VERSION ""

NS_ :

BS_:

BU_: CLOCK HUD H_U DATC CCP KMA_TMU CUBIS TMU IPM RSE_R RRC CGW RSE_L AMP EDT SWRC IBOX CLU FHCU ASD MON AVM KBD

BO_ 3221225472 VECTOR__INDEPENDENT_SIG_MSG: 0 Vector__XXX
 SG_ C_WHEEL_FL : 0|12@0+ (1,0) [0|0] "" Vector__XXX
 SG_ C_WHEEL_FR : 0|12@0+ (1,0) [0|0] "" Vector__XXX
 SG_ C_WHEEL_RL : 0|12@0+ (1,0) [0|0] "" Vector__XXX
 SG_ C_WHEEL_RR : 0|12@0+ (1,0) [0|0] "" Vector__XXX

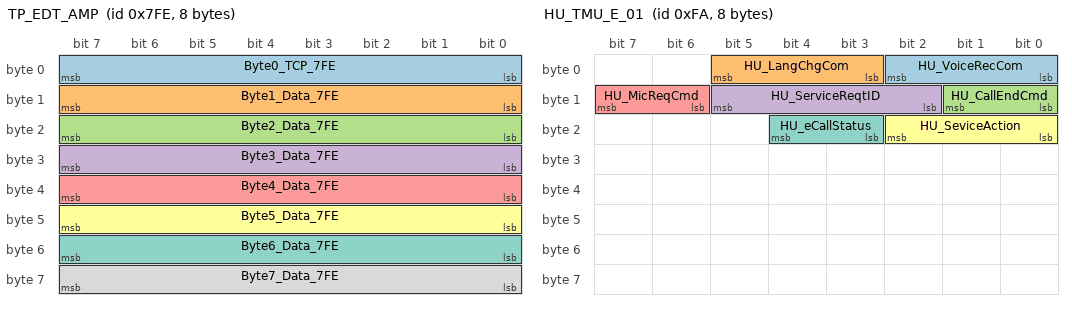
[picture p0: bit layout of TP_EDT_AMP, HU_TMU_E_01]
BO_ 2046 TP_EDT_AMP: 8 EDT
 SG_ Byte0_TCP_7FE : 7|8@0+ (1,0) [0|0] ""  AMP
 SG_ Byte1_Data_7FE : 15|8@0+ (1,0) [0|0] ""  AMP
 SG_ Byte2_Data_7FE : 23|8@0+ (1,0) [0|0] ""  AMP
 SG_ Byte3_Data_7FE : 31|8@0+ (1,0) [0|0] ""  AMP
 SG_ Byte4_Data_7FE : 39|8@0+ (1,0) [0|0] ""  AMP
 SG_ Byte5_Data_7FE : 47|8@0+ (1,0) [0|0] ""  AMP
 SG_ Byte6_Data_7FE : 55|8@0+ (1,0) [0|0] ""  AMP
 SG_ Byte7_Data_7FE : 63|8@0+ (1,0) [0|0] ""  AMP

BO_ 251 HU_TMU_E_02: 8 H_U
 SG_ HU_GPS_Year : 7|8@0+ (1,0) [0|0] ""  CUBIS,TMU
 SG_ HU_GPS_Month : 15|8@0+ (1,0) [0|0] ""  CUBIS,TMU
 SG_ HU_GPS_Day : 23|8@0+ (1,0) [0|0] ""  CUBIS,TMU
 SG_ HU_GPS_Hour : 31|8@0+ (1,0) [0|0] ""  CUBIS,TMU
 SG_ HU_GPS_Minute : 39|8@0+ (1,0) [0|0] ""  CUBIS,TMU
 SG_ HU_GPS_Second : 47|8@0+ (1,0) [0|0] ""  CUBIS,TMU

BO_ 250 HU_TMU_E_01: 8 H_U
 SG_ HU_VoiceRecCom : 2|3@0+ (1,0) [0|0] ""  TMU
 SG_ HU_LangChgCom : 5|3@0+ (1,0) [0|0] ""  TMU
 SG_ HU_CallEndCmd : 9|2@0+ (1,0) [0|0] ""  TMU
 SG_ HU_ServiceReqtID : 13|4@0+ (1,0) [0|0] ""  TMU
 SG_ HU_MicReqCmd : 15|2@0+ (1,0) [0|0] ""  TMU
 SG_ HU_SeviceAction : 18|3@0+ (1,0) [0|0] ""  TMU
 SG_ HU_eCallStatus : 20|2@0+ (1,0) [0|0] ""  TMU

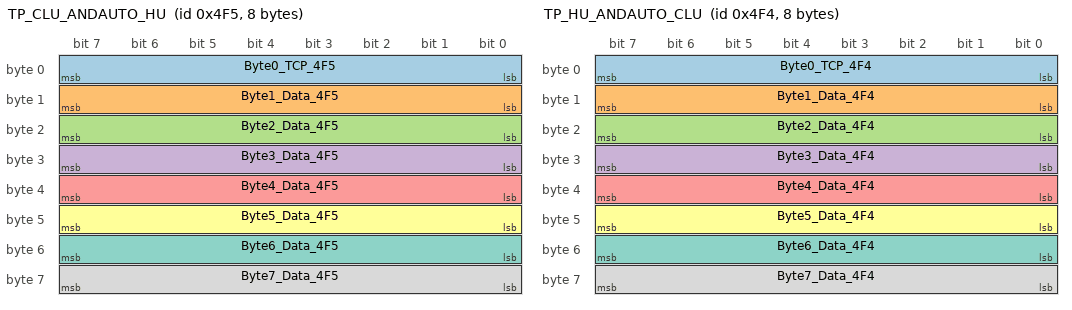
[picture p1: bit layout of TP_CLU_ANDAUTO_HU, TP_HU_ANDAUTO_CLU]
BO_ 1269 TP_CLU_ANDAUTO_HU: 8 CLU
 SG_ Byte0_TCP_4F5 : 7|8@0+ (1,0) [0|0] ""  H_U
 SG_ Byte1_Data_4F5 : 15|8@0+ (1,0) [0|0] ""  H_U
 SG_ Byte2_Data_4F5 : 23|8@0+ (1,0) [0|0] ""  H_U
 SG_ Byte3_Data_4F5 : 31|8@0+ (1,0) [0|0] ""  H_U
 SG_ Byte4_Data_4F5 : 39|8@0+ (1,0) [0|0] ""  H_U
 SG_ Byte5_Data_4F5 : 47|8@0+ (1,0) [0|0] ""  H_U
 SG_ Byte6_Data_4F5 : 55|8@0+ (1,0) [0|0] ""  H_U
 SG_ Byte7_Data_4F5 : 63|8@0+ (1,0) [0|0] ""  H_U

BO_ 1268 TP_HU_ANDAUTO_CLU: 8 H_U
 SG_ Byte0_TCP_4F4 : 7|8@0+ (1,0) [0|0] ""  CLU
 SG_ Byte1_Data_4F4 : 15|8@0+ (1,0) [0|0] ""  CLU
 SG_ Byte2_Data_4F4 : 23|8@0+ (1,0) [0|0] ""  CLU
 SG_ Byte3_Data_4F4 : 31|8@0+ (1,0) [0|0] ""  CLU
 SG_ Byte4_Data_4F4 : 39|8@0+ (1,0) [0|0] ""  CLU
 SG_ Byte5_Data_4F4 : 47|8@0+ (1,0) [0|0] ""  CLU
 SG_ Byte6_Data_4F4 : 55|8@0+ (1,0) [0|0] ""  CLU
 SG_ Byte7_Data_4F4 : 63|8@0+ (1,0) [0|0] ""  CLU

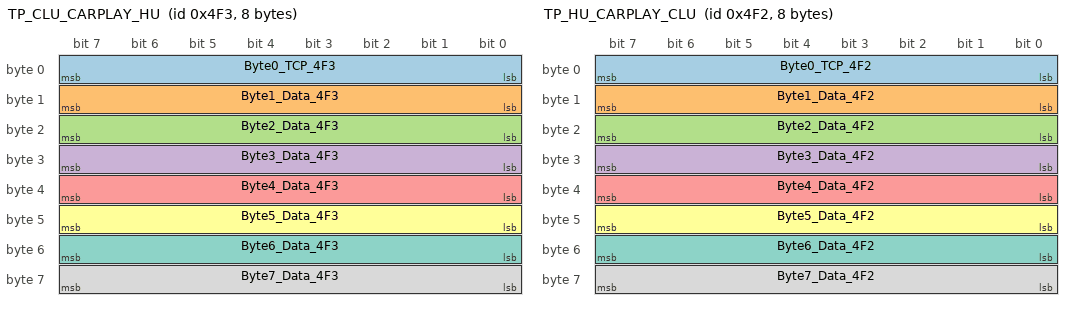
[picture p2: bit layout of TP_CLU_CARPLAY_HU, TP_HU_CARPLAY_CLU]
BO_ 1267 TP_CLU_CARPLAY_HU: 8 CLU
 SG_ Byte0_TCP_4F3 : 7|8@0+ (1,0) [0|0] ""  H_U
 SG_ Byte1_Data_4F3 : 15|8@0+ (1,0) [0|0] ""  H_U
 SG_ Byte2_Data_4F3 : 23|8@0+ (1,0) [0|0] ""  H_U
 SG_ Byte3_Data_4F3 : 31|8@0+ (1,0) [0|0] ""  H_U
 SG_ Byte4_Data_4F3 : 39|8@0+ (1,0) [0|0] ""  H_U
 SG_ Byte5_Data_4F3 : 47|8@0+ (1,0) [0|0] ""  H_U
 SG_ Byte6_Data_4F3 : 55|8@0+ (1,0) [0|0] ""  H_U
 SG_ Byte7_Data_4F3 : 63|8@0+ (1,0) [0|0] ""  H_U

BO_ 1266 TP_HU_CARPLAY_CLU: 8 H_U
 SG_ Byte0_TCP_4F2 : 7|8@0+ (1,0) [0|0] ""  CLU
 SG_ Byte1_Data_4F2 : 15|8@0+ (1,0) [0|0] ""  CLU
 SG_ Byte2_Data_4F2 : 23|8@0+ (1,0) [0|0] ""  CLU
 SG_ Byte3_Data_4F2 : 31|8@0+ (1,0) [0|0] ""  CLU
 SG_ Byte4_Data_4F2 : 39|8@0+ (1,0) [0|0] ""  CLU
 SG_ Byte5_Data_4F2 : 47|8@0+ (1,0) [0|0] ""  CLU
 SG_ Byte6_Data_4F2 : 55|8@0+ (1,0) [0|0] ""  CLU
 SG_ Byte7_Data_4F2 : 63|8@0+ (1,0) [0|0] ""  CLU

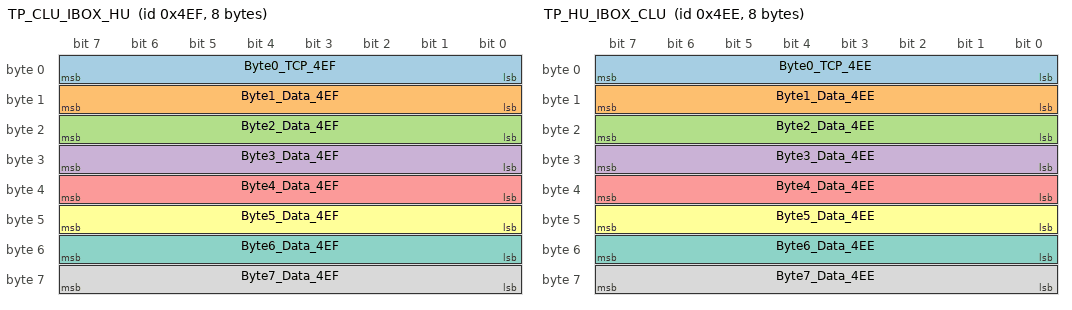
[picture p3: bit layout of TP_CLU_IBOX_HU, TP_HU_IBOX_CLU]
BO_ 1263 TP_CLU_IBOX_HU: 8 CLU
 SG_ Byte0_TCP_4EF : 7|8@0+ (1,0) [0|0] ""  H_U
 SG_ Byte1_Data_4EF : 15|8@0+ (1,0) [0|0] ""  H_U
 SG_ Byte2_Data_4EF : 23|8@0+ (1,0) [0|0] ""  H_U
 SG_ Byte3_Data_4EF : 31|8@0+ (1,0) [0|0] ""  H_U
 SG_ Byte4_Data_4EF : 39|8@0+ (1,0) [0|0] ""  H_U
 SG_ Byte5_Data_4EF : 47|8@0+ (1,0) [0|0] ""  H_U
 SG_ Byte6_Data_4EF : 55|8@0+ (1,0) [0|0] ""  H_U
 SG_ Byte7_Data_4EF : 63|8@0+ (1,0) [0|0] ""  H_U

BO_ 1262 TP_HU_IBOX_CLU: 8 H_U
 SG_ Byte0_TCP_4EE : 7|8@0+ (1,0) [0|0] ""  CLU
 SG_ Byte1_Data_4EE : 15|8@0+ (1,0) [0|0] ""  CLU
 SG_ Byte2_Data_4EE : 23|8@0+ (1,0) [0|0] ""  CLU
 SG_ Byte3_Data_4EE : 31|8@0+ (1,0) [0|0] ""  CLU
 SG_ Byte4_Data_4EE : 39|8@0+ (1,0) [0|0] ""  CLU
 SG_ Byte5_Data_4EE : 47|8@0+ (1,0) [0|0] ""  CLU
 SG_ Byte6_Data_4EE : 55|8@0+ (1,0) [0|0] ""  CLU
 SG_ Byte7_Data_4EE : 63|8@0+ (1,0) [0|0] ""  CLU

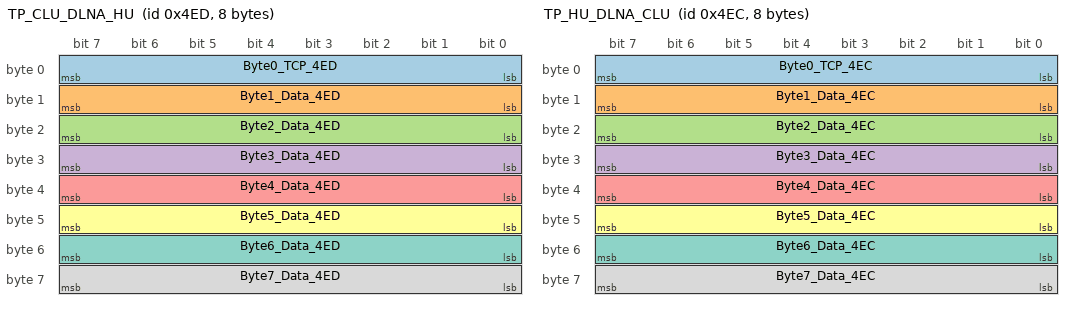
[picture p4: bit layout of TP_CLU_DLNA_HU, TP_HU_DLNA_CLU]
BO_ 1261 TP_CLU_DLNA_HU: 8 CLU
 SG_ Byte0_TCP_4ED : 7|8@0+ (1,0) [0|0] ""  H_U
 SG_ Byte1_Data_4ED : 15|8@0+ (1,0) [0|0] ""  H_U
 SG_ Byte2_Data_4ED : 23|8@0+ (1,0) [0|0] ""  H_U
 SG_ Byte3_Data_4ED : 31|8@0+ (1,0) [0|0] ""  H_U
 SG_ Byte4_Data_4ED : 39|8@0+ (1,0) [0|0] ""  H_U
 SG_ Byte5_Data_4ED : 47|8@0+ (1,0) [0|0] ""  H_U
 SG_ Byte6_Data_4ED : 55|8@0+ (1,0) [0|0] ""  H_U
 SG_ Byte7_Data_4ED : 63|8@0+ (1,0) [0|0] ""  H_U

BO_ 1260 TP_HU_DLNA_CLU: 8 H_U
 SG_ Byte0_TCP_4EC : 7|8@0+ (1,0) [0|0] ""  CLU
 SG_ Byte1_Data_4EC : 15|8@0+ (1,0) [0|0] ""  CLU
 SG_ Byte2_Data_4EC : 23|8@0+ (1,0) [0|0] ""  CLU
 SG_ Byte3_Data_4EC : 31|8@0+ (1,0) [0|0] ""  CLU
 SG_ Byte4_Data_4EC : 39|8@0+ (1,0) [0|0] ""  CLU
 SG_ Byte5_Data_4EC : 47|8@0+ (1,0) [0|0] ""  CLU
 SG_ Byte6_Data_4EC : 55|8@0+ (1,0) [0|0] ""  CLU
 SG_ Byte7_Data_4EC : 63|8@0+ (1,0) [0|0] ""  CLU

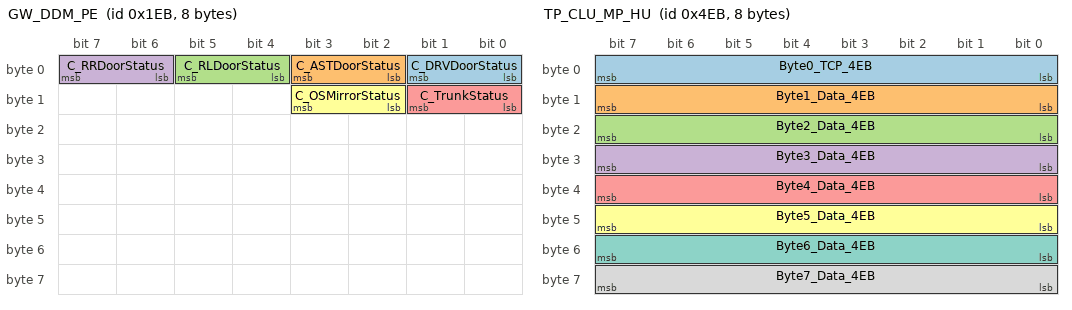
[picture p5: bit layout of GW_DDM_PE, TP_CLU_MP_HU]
BO_ 491 GW_DDM_PE: 8 CLU
 SG_ C_DRVDoorStatus : 1|2@0+ (1,0) [0|0] ""  AMP,ASD,AVM,CCP,CGW,CLOCK,CUBIS,DATC,EDT,FHCU,HUD,H_U,IBOX,IPM,KBD,KMA_TMU,MON,RRC,RSE_L,RSE_R,SWRC,TMU
 SG_ C_ASTDoorStatus : 3|2@0+ (1,0) [0|0] ""  AMP,ASD,AVM,CCP,CGW,CLOCK,CUBIS,DATC,EDT,FHCU,HUD,H_U,IBOX,IPM,KBD,KMA_TMU,MON,RRC,RSE_L,RSE_R,SWRC,TMU
 SG_ C_RLDoorStatus : 5|2@0+ (1,0) [0|0] ""  AMP,ASD,AVM,CCP,CGW,CLOCK,CUBIS,DATC,EDT,FHCU,HUD,H_U,IBOX,IPM,KBD,KMA_TMU,MON,RRC,RSE_L,RSE_R,SWRC,TMU
 SG_ C_RRDoorStatus : 7|2@0+ (1,0) [0|0] ""  AMP,ASD,AVM,CCP,CGW,CLOCK,CUBIS,DATC,EDT,FHCU,HUD,H_U,IBOX,IPM,KBD,KMA_TMU,MON,RRC,RSE_L,RSE_R,SWRC,TMU
 SG_ C_TrunkStatus : 9|2@0+ (1,0) [0|0] ""  AMP,ASD,AVM,CCP,CGW,CLOCK,CUBIS,DATC,EDT,FHCU,HUD,H_U,IBOX,IPM,KBD,KMA_TMU,MON,RRC,RSE_L,RSE_R,SWRC,TMU
 SG_ C_OSMirrorStatus : 11|2@0+ (1,0) [0|0] ""  AMP,ASD,AVM,CCP,CGW,CLOCK,CUBIS,DATC,EDT,FHCU,HUD,H_U,IBOX,IPM,KBD,KMA_TMU,MON,RRC,RSE_L,RSE_R,SWRC,TMU

BO_ 1259 TP_CLU_MP_HU: 8 CLU
 SG_ Byte0_TCP_4EB : 7|8@0+ (1,0) [0|0] ""  H_U
 SG_ Byte1_Data_4EB : 15|8@0+ (1,0) [0|0] ""  H_U
 SG_ Byte2_Data_4EB : 23|8@0+ (1,0) [0|0] ""  H_U
 SG_ Byte3_Data_4EB : 31|8@0+ (1,0) [0|0] ""  H_U
 SG_ Byte4_Data_4EB : 39|8@0+ (1,0) [0|0] ""  H_U
 SG_ Byte5_Data_4EB : 47|8@0+ (1,0) [0|0] ""  H_U
 SG_ Byte6_Data_4EB : 55|8@0+ (1,0) [0|0] ""  H_U
 SG_ Byte7_Data_4EB : 63|8@0+ (1,0) [0|0] ""  H_U

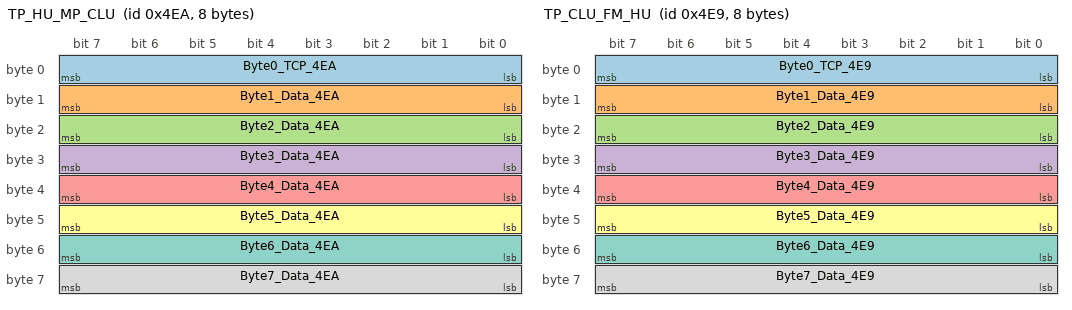
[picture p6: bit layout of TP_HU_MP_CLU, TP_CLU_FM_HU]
BO_ 1258 TP_HU_MP_CLU: 8 H_U
 SG_ Byte0_TCP_4EA : 7|8@0+ (1,0) [0|0] ""  CLU
 SG_ Byte1_Data_4EA : 15|8@0+ (1,0) [0|0] ""  CLU
 SG_ Byte2_Data_4EA : 23|8@0+ (1,0) [0|0] ""  CLU
 SG_ Byte3_Data_4EA : 31|8@0+ (1,0) [0|0] ""  CLU
 SG_ Byte4_Data_4EA : 39|8@0+ (1,0) [0|0] ""  CLU
 SG_ Byte5_Data_4EA : 47|8@0+ (1,0) [0|0] ""  CLU
 SG_ Byte6_Data_4EA : 55|8@0+ (1,0) [0|0] ""  CLU
 SG_ Byte7_Data_4EA : 63|8@0+ (1,0) [0|0] ""  CLU

BO_ 1257 TP_CLU_FM_HU: 8 CLU
 SG_ Byte0_TCP_4E9 : 7|8@0+ (1,0) [0|0] ""  H_U
 SG_ Byte1_Data_4E9 : 15|8@0+ (1,0) [0|0] ""  H_U
 SG_ Byte2_Data_4E9 : 23|8@0+ (1,0) [0|0] ""  H_U
 SG_ Byte3_Data_4E9 : 31|8@0+ (1,0) [0|0] ""  H_U
 SG_ Byte4_Data_4E9 : 39|8@0+ (1,0) [0|0] ""  H_U
 SG_ Byte5_Data_4E9 : 47|8@0+ (1,0) [0|0] ""  H_U
 SG_ Byte6_Data_4E9 : 55|8@0+ (1,0) [0|0] ""  H_U
 SG_ Byte7_Data_4E9 : 63|8@0+ (1,0) [0|0] ""  H_U

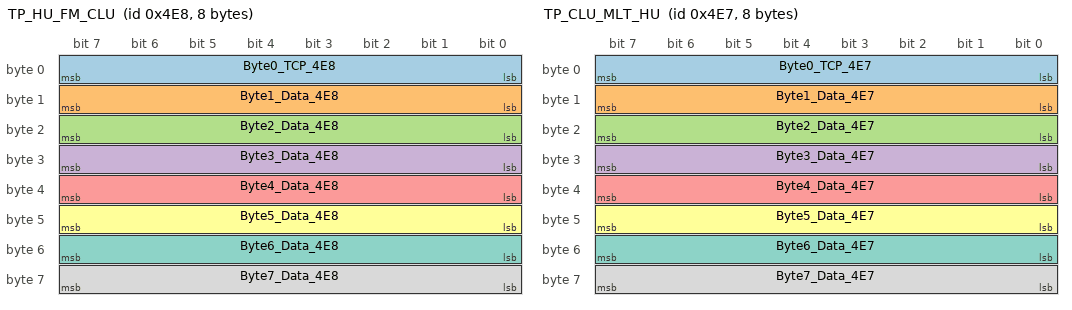
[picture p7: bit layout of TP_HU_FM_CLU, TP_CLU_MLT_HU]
BO_ 1256 TP_HU_FM_CLU: 8 H_U
 SG_ Byte0_TCP_4E8 : 7|8@0+ (1,0) [0|0] ""  CLU
 SG_ Byte1_Data_4E8 : 15|8@0+ (1,0) [0|0] ""  CLU
 SG_ Byte2_Data_4E8 : 23|8@0+ (1,0) [0|0] ""  CLU
 SG_ Byte3_Data_4E8 : 31|8@0+ (1,0) [0|0] ""  CLU
 SG_ Byte4_Data_4E8 : 39|8@0+ (1,0) [0|0] ""  CLU
 SG_ Byte5_Data_4E8 : 47|8@0+ (1,0) [0|0] ""  CLU
 SG_ Byte6_Data_4E8 : 55|8@0+ (1,0) [0|0] ""  CLU
 SG_ Byte7_Data_4E8 : 63|8@0+ (1,0) [0|0] ""  CLU

BO_ 1255 TP_CLU_MLT_HU: 8 CLU
 SG_ Byte0_TCP_4E7 : 7|8@0+ (1,0) [0|0] ""  H_U
 SG_ Byte1_Data_4E7 : 15|8@0+ (1,0) [0|0] ""  H_U
 SG_ Byte2_Data_4E7 : 23|8@0+ (1,0) [0|0] ""  H_U
 SG_ Byte3_Data_4E7 : 31|8@0+ (1,0) [0|0] ""  H_U
 SG_ Byte4_Data_4E7 : 39|8@0+ (1,0) [0|0] ""  H_U
 SG_ Byte5_Data_4E7 : 47|8@0+ (1,0) [0|0] ""  H_U
 SG_ Byte6_Data_4E7 : 55|8@0+ (1,0) [0|0] ""  H_U
 SG_ Byte7_Data_4E7 : 63|8@0+ (1,0) [0|0] ""  H_U

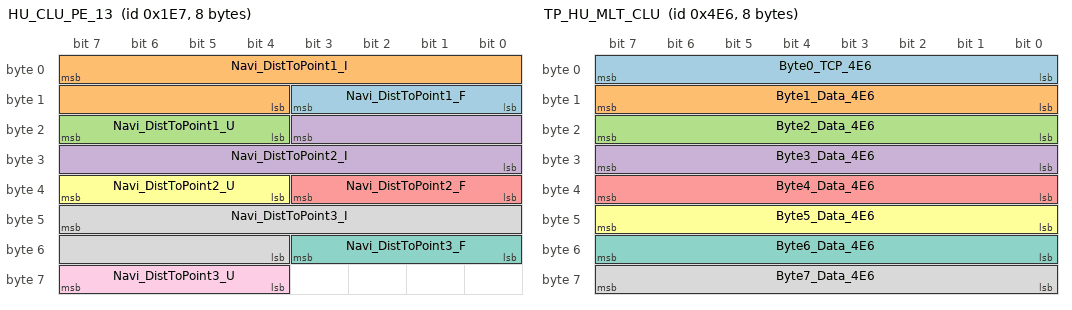
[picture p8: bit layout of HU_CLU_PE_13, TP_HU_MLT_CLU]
BO_ 487 HU_CLU_PE_13: 8 H_U
 SG_ Navi_DistToPoint1_F : 11|4@0+ (1,0) [0|0] ""  CLU,HUD
 SG_ Navi_DistToPoint1_I : 7|12@0+ (1,0) [0|0] ""  CLU,HUD
 SG_ Navi_DistToPoint1_U : 23|4@0+ (1,0) [0|0] ""  CLU,HUD
 SG_ Navi_DistToPoint2_I : 19|12@0+ (1,0) [0|0] ""  CLU,HUD
 SG_ Navi_DistToPoint2_F : 35|4@0+ (1,0) [0|0] ""  CLU,HUD
 SG_ Navi_DistToPoint2_U : 39|4@0+ (1,0) [0|0] ""  CLU,HUD
 SG_ Navi_DistToPoint3_F : 51|4@0+ (1,0) [0|0] ""  CLU,HUD
 SG_ Navi_DistToPoint3_I : 47|12@0+ (1,0) [0|0] ""  CLU,HUD
 SG_ Navi_DistToPoint3_U : 63|4@0+ (1,0) [0|0] ""  CLU,HUD

BO_ 1254 TP_HU_MLT_CLU: 8 H_U
 SG_ Byte0_TCP_4E6 : 7|8@0+ (1,0) [0|0] ""  CLU
 SG_ Byte1_Data_4E6 : 15|8@0+ (1,0) [0|0] ""  CLU
 SG_ Byte2_Data_4E6 : 23|8@0+ (1,0) [0|0] ""  CLU
 SG_ Byte3_Data_4E6 : 31|8@0+ (1,0) [0|0] ""  CLU
 SG_ Byte4_Data_4E6 : 39|8@0+ (1,0) [0|0] ""  CLU
 SG_ Byte5_Data_4E6 : 47|8@0+ (1,0) [0|0] ""  CLU
 SG_ Byte6_Data_4E6 : 55|8@0+ (1,0) [0|0] ""  CLU
 SG_ Byte7_Data_4E6 : 63|8@0+ (1,0) [0|0] ""  CLU

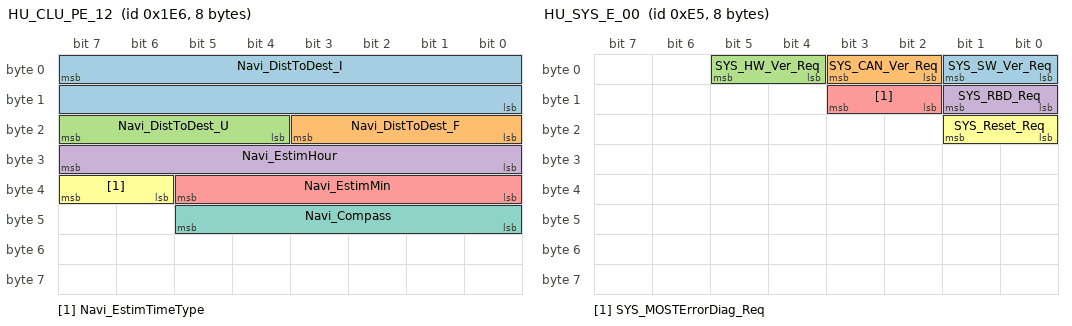
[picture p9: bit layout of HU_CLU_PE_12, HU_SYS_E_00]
BO_ 486 HU_CLU_PE_12: 8 H_U
 SG_ Navi_DistToDest_I : 7|16@0+ (1,0) [0|0] ""  CLU,HUD
 SG_ Navi_DistToDest_F : 19|4@0+ (1,0) [0|0] ""  CLU,HUD
 SG_ Navi_DistToDest_U : 23|4@0+ (1,0) [0|0] ""  CLU,HUD
 SG_ Navi_EstimHour : 31|8@0+ (1,0) [0|254] "hh"  CLU,HUD
 SG_ Navi_EstimMin : 37|6@0+ (1,0) [0|59] "mm"  CLU,HUD
 SG_ Navi_EstimTimeType : 39|2@0+ (1,0) [0|0] ""  CLU,HUD
 SG_ Navi_Compass : 45|6@0+ (7.5,-7.5) [0|352.5] "Degree"  CLU,HUD

BO_ 229 HU_SYS_E_00: 8 H_U
 SG_ SYS_SW_Ver_Req : 1|2@0+ (1,0) [0|0] ""  AMP,CCP,CGW,CLOCK,CLU,HUD,IBOX,RRC,RSE_L
 SG_ SYS_CAN_Ver_Req : 3|2@0+ (1,0) [0|0] ""  AMP,CCP,CGW,CLOCK,CLU,HUD,IBOX,RRC,RSE_L
 SG_ SYS_HW_Ver_Req : 5|2@0+ (1,0) [0|0] ""  AMP,CCP,CGW,CLOCK,CLU,IBOX,RRC
 SG_ SYS_RBD_Req : 9|2@0+ (1,0) [0|0] ""  AMP,IBOX
 SG_ SYS_MOSTErrorDiag_Req : 11|2@0+ (1,0) [0|0] ""  AMP,IBOX
 SG_ SYS_Reset_Req : 17|2@0+ (1,0) [0|0] ""  AMP,IBOX

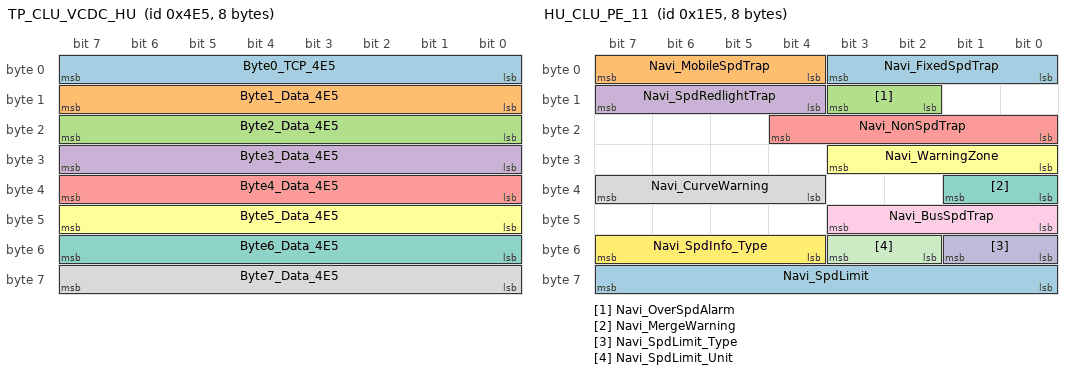
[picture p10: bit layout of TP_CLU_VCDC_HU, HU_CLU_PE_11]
BO_ 1253 TP_CLU_VCDC_HU: 8 CLU
 SG_ Byte0_TCP_4E5 : 7|8@0+ (1,0) [0|0] ""  H_U
 SG_ Byte1_Data_4E5 : 15|8@0+ (1,0) [0|0] ""  H_U
 SG_ Byte2_Data_4E5 : 23|8@0+ (1,0) [0|0] ""  H_U
 SG_ Byte3_Data_4E5 : 31|8@0+ (1,0) [0|0] ""  H_U
 SG_ Byte4_Data_4E5 : 39|8@0+ (1,0) [0|0] ""  H_U
 SG_ Byte5_Data_4E5 : 47|8@0+ (1,0) [0|0] ""  H_U
 SG_ Byte6_Data_4E5 : 55|8@0+ (1,0) [0|0] ""  H_U
 SG_ Byte7_Data_4E5 : 63|8@0+ (1,0) [0|0] ""  H_U

BO_ 485 HU_CLU_PE_11: 8 H_U
 SG_ Navi_FixedSpdTrap : 3|4@0+ (10,0) [10|110] "Km/h"  CLU,HUD
 SG_ Navi_MobileSpdTrap : 7|4@0+ (10,0) [10|110] "Km/h"  CLU,HUD
 SG_ Navi_OverSpdAlarm : 11|2@0+ (1,0) [0|0] ""  CGW,CLU,HUD
 SG_ Navi_SpdRedlightTrap : 15|4@0+ (10,0) [10|110] "Km/h"  CLU,HUD
 SG_ Navi_NonSpdTrap : 20|5@0+ (1,0) [0|0] ""  CLU,HUD
 SG_ Navi_WarningZone : 27|4@0+ (1,0) [0|0] ""  CLU,HUD
 SG_ Navi_MergeWarning : 33|2@0+ (1,0) [0|0] ""  CLU,HUD
 SG_ Navi_CurveWarning : 39|4@0+ (1,0) [0|0] ""  CLU,HUD
 SG_ Navi_BusSpdTrap : 43|4@0+ (10,0) [10|110] "Km/h"  CLU,HUD
 SG_ Navi_SpdLimit_Type : 49|2@0+ (1,0) [0|0] ""  CLU,HUD
 SG_ Navi_SpdLimit_Unit : 51|2@0+ (1,0) [0|0] ""  CLU,HUD
 SG_ Navi_SpdInfo_Type : 55|4@0+ (1,0) [0|0] ""  CLU,HUD
 SG_ Navi_SpdLimit : 63|8@0+ (1,0) [1|254] ""  CLU,HUD

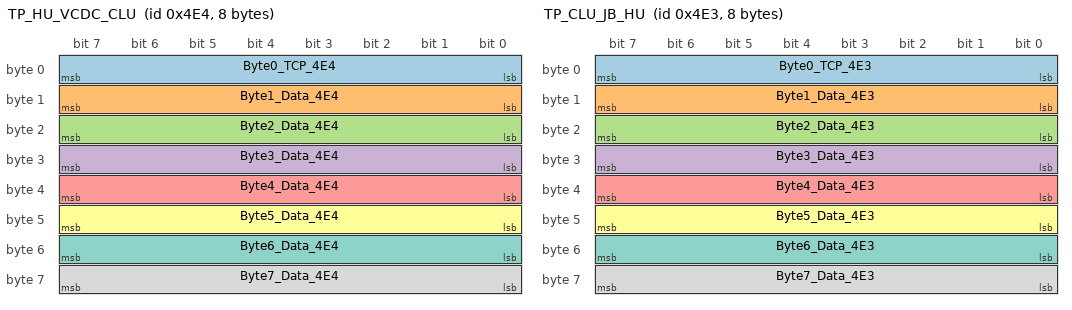
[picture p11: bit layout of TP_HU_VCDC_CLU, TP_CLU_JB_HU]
BO_ 1252 TP_HU_VCDC_CLU: 8 H_U
 SG_ Byte0_TCP_4E4 : 7|8@0+ (1,0) [0|0] ""  CLU
 SG_ Byte1_Data_4E4 : 15|8@0+ (1,0) [0|0] ""  CLU
 SG_ Byte2_Data_4E4 : 23|8@0+ (1,0) [0|0] ""  CLU
 SG_ Byte3_Data_4E4 : 31|8@0+ (1,0) [0|0] ""  CLU
 SG_ Byte4_Data_4E4 : 39|8@0+ (1,0) [0|0] ""  CLU
 SG_ Byte5_Data_4E4 : 47|8@0+ (1,0) [0|0] ""  CLU
 SG_ Byte6_Data_4E4 : 55|8@0+ (1,0) [0|0] ""  CLU
 SG_ Byte7_Data_4E4 : 63|8@0+ (1,0) [0|0] ""  CLU

BO_ 1251 TP_CLU_JB_HU: 8 CLU
 SG_ Byte0_TCP_4E3 : 7|8@0+ (1,0) [0|0] ""  H_U
 SG_ Byte1_Data_4E3 : 15|8@0+ (1,0) [0|0] ""  H_U
 SG_ Byte2_Data_4E3 : 23|8@0+ (1,0) [0|0] ""  H_U
 SG_ Byte3_Data_4E3 : 31|8@0+ (1,0) [0|0] ""  H_U
 SG_ Byte4_Data_4E3 : 39|8@0+ (1,0) [0|0] ""  H_U
 SG_ Byte5_Data_4E3 : 47|8@0+ (1,0) [0|0] ""  H_U
 SG_ Byte6_Data_4E3 : 55|8@0+ (1,0) [0|0] ""  H_U
 SG_ Byte7_Data_4E3 : 63|8@0+ (1,0) [0|0] ""  H_U

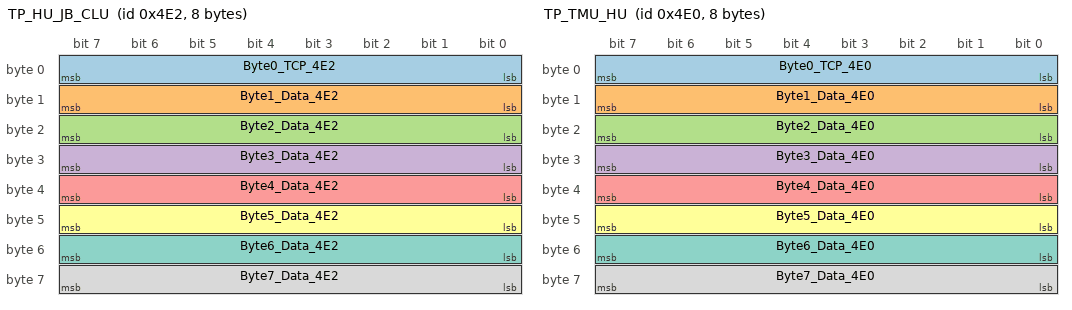
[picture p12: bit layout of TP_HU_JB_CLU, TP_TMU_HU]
BO_ 1250 TP_HU_JB_CLU: 8 H_U
 SG_ Byte0_TCP_4E2 : 7|8@0+ (1,0) [0|0] ""  CLU
 SG_ Byte1_Data_4E2 : 15|8@0+ (1,0) [0|0] ""  CLU
 SG_ Byte2_Data_4E2 : 23|8@0+ (1,0) [0|0] ""  CLU
 SG_ Byte3_Data_4E2 : 31|8@0+ (1,0) [0|0] ""  CLU
 SG_ Byte4_Data_4E2 : 39|8@0+ (1,0) [0|0] ""  CLU
 SG_ Byte5_Data_4E2 : 47|8@0+ (1,0) [0|0] ""  CLU
 SG_ Byte6_Data_4E2 : 55|8@0+ (1,0) [0|0] ""  CLU
 SG_ Byte7_Data_4E2 : 63|8@0+ (1,0) [0|0] ""  CLU

BO_ 1248 TP_TMU_HU: 8 TMU
 SG_ Byte0_TCP_4E0 : 7|8@0+ (1,0) [0|0] ""  H_U
 SG_ Byte1_Data_4E0 : 15|8@0+ (1,0) [0|0] ""  H_U
 SG_ Byte2_Data_4E0 : 23|8@0+ (1,0) [0|0] ""  H_U
 SG_ Byte3_Data_4E0 : 31|8@0+ (1,0) [0|0] ""  H_U
 SG_ Byte4_Data_4E0 : 39|8@0+ (1,0) [0|0] ""  H_U
 SG_ Byte5_Data_4E0 : 47|8@0+ (1,0) [0|0] ""  H_U
 SG_ Byte6_Data_4E0 : 55|8@0+ (1,0) [0|0] ""  H_U
 SG_ Byte7_Data_4E0 : 63|8@0+ (1,0) [0|0] ""  H_U

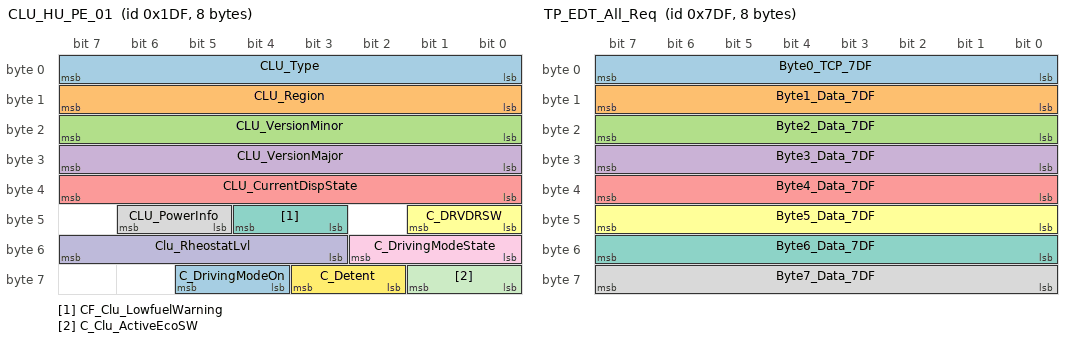
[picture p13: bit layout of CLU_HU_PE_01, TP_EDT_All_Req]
BO_ 479 CLU_HU_PE_01: 8 CLU
 SG_ CLU_Type : 7|8@0+ (1,0) [0|0] ""  H_U
 SG_ CLU_Region : 15|8@0+ (1,0) [0|0] ""  H_U
 SG_ CLU_VersionMinor : 23|8@0+ (1,0) [0|0] ""  H_U
 SG_ CLU_VersionMajor : 31|8@0+ (1,0) [0|0] ""  H_U
 SG_ CLU_CurrentDispState : 39|8@0+ (1,0) [0|0] ""  H_U
 SG_ C_DRVDRSW : 41|2@0+ (1,0) [0|0] ""  H_U
 SG_ CF_Clu_LowfuelWarning : 44|2@0+ (1,0) [0|0] ""  H_U
 SG_ CLU_PowerInfo : 46|2@0+ (1,0) [0|0] ""  H_U
 SG_ C_DrivingModeState : 50|3@0+ (1,0) [0|0] ""  H_U
 SG_ Clu_RheostatLvl : 55|5@0+ (1,0) [0|0] ""  H_U,MON,SWRC
 SG_ C_Clu_ActiveEcoSW : 57|2@0+ (1,0) [0|0] ""  H_U
 SG_ C_Detent : 59|2@0+ (1,0) [0|0] ""  CCP,CLOCK,H_U,KBD,MON,RRC,RSE_L,RSE_R
 SG_ C_DrivingModeOn : 61|2@0+ (1,0) [0|0] ""  H_U

BO_ 2015 TP_EDT_All_Req: 8 EDT
 SG_ Byte0_TCP_7DF : 7|8@0+ (1,0) [0|0] ""  AMP,ASD,AVM,CCP,CGW,CLOCK,CLU,CUBIS,DATC,FHCU,HUD,H_U,IBOX,IPM,KBD,KMA_TMU,MON,RRC,RSE_L,RSE_R,TMU
 SG_ Byte1_Data_7DF : 15|8@0+ (1,0) [0|0] ""  AMP,ASD,AVM,CCP,CGW,CLOCK,CLU,CUBIS,DATC,FHCU,HUD,H_U,IBOX,IPM,KBD,KMA_TMU,MON,RRC,RSE_L,RSE_R,TMU
 SG_ Byte2_Data_7DF : 23|8@0+ (1,0) [0|0] ""  AMP,ASD,AVM,CCP,CGW,CLOCK,CLU,CUBIS,DATC,FHCU,HUD,H_U,IBOX,IPM,KBD,KMA_TMU,MON,RRC,RSE_L,RSE_R,TMU
 SG_ Byte3_Data_7DF : 31|8@0+ (1,0) [0|0] ""  AMP,ASD,AVM,CCP,CGW,CLOCK,CLU,CUBIS,DATC,FHCU,HUD,H_U,IBOX,IPM,KBD,KMA_TMU,MON,RRC,RSE_L,RSE_R,TMU
 SG_ Byte4_Data_7DF : 39|8@0+ (1,0) [0|0] ""  AMP,ASD,AVM,CCP,CGW,CLOCK,CLU,CUBIS,DATC,FHCU,HUD,H_U,IBOX,IPM,KBD,KMA_TMU,MON,RRC,RSE_L,RSE_R,TMU
 SG_ Byte5_Data_7DF : 47|8@0+ (1,0) [0|0] ""  AMP,ASD,AVM,CCP,CGW,CLOCK,CLU,CUBIS,DATC,FHCU,HUD,H_U,IBOX,IPM,KBD,KMA_TMU,MON,RRC,RSE_L,RSE_R,TMU
 SG_ Byte6_Data_7DF : 55|8@0+ (1,0) [0|0] ""  AMP,ASD,AVM,CCP,CGW,CLOCK,CLU,CUBIS,DATC,FHCU,HUD,H_U,IBOX,IPM,KBD,KMA_TMU,MON,RRC,RSE_L,RSE_R,TMU
 SG_ Byte7_Data_7DF : 63|8@0+ (1,0) [0|0] ""  AMP,ASD,AVM,CCP,CGW,CLOCK,CLU,CUBIS,DATC,FHCU,HUD,H_U,IBOX,IPM,KBD,KMA_TMU,MON,RRC,RSE_L,RSE_R,TMU

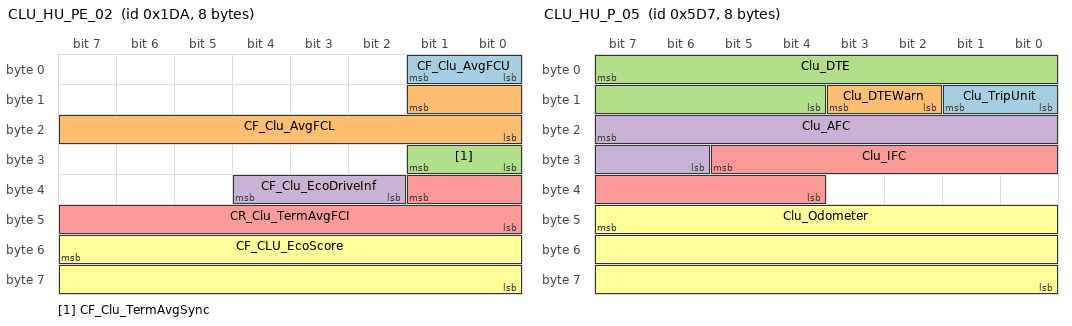
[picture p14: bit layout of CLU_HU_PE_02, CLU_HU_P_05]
BO_ 474 CLU_HU_PE_02: 8 CLU
 SG_ CF_Clu_AvgFCU : 1|2@0+ (1,0) [0|0] ""  H_U
 SG_ CF_Clu_AvgFCL : 9|10@0+ (1,0) [0|0] ""  H_U
 SG_ CF_Clu_TermAvgSync : 25|2@0+ (1,0) [0|0] ""  H_U
 SG_ CF_Clu_EcoDriveInf : 36|3@0+ (1,0) [0|0] ""  H_U
 SG_ CR_Clu_TermAvgFCI : 33|10@0+ (1,0) [0|0] ""  H_U
 SG_ CF_CLU_EcoScore : 55|16@0+ (1,0) [0|0] ""  H_U

BO_ 1495 CLU_HU_P_05: 8 CLU
 SG_ Clu_TripUnit : 9|2@0+ (1,0) [0|0] ""  H_U,IBOX
 SG_ Clu_DTEWarn : 11|2@0+ (1,0) [0|0] ""  H_U,IBOX
 SG_ Clu_DTE : 7|12@0+ (1,0) [0|1500] "km"  H_U,IBOX
 SG_ Clu_AFC : 23|10@0+ (0.1,0) [0|99.9] ""  H_U,IBOX
 SG_ Clu_IFC : 29|10@0+ (0.1,0) [0|99.9] ""  H_U,IBOX
 SG_ Clu_Odometer : 47|24@0+ (1,0) [0|999999] ""  H_U,IBOX

BO_ 1494 CLU_HU_P_01: 8 CLU
 SG_ CF_TripUnit : 13|2@0+ (1,0) [0|0] ""  H_U
 SG_ CF_DTE : 7|10@0+ (1,0) [0|0] ""  H_U

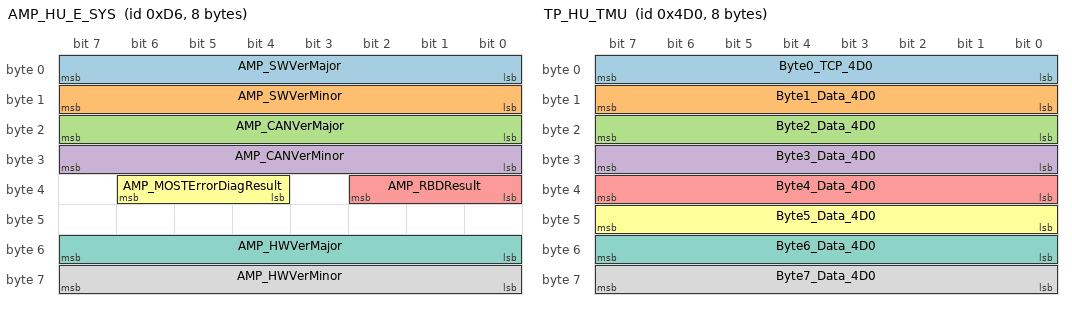
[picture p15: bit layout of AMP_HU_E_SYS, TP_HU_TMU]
BO_ 214 AMP_HU_E_SYS: 8 AMP
 SG_ AMP_SWVerMajor : 7|8@0+ (1,0) [0|254] ""  H_U,IBOX
 SG_ AMP_SWVerMinor : 15|8@0+ (1,0) [0|254] ""  H_U,IBOX
 SG_ AMP_CANVerMajor : 23|8@0+ (1,0) [0|254] ""  H_U,IBOX
 SG_ AMP_CANVerMinor : 31|8@0+ (1,0) [0|254] ""  H_U,IBOX
 SG_ AMP_RBDResult : 34|3@0+ (1,0) [0|0] ""  H_U
 SG_ AMP_MOSTErrorDiagResult : 38|3@0+ (1,0) [0|0] ""  H_U
 SG_ AMP_HWVerMajor : 55|8@0+ (1,0) [0|254] ""  H_U,IBOX
 SG_ AMP_HWVerMinor : 63|8@0+ (1,0) [0|254] ""  H_U,IBOX

BO_ 1492 CLU_HU_P_04: 8 CLU
 SG_ MM_CR_Fatc_AcnComCst_W : 7|10@0+ (10,0) [0|8000] "W"  H_U
 SG_ MM_CR_Ldc_PwrMon_W : 12|8@0+ (10,0) [0|2550] "W"  H_U
 SG_ MM_CR_Fatc_PTCPwrCon_W : 17|10@0+ (10,0) [0|10000] "W"  H_U
 SG_ MM_CR_BmsChgExp_T_Fast : 39|16@0+ (1,0) [0|0] "minute"  H_U
 SG_ MM_CR_BmsChgExp_T_Slow : 55|16@0+ (1,0) [0|0] "minute"  H_U

BO_ 1491 CLU_HU_P_03: 8 CLU
 SG_ MM_CF_Vcu_EvMod : 3|4@0+ (1,0) [0|0] ""  H_U
 SG_ MM_CF_Vcu_GarSelDisp : 7|4@0+ (999,0) [0|0] ""  H_U
 SG_ MM_CF_Vcu_ThiBatTir : 8|1@0+ (1,0) [0|0] ""  H_U
 SG_ CR_Mcu_MotEstTqPc : 23|10@0+ (0.2,-100) [-100|99.8] "%"  H_U
 SG_ CR_Mcu_MotActRotSpd_rpm : 39|16@0+ (1,-32768) [-32768|32767] "rpm"  H_U

BO_ 1490 CLU_HU_P_02: 8 CLU
 SG_ MM_CR_Vcu_EcoSco : 3|4@0+ (1,0) [0|0] ""  H_U
 SG_ MM_CF_Vcu_PgmRun5 : 5|2@0+ (1,0) [0|0] ""  H_U
 SG_ MM_CR_Clu_Odometer_kph : 15|24@0+ (0.1,0) [0|0] "km"  H_U

BO_ 1489 DATC_P_B_01: 8 CLU
 SG_ C_InhibitR_DATC : 51|1@0+ (1,0) [0|0] "" Vector__XXX
 SG_ C_InhibitP_DATC : 50|1@0+ (1,0) [0|0] "" Vector__XXX
 SG_ C_InhibitN_DATC : 49|1@0+ (1,0) [0|0] "" Vector__XXX
 SG_ C_InhibitD_DATC : 48|1@0+ (1,0) [0|0] "" Vector__XXX

BO_ 465 CLU_HU_PE_03: 8 CLU
 SG_ CF_Clu_EVDTEDisp : 0|9@0+ (1,0) [0|0] ""  H_U,IBOX
 SG_ CF_Clu_GasDTEDisp : 17|10@0+ (1,0) [0|0] ""  H_U,IBOX
 SG_ MM_CR_Clu_TotalDTEDisp : 34|11@0+ (1,0) [0|0] ""  H_U,IBOX
 SG_ CF_Clu_TripUnit : 49|2@0+ (1,0) [0|0] ""  H_U,IBOX

BO_ 1232 TP_HU_TMU: 8 H_U
 SG_ Byte0_TCP_4D0 : 7|8@0+ (1,0) [0|0] ""  TMU
 SG_ Byte1_Data_4D0 : 15|8@0+ (1,0) [0|0] ""  TMU
 SG_ Byte2_Data_4D0 : 23|8@0+ (1,0) [0|0] ""  TMU
 SG_ Byte3_Data_4D0 : 31|8@0+ (1,0) [0|0] ""  TMU
 SG_ Byte4_Data_4D0 : 39|8@0+ (1,0) [0|0] ""  TMU
 SG_ Byte5_Data_4D0 : 47|8@0+ (1,0) [0|0] ""  TMU
 SG_ Byte6_Data_4D0 : 55|8@0+ (1,0) [0|0] ""  TMU
 SG_ Byte7_Data_4D0 : 63|8@0+ (1,0) [0|0] ""  TMU

BO_ 1488 CLU_HU_P_00: 8 CLU
 SG_ MM_CR_Mcu_VehSpd_Kph : 7|8@0+ (1,0) [0|0] ""  H_U
 SG_ MM_CR_Mcu_VehSpdDec_Kph : 15|8@0+ (1,0) [0|0] ""  H_U
 SG_ MM_CR_Bms_Soc_Pc : 23|8@0+ (1,0) [0|0] ""  H_U
 SG_ MM_CR_Vcu_TqMotClu_Pc : 31|8@0+ (1,-127) [0|0] ""  H_U
 SG_ MM_CR_Bms_DrvEnaDist : 39|8@0+ (1,0) [0|0] ""  H_U
 SG_ MM_CR_Clu_Soc_Seg : 44|5@0+ (1,0) [0|0] ""  H_U,IBOX

BO_ 208 CLU_HU_E_SYS: 8 CLU
 SG_ CLU_SWVerMajor : 7|8@0+ (1,0) [0|254] ""  H_U
 SG_ CLU_SWVerMinor : 15|8@0+ (1,0) [0|254] ""  H_U
 SG_ CLU_CANVerMajor : 23|8@0+ (1,0) [0|254] ""  H_U
 SG_ CLU_CANVerMinor : 31|8@0+ (1,0) [0|254] ""  H_U
 SG_ CLU_HWVerMajor : 55|8@0+ (1,0) [0|254] ""  H_U
 SG_ CLU_HWVerMinor : 63|8@0+ (1,0) [0|254] ""  H_U

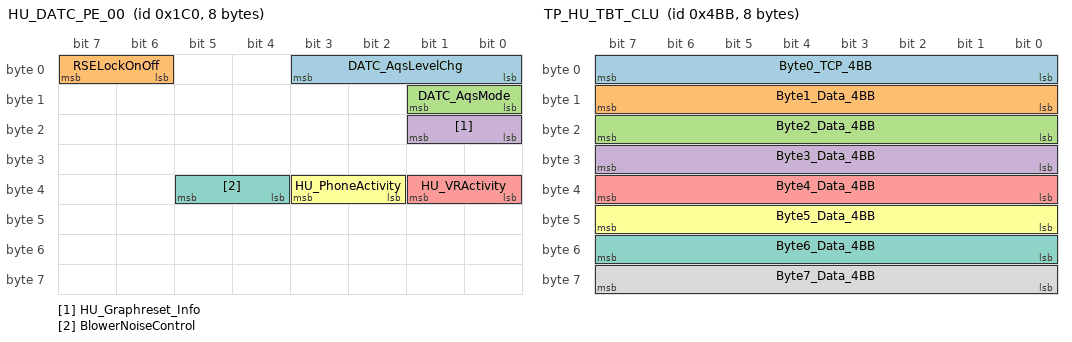
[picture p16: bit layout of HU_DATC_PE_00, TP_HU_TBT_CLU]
BO_ 448 HU_DATC_PE_00: 8 H_U
 SG_ DATC_AqsLevelChg : 3|4@0+ (1,0) [0|0] ""  CGW,CLU,DATC,IPM
 SG_ RSELockOnOff : 7|2@0+ (1,0) [0|0] ""  CGW,DATC,IPM,RRC
 SG_ DATC_AqsMode : 9|2@0+ (1,0) [0|0] ""  CGW,CLU,DATC,IPM
 SG_ HU_Graphreset_Info : 17|2@0+ (1,0) [0|0] ""  CGW,CLU,DATC,IPM
 SG_ HU_VRActivity : 33|2@0+ (1,0) [0|0] ""  CGW,CLU,DATC,IPM
 SG_ HU_PhoneActivity : 35|2@0+ (1,0) [0|0] ""  CGW,CLU,DATC,IPM
 SG_ BlowerNoiseControl : 37|2@0+ (1,0) [0|0] ""  CGW,CLU,DATC,IPM

BO_ 1211 TP_HU_TBT_CLU: 8 H_U
 SG_ Byte0_TCP_4BB : 7|8@0+ (1,0) [0|0] ""  CLU
 SG_ Byte1_Data_4BB : 15|8@0+ (1,0) [0|0] ""  CLU
 SG_ Byte2_Data_4BB : 23|8@0+ (1,0) [0|0] ""  CLU
 SG_ Byte3_Data_4BB : 31|8@0+ (1,0) [0|0] ""  CLU
 SG_ Byte4_Data_4BB : 39|8@0+ (1,0) [0|0] ""  CLU
 SG_ Byte5_Data_4BB : 47|8@0+ (1,0) [0|0] ""  CLU
 SG_ Byte6_Data_4BB : 55|8@0+ (1,0) [0|0] ""  CLU
 SG_ Byte7_Data_4BB : 63|8@0+ (1,0) [0|0] ""  CLU

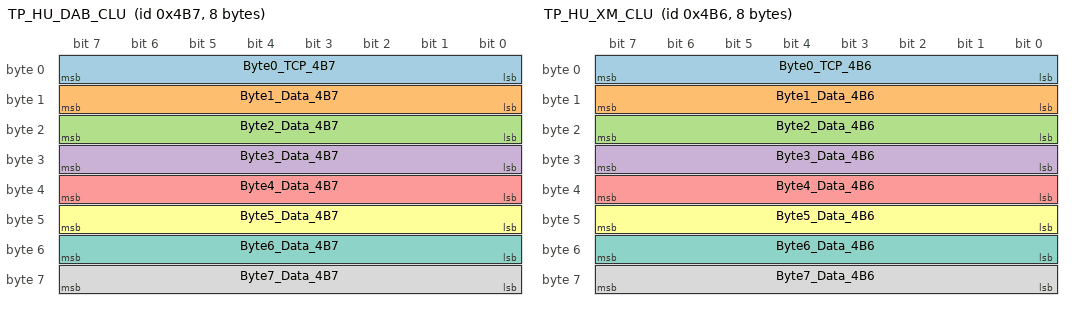
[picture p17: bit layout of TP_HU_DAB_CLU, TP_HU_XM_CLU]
BO_ 1207 TP_HU_DAB_CLU: 8 H_U
 SG_ Byte0_TCP_4B7 : 7|8@0+ (1,0) [0|0] ""  CLU
 SG_ Byte1_Data_4B7 : 15|8@0+ (1,0) [0|0] ""  CLU
 SG_ Byte2_Data_4B7 : 23|8@0+ (1,0) [0|0] ""  CLU
 SG_ Byte3_Data_4B7 : 31|8@0+ (1,0) [0|0] ""  CLU
 SG_ Byte4_Data_4B7 : 39|8@0+ (1,0) [0|0] ""  CLU
 SG_ Byte5_Data_4B7 : 47|8@0+ (1,0) [0|0] ""  CLU
 SG_ Byte6_Data_4B7 : 55|8@0+ (1,0) [0|0] ""  CLU
 SG_ Byte7_Data_4B7 : 63|8@0+ (1,0) [0|0] ""  CLU

BO_ 1206 TP_HU_XM_CLU: 8 H_U
 SG_ Byte0_TCP_4B6 : 7|8@0+ (1,0) [0|0] ""  CLU
 SG_ Byte1_Data_4B6 : 15|8@0+ (1,0) [0|0] ""  CLU
 SG_ Byte2_Data_4B6 : 23|8@0+ (1,0) [0|0] ""  CLU
 SG_ Byte3_Data_4B6 : 31|8@0+ (1,0) [0|0] ""  CLU
 SG_ Byte4_Data_4B6 : 39|8@0+ (1,0) [0|0] ""  CLU
 SG_ Byte5_Data_4B6 : 47|8@0+ (1,0) [0|0] ""  CLU
 SG_ Byte6_Data_4B6 : 55|8@0+ (1,0) [0|0] ""  CLU
 SG_ Byte7_Data_4B6 : 63|8@0+ (1,0) [0|0] ""  CLU

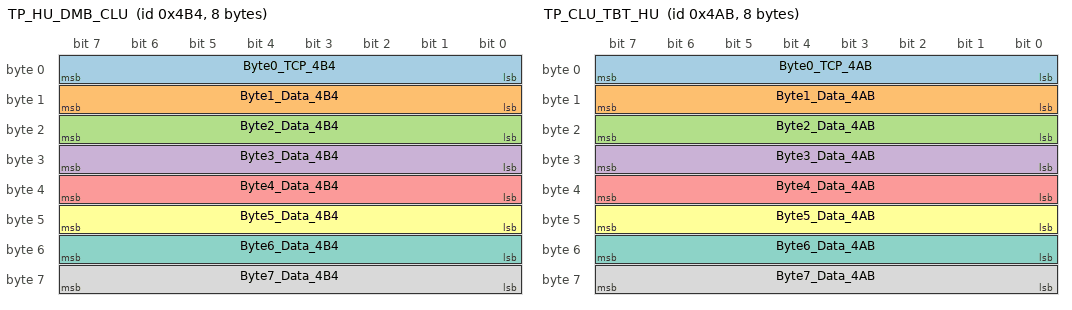
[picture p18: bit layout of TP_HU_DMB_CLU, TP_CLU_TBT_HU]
BO_ 1204 TP_HU_DMB_CLU: 8 H_U
 SG_ Byte0_TCP_4B4 : 7|8@0+ (1,0) [0|0] ""  CLU
 SG_ Byte1_Data_4B4 : 15|8@0+ (1,0) [0|0] ""  CLU
 SG_ Byte2_Data_4B4 : 23|8@0+ (1,0) [0|0] ""  CLU
 SG_ Byte3_Data_4B4 : 31|8@0+ (1,0) [0|0] ""  CLU
 SG_ Byte4_Data_4B4 : 39|8@0+ (1,0) [0|0] ""  CLU
 SG_ Byte5_Data_4B4 : 47|8@0+ (1,0) [0|0] ""  CLU
 SG_ Byte6_Data_4B4 : 55|8@0+ (1,0) [0|0] ""  CLU
 SG_ Byte7_Data_4B4 : 63|8@0+ (1,0) [0|0] ""  CLU

BO_ 432 TMU_GW_PE_01: 8 TMU
 SG_ C_DATCOnOffReq : 1|2@0+ (1,0) [0|0] ""  CGW,CLU,DATC,H_U,IPM
 SG_ C_DATCTempUnit : 3|2@0+ (1,0) [0|0] ""  CGW,CLU,DATC,H_U,IPM
 SG_ C_DATCTempSet : 15|8@0+ (1,0) [0|0] ""  CGW,CLU,DATC,H_U,IPM
 SG_ TMU_IVRActivity : 33|2@0+ (1,0) [0|0] ""  CGW,CLU,DATC,H_U,IPM
 SG_ TMU_PhoneActivity : 35|2@0+ (1,0) [0|0] ""  CGW,CLU,DATC,H_U,IPM

BO_ 1195 TP_CLU_TBT_HU: 8 CLU
 SG_ Byte0_TCP_4AB : 7|8@0+ (1,0) [0|0] ""  H_U
 SG_ Byte1_Data_4AB : 15|8@0+ (1,0) [0|0] ""  H_U
 SG_ Byte2_Data_4AB : 23|8@0+ (1,0) [0|0] ""  H_U
 SG_ Byte3_Data_4AB : 31|8@0+ (1,0) [0|0] ""  H_U
 SG_ Byte4_Data_4AB : 39|8@0+ (1,0) [0|0] ""  H_U
 SG_ Byte5_Data_4AB : 47|8@0+ (1,0) [0|0] ""  H_U
 SG_ Byte6_Data_4AB : 55|8@0+ (1,0) [0|0] ""  H_U
 SG_ Byte7_Data_4AB : 63|8@0+ (1,0) [0|0] ""  H_U

BO_ 1191 TP_CLU_DAB_HU: 8 CLU
 SG_ Byte0_TCP_4A7 : 7|8@0+ (1,0) [0|0] ""  H_U
 SG_ Byte1_Data_4A7 : 15|8@0+ (1,0) [0|0] ""  H_U
 SG_ Byte2_Data_4A7 : 23|8@0+ (1,0) [0|0] ""  H_U
 SG_ Byte3_Data_4A7 : 31|8@0+ (1,0) [0|0] ""  H_U
 SG_ Byte4_Data_4A7 : 39|8@0+ (1,0) [0|0] ""  H_U
 SG_ Byte5_Data_4A7 : 47|8@0+ (1,0) [0|0] ""  H_U
 SG_ Byte6_Data_4A7 : 55|8@0+ (1,0) [0|0] ""  H_U
 SG_ Byte7_Data_4A7 : 63|8@0+ (1,0) [0|0] ""  H_U

BO_ 1190 TP_CLU_XM_HU: 8 CLU
 SG_ Byte0_TCP_4A6 : 7|8@0+ (1,0) [0|0] ""  H_U
 SG_ Byte1_Data_4A6 : 15|8@0+ (1,0) [0|0] ""  H_U
 SG_ Byte2_Data_4A6 : 23|8@0+ (1,0) [0|0] ""  H_U
 SG_ Byte3_Data_4A6 : 31|8@0+ (1,0) [0|0] ""  H_U
 SG_ Byte4_Data_4A6 : 39|8@0+ (1,0) [0|0] ""  H_U
 SG_ Byte5_Data_4A6 : 47|8@0+ (1,0) [0|0] ""  H_U
 SG_ Byte6_Data_4A6 : 55|8@0+ (1,0) [0|0] ""  H_U
 SG_ Byte7_Data_4A6 : 63|8@0+ (1,0) [0|0] ""  H_U

BO_ 1188 TP_CLU_DMB_HU: 8 CLU
 SG_ Byte0_TCP_4A4 : 7|8@0+ (1,0) [0|0] ""  H_U
 SG_ Byte1_Data_4A4 : 15|8@0+ (1,0) [0|0] ""  H_U
 SG_ Byte2_Data_4A4 : 23|8@0+ (1,0) [0|0] ""  H_U
 SG_ Byte3_Data_4A4 : 31|8@0+ (1,0) [0|0] ""  H_U
 SG_ Byte4_Data_4A4 : 39|8@0+ (1,0) [0|0] ""  H_U
 SG_ Byte5_Data_4A4 : 47|8@0+ (1,0) [0|0] ""  H_U
 SG_ Byte6_Data_4A4 : 55|8@0+ (1,0) [0|0] ""  H_U
 SG_ Byte7_Data_4A4 : 63|8@0+ (1,0) [0|0] ""  H_U

BO_ 1179 TP_HU_NAVI_CLU: 8 H_U
 SG_ Byte0_TCP_49B : 7|8@0+ (1,0) [0|0] ""  CLU
 SG_ Byte1_Data_49B : 15|8@0+ (1,0) [0|0] ""  CLU
 SG_ Byte2_Data_49B : 23|8@0+ (1,0) [0|0] ""  CLU
 SG_ Byte3_Data_49B : 31|8@0+ (1,0) [0|0] ""  CLU
 SG_ Byte4_Data_49B : 39|8@0+ (1,0) [0|0] ""  CLU
 SG_ Byte5_Data_49B : 47|8@0+ (1,0) [0|0] ""  CLU
 SG_ Byte6_Data_49B : 55|8@0+ (1,0) [0|0] ""  CLU
 SG_ Byte7_Data_49B : 63|8@0+ (1,0) [0|0] ""  CLU

BO_ 1178 TP_CLU_Ipod_HU: 8 CLU
 SG_ Byte0_TCP_49A : 7|8@0+ (1,0) [0|0] ""  H_U
 SG_ Byte1_Data_49A : 15|8@0+ (1,0) [0|0] ""  H_U
 SG_ Byte2_Data_49A : 23|8@0+ (1,0) [0|0] ""  H_U
 SG_ Byte3_Data_49A : 31|8@0+ (1,0) [0|0] ""  H_U
 SG_ Byte4_Data_49A : 39|8@0+ (1,0) [0|0] ""  H_U
 SG_ Byte5_Data_49A : 47|8@0+ (1,0) [0|0] ""  H_U
 SG_ Byte6_Data_49A : 55|8@0+ (1,0) [0|0] ""  H_U
 SG_ Byte7_Data_49A : 63|8@0+ (1,0) [0|0] ""  H_U

BO_ 410 HU_CLU_PE_08: 8 H_U
 SG_ VCDC_SelDiscNo : 11|4@0+ (1,0) [0|0] ""  CLU
 SG_ VCDC_TrackChapterNo : 7|10@0+ (1,0) [0|0] ""  CLU
 SG_ VCDC_PlayTime : 23|24@0+ (1,0) [0|0] ""  CLU
 SG_ MLT_PlayTime : 47|24@0+ (1,0) [0|0] ""  CLU

BO_ 1176 TP_CLU_DVD_HU: 8 CLU
 SG_ Byte0_TCP_498 : 7|8@0+ (1,0) [0|0] ""  H_U
 SG_ Byte1_Data_498 : 15|8@0+ (1,0) [0|0] ""  H_U
 SG_ Byte2_Data_498 : 23|8@0+ (1,0) [0|0] ""  H_U
 SG_ Byte3_Data_498 : 31|8@0+ (1,0) [0|0] ""  H_U
 SG_ Byte4_Data_498 : 39|8@0+ (1,0) [0|0] ""  H_U
 SG_ Byte5_Data_498 : 47|8@0+ (1,0) [0|0] ""  H_U
 SG_ Byte6_Data_498 : 55|8@0+ (1,0) [0|0] ""  H_U
 SG_ Byte7_Data_498 : 63|8@0+ (1,0) [0|0] ""  H_U

BO_ 1175 TP_CLU_USB_HU: 8 CLU
 SG_ Byte0_TCP_497 : 7|8@0+ (1,0) [0|0] ""  H_U
 SG_ Byte1_Data_497 : 15|8@0+ (1,0) [0|0] ""  H_U
 SG_ Byte2_Data_497 : 23|8@0+ (1,0) [0|0] ""  H_U
 SG_ Byte3_Data_497 : 31|8@0+ (1,0) [0|0] ""  H_U
 SG_ Byte4_Data_497 : 39|8@0+ (1,0) [0|0] ""  H_U
 SG_ Byte5_Data_497 : 47|8@0+ (1,0) [0|0] ""  H_U
 SG_ Byte6_Data_497 : 55|8@0+ (1,0) [0|0] ""  H_U
 SG_ Byte7_Data_497 : 63|8@0+ (1,0) [0|0] ""  H_U

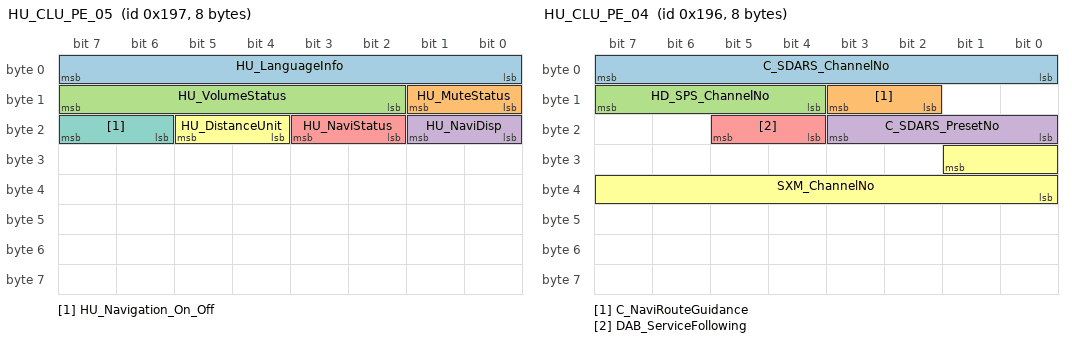
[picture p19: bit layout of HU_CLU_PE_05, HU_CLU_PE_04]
BO_ 407 HU_CLU_PE_05: 8 H_U
 SG_ HU_LanguageInfo : 7|8@0+ (1,0) [0|0] ""  CLU,HUD
 SG_ HU_MuteStatus : 9|2@0+ (1,0) [0|0] ""  CLU,HUD
 SG_ HU_VolumeStatus : 15|6@0+ (1,0) [0|0] ""  CLU,HUD
 SG_ HU_NaviDisp : 17|2@0+ (1,0) [0|0] ""  CLU,HUD
 SG_ HU_NaviStatus : 19|2@0+ (1,0) [0|0] ""  CGW,CLU,HUD,IPM
 SG_ HU_DistanceUnit : 21|2@0+ (1,0) [0|0] ""  CLU,HUD
 SG_ HU_Navigation_On_Off : 23|2@0+ (1,0) [0|0] ""  AVM,CGW,CLU,DATC,HUD,IPM

BO_ 1942 TP_AMP_HU_DiagRes: 8 AMP
 SG_ Byte0_TCP_796 : 7|8@0+ (1,0) [0|0] ""  H_U
 SG_ Byte1_Data_796 : 15|8@0+ (1,0) [0|0] ""  H_U
 SG_ Byte2_Data_796 : 23|8@0+ (1,0) [0|0] ""  H_U
 SG_ Byte3_Data_796 : 31|8@0+ (1,0) [0|0] ""  H_U
 SG_ Byte4_Data_796 : 39|8@0+ (1,0) [0|0] ""  H_U
 SG_ Byte5_Data_796 : 47|8@0+ (1,0) [0|0] ""  H_U
 SG_ Byte6_Data_796 : 55|8@0+ (1,0) [0|0] ""  H_U
 SG_ Byte7_Data_796 : 63|8@0+ (1,0) [0|0] ""  H_U

BO_ 406 HU_CLU_PE_04: 8 H_U
 SG_ C_SDARS_ChannelNo : 7|8@0+ (1,0) [0|0] ""  CLU
 SG_ C_NaviRouteGuidance : 11|2@0+ (1,0) [0|0] ""  CLU
 SG_ HD_SPS_ChannelNo : 15|4@0+ (1,0) [0|0] ""  CLU
 SG_ C_SDARS_PresetNo : 19|4@0+ (1,0) [0|0] ""  CLU
 SG_ DAB_ServiceFollowing : 21|2@0+ (1,0) [0|0] ""  CLU
 SG_ SXM_ChannelNo : 25|10@0+ (1,0) [0|999] ""  AMP,CLU,HUD

BO_ 1941 TP_HU_AMP_DiagReq: 8 H_U
 SG_ Byte0_TCP_795 : 7|8@0+ (1,0) [0|0] ""  AMP
 SG_ Byte1_Data_795 : 15|8@0+ (1,0) [0|0] ""  AMP
 SG_ Byte2_Data_795 : 23|8@0+ (1,0) [0|0] ""  AMP
 SG_ Byte3_Data_795 : 31|8@0+ (1,0) [0|0] ""  AMP
 SG_ Byte4_Data_795 : 39|8@0+ (1,0) [0|0] ""  AMP
 SG_ Byte5_Data_795 : 47|8@0+ (1,0) [0|0] ""  AMP
 SG_ Byte6_Data_795 : 55|8@0+ (1,0) [0|0] ""  AMP
 SG_ Byte7_Data_795 : 63|8@0+ (1,0) [0|0] ""  AMP

BO_ 1173 TP_CLU_CD_HU: 8 CLU
 SG_ Byte0_TCP_495 : 7|8@0+ (1,0) [0|0] ""  H_U
 SG_ Byte1_Data_495 : 15|8@0+ (1,0) [0|0] ""  H_U
 SG_ Byte2_Data_495 : 23|8@0+ (1,0) [0|0] ""  H_U
 SG_ Byte3_Data_495 : 31|8@0+ (1,0) [0|0] ""  H_U
 SG_ Byte4_Data_495 : 39|8@0+ (1,0) [0|0] ""  H_U
 SG_ Byte5_Data_495 : 47|8@0+ (1,0) [0|0] ""  H_U
 SG_ Byte6_Data_495 : 55|8@0+ (1,0) [0|0] ""  H_U
 SG_ Byte7_Data_495 : 63|8@0+ (1,0) [0|0] ""  H_U

BO_ 405 HU_CLU_PE_03: 8 H_U
 SG_ HU_IntegPresetNum : 7|8@0+ (1,0) [0|0] ""  AMP,CLU,HUD
 SG_ Radio_Area : 10|8@0+ (1,0) [0|0] ""  CLU
 SG_ DMB_PresetNo : 29|5@0+ (1,0) [0|0] ""  CLU
 SG_ RADIO_PresetNo : 18|5@0+ (1,0) [0|0] ""  CLU
 SG_ HU_Opstate_DIS2 : 38|7@0+ (1,0) [0|0] ""  AMP,CLU,HUD

BO_ 1168 TP_HU_USB_CLU: 8 H_U
 SG_ Byte0_TCP_490 : 7|8@0+ (1,0) [0|0] ""  CLU
 SG_ Byte1_Data_490 : 15|8@0+ (1,0) [0|0] ""  CLU
 SG_ Byte2_Data_490 : 23|8@0+ (1,0) [0|0] ""  CLU
 SG_ Byte3_Data_490 : 31|8@0+ (1,0) [0|0] ""  CLU
 SG_ Byte4_Data_490 : 39|8@0+ (1,0) [0|0] ""  CLU
 SG_ Byte5_Data_490 : 47|8@0+ (1,0) [0|0] ""  CLU
 SG_ Byte6_Data_490 : 55|8@0+ (1,0) [0|0] ""  CLU
 SG_ Byte7_Data_490 : 63|8@0+ (1,0) [0|0] ""  CLU

BO_ 1936 TP_HU_All_Req: 8 H_U
 SG_ Byte0_TCP_790 : 7|8@0+ (1,0) [0|0] ""  AMP,ASD,AVM,CCP,CGW,CLOCK,CLU,CUBIS,DATC,EDT,FHCU,HUD,IBOX,IPM,KBD,KMA_TMU,MON,RRC,RSE_L,RSE_R,SWRC,TMU
 SG_ Byte1_Data_790 : 15|8@0+ (1,0) [0|0] ""  AMP,ASD,AVM,CCP,CGW,CLOCK,CLU,CUBIS,DATC,EDT,FHCU,HUD,IBOX,IPM,KBD,KMA_TMU,MON,RRC,RSE_L,RSE_R,SWRC,TMU
 SG_ Byte2_Data_790 : 23|8@0+ (1,0) [0|0] ""  AMP,ASD,AVM,CCP,CGW,CLOCK,CLU,CUBIS,DATC,EDT,FHCU,HUD,IBOX,IPM,KBD,KMA_TMU,MON,RRC,RSE_L,RSE_R,SWRC,TMU
 SG_ Byte3_Data_790 : 31|8@0+ (1,0) [0|0] ""  AMP,ASD,AVM,CCP,CGW,CLOCK,CLU,CUBIS,DATC,EDT,FHCU,HUD,IBOX,IPM,KBD,KMA_TMU,MON,RRC,RSE_L,RSE_R,SWRC,TMU
 SG_ Byte4_Data_790 : 39|8@0+ (1,0) [0|0] ""  AMP,ASD,AVM,CCP,CGW,CLOCK,CLU,CUBIS,DATC,EDT,FHCU,HUD,IBOX,IPM,KBD,KMA_TMU,MON,RRC,RSE_L,RSE_R,SWRC,TMU
 SG_ Byte5_Data_790 : 47|8@0+ (1,0) [0|0] ""  AMP,ASD,AVM,CCP,CGW,CLOCK,CLU,CUBIS,DATC,EDT,FHCU,HUD,IBOX,IPM,KBD,KMA_TMU,MON,RRC,RSE_L,RSE_R,SWRC,TMU
 SG_ Byte6_Data_790 : 55|8@0+ (1,0) [0|0] ""  AMP,ASD,AVM,CCP,CGW,CLOCK,CLU,CUBIS,DATC,EDT,FHCU,HUD,IBOX,IPM,KBD,KMA_TMU,MON,RRC,RSE_L,RSE_R,SWRC,TMU
 SG_ Byte7_Data_790 : 63|8@0+ (1,0) [0|0] ""  AMP,ASD,AVM,CCP,CGW,CLOCK,CLU,CUBIS,DATC,EDT,FHCU,HUD,IBOX,IPM,KBD,KMA_TMU,MON,RRC,RSE_L,RSE_R,SWRC,TMU

BO_ 1167 TP_HU_Ipod_CLU: 8 H_U
 SG_ Byte0_TCP_48F : 7|8@0+ (1,0) [0|0] ""  CLU
 SG_ Byte1_Data_48F : 15|8@0+ (1,0) [0|0] ""  CLU
 SG_ Byte2_Data_48F : 23|8@0+ (1,0) [0|0] ""  CLU
 SG_ Byte3_Data_48F : 31|8@0+ (1,0) [0|0] ""  CLU
 SG_ Byte4_Data_48F : 39|8@0+ (1,0) [0|0] ""  CLU
 SG_ Byte5_Data_48F : 47|8@0+ (1,0) [0|0] ""  CLU
 SG_ Byte6_Data_48F : 55|8@0+ (1,0) [0|0] ""  CLU
 SG_ Byte7_Data_48F : 63|8@0+ (1,0) [0|0] ""  CLU

BO_ 1166 TP_HU_DVD_CLU: 8 H_U
 SG_ Byte0_TCP_48E : 7|8@0+ (1,0) [0|0] ""  CLU
 SG_ Byte1_Data_48E : 15|8@0+ (1,0) [0|0] ""  CLU
 SG_ Byte2_Data_48E : 23|8@0+ (1,0) [0|0] ""  CLU
 SG_ Byte3_Data_48E : 31|8@0+ (1,0) [0|0] ""  CLU
 SG_ Byte4_Data_48E : 39|8@0+ (1,0) [0|0] ""  CLU
 SG_ Byte5_Data_48E : 47|8@0+ (1,0) [0|0] ""  CLU
 SG_ Byte6_Data_48E : 55|8@0+ (1,0) [0|0] ""  CLU
 SG_ Byte7_Data_48E : 63|8@0+ (1,0) [0|0] ""  CLU

BO_ 1165 TP_HU_CD_CLU: 8 H_U
 SG_ Byte0_TCP_48D : 7|8@0+ (1,0) [0|0] ""  CLU
 SG_ Byte1_Data_48D : 15|8@0+ (1,0) [0|0] ""  CLU
 SG_ Byte2_Data_48D : 23|8@0+ (1,0) [0|0] ""  CLU
 SG_ Byte3_Data_48D : 31|8@0+ (1,0) [0|0] ""  CLU
 SG_ Byte4_Data_48D : 39|8@0+ (1,0) [0|0] ""  CLU
 SG_ Byte5_Data_48D : 47|8@0+ (1,0) [0|0] ""  CLU
 SG_ Byte6_Data_48D : 55|8@0+ (1,0) [0|0] ""  CLU
 SG_ Byte7_Data_48D : 63|8@0+ (1,0) [0|0] ""  CLU

BO_ 1164 TP_CLU_NAVI_HU: 8 CLU
 SG_ Byte0_TCP_48C : 7|8@0+ (1,0) [0|0] ""  H_U
 SG_ Byte1_Data_48C : 15|8@0+ (1,0) [0|0] ""  H_U
 SG_ Byte2_Data_48C : 23|8@0+ (1,0) [0|0] ""  H_U
 SG_ Byte3_Data_48C : 31|8@0+ (1,0) [0|0] ""  H_U
 SG_ Byte4_Data_48C : 39|8@0+ (1,0) [0|0] ""  H_U
 SG_ Byte5_Data_48C : 47|8@0+ (1,0) [0|0] ""  H_U
 SG_ Byte6_Data_48C : 55|8@0+ (1,0) [0|0] ""  H_U
 SG_ Byte7_Data_48C : 63|8@0+ (1,0) [0|0] ""  H_U

CM_ BO_ 3221225472 "This is a message for not used signals, created by Vector CANdb++ DBC OLE DB Provider.";
CM_ SG_ 3221225472 C_WHEEL_FL "Wheel rpm front left";
CM_ SG_ 3221225472 C_WHEEL_FR "Wheel rpm front right";
CM_ SG_ 3221225472 C_WHEEL_RL "Wheel rpm rear left";
CM_ SG_ 3221225472 C_WHEEL_RR "Wheel rpm rear right";
CM_ BO_ 2046 "[TP] TP Message";
CM_ SG_ 2046 Byte0_TCP_7FE "TP";
CM_ SG_ 2046 Byte1_Data_7FE "TP";
CM_ SG_ 2046 Byte2_Data_7FE "TP";
CM_ SG_ 2046 Byte3_Data_7FE "TP";
CM_ SG_ 2046 Byte4_Data_7FE "TP";
CM_ SG_ 2046 Byte5_Data_7FE "TP";
CM_ SG_ 2046 Byte6_Data_7FE "TP";
CM_ SG_ 2046 Byte7_Data_7FE "TP";
CM_ BO_ 251 "[EC] On Event and On Change";
CM_ SG_ 251 HU_GPS_Year "These signal shall be sent to TMU as soon as GPS Time is available";
CM_ BO_ 250 "[EC] On Event and On Change";
CM_ SG_ 250 HU_VoiceRecCom "Voice Recognition Command";
CM_ SG_ 250 HU_LangChgCom "Language Change Command";
CM_ SG_ 250 HU_CallEndCmd "Call End Command";
CM_ SG_ 250 HU_ServiceReqtID "Service Request ID";
CM_ SG_ 250 HU_MicReqCmd "Mic Request Command";
CM_ SG_ 250 HU_SeviceAction "Service Action";
CM_ SG_ 250 HU_eCallStatus "Response of TMU_eCall signal";
CM_ BO_ 1269 "[TP] TP Message";
CM_ BO_ 1268 "[TP] TP Message";
CM_ BO_ 1267 "[TP] TP Message";
CM_ BO_ 1266 "[TP] TP Message";
CM_ BO_ 1263 "[TP] TP Message";
CM_ SG_ 1263 Byte0_TCP_4EF "Flow Control message for TP_HU_IBOX_CLU";
CM_ SG_ 1263 Byte1_Data_4EF "Flow Control message for TP_HU_IBOX_CLU";
CM_ SG_ 1263 Byte2_Data_4EF "Flow Control message for TP_HU_IBOX_CLU";
CM_ SG_ 1263 Byte3_Data_4EF "Flow Control message for TP_HU_IBOX_CLU";
CM_ SG_ 1263 Byte4_Data_4EF "Flow Control message for TP_HU_IBOX_CLU";
CM_ SG_ 1263 Byte5_Data_4EF "Flow Control message for TP_HU_IBOX_CLU";
CM_ SG_ 1263 Byte6_Data_4EF "Flow Control message for TP_HU_IBOX_CLU";
CM_ SG_ 1263 Byte7_Data_4EF "Flow Control message for TP_HU_IBOX_CLU";
CM_ BO_ 1262 "[TP] TP Message";
CM_ SG_ 1262 Byte0_TCP_4EE "Song Name, Artist, File Name, Play Time of iBox player";
CM_ SG_ 1262 Byte1_Data_4EE "Song Name, Artist, File Name, Play Time of iBox player";
CM_ SG_ 1262 Byte2_Data_4EE "Song Name, Artist, File Name, Play Time of iBox player";
CM_ SG_ 1262 Byte3_Data_4EE "Song Name, Artist, File Name, Play Time of iBox player";
CM_ SG_ 1262 Byte4_Data_4EE "Song Name, Artist, File Name, Play Time of iBox player";
CM_ SG_ 1262 Byte5_Data_4EE "Song Name, Artist, File Name, Play Time of iBox player";
CM_ SG_ 1262 Byte6_Data_4EE "Song Name, Artist, File Name, Play Time of iBox player";
CM_ SG_ 1262 Byte7_Data_4EE "Song Name, Artist, File Name, Play Time of iBox player";
CM_ BO_ 1261 "[TP] TP Message";
CM_ SG_ 1261 Byte0_TCP_4ED "Flow Control message for TP_HU_DLNA_CLU";
CM_ SG_ 1261 Byte1_Data_4ED "Flow Control message for TP_HU_DLNA_CLU";
CM_ SG_ 1261 Byte2_Data_4ED "Flow Control message for TP_HU_DLNA_CLU";
CM_ SG_ 1261 Byte3_Data_4ED "Flow Control message for TP_HU_DLNA_CLU";
CM_ SG_ 1261 Byte4_Data_4ED "Flow Control message for TP_HU_DLNA_CLU";
CM_ SG_ 1261 Byte5_Data_4ED "Flow Control message for TP_HU_DLNA_CLU";
CM_ SG_ 1261 Byte6_Data_4ED "Flow Control message for TP_HU_DLNA_CLU";
CM_ SG_ 1261 Byte7_Data_4ED "Flow Control message for TP_HU_DLNA_CLU";
CM_ BO_ 1260 "[TP] TP Message";
CM_ SG_ 1260 Byte0_TCP_4EC "Song Name, Artist, File Name, Play Time of DLNA";
CM_ SG_ 1260 Byte1_Data_4EC "Song Name, Artist, File Name, Play Time of DLNA";
CM_ SG_ 1260 Byte2_Data_4EC "Song Name, Artist, File Name, Play Time of DLNA";
CM_ SG_ 1260 Byte3_Data_4EC "Song Name, Artist, File Name, Play Time of DLNA";
CM_ SG_ 1260 Byte4_Data_4EC "Song Name, Artist, File Name, Play Time of DLNA";
CM_ SG_ 1260 Byte5_Data_4EC "Song Name, Artist, File Name, Play Time of DLNA";
CM_ SG_ 1260 Byte6_Data_4EC "Song Name, Artist, File Name, Play Time of DLNA";
CM_ SG_ 1260 Byte7_Data_4EC "Song Name, Artist, File Name, Play Time of DLNA";
CM_ BO_ 491 "[PE] Periodic and On Event";
CM_ SG_ 491 C_DRVDoorStatus "Driver Door Switch";
CM_ SG_ 491 C_ASTDoorStatus "Assist Door Switch";
CM_ SG_ 491 C_RLDoorStatus "Rear Left Door Switch";
CM_ SG_ 491 C_RRDoorStatus "Rear Right Door Switch";
CM_ SG_ 491 C_TrunkStatus "Trunk or tail gate closing status";
CM_ SG_ 491 C_OSMirrorStatus "Assist Outside Mirror fold Unfold state";
CM_ BO_ 1259 "[TP] TP Message";
CM_ SG_ 1259 Byte0_TCP_4EB "Flow Control message for TP_HU_MP_CLU";
CM_ SG_ 1259 Byte1_Data_4EB "Flow Control message for TP_HU_MP_CLU";
CM_ SG_ 1259 Byte2_Data_4EB "Flow Control message for TP_HU_MP_CLU";
CM_ SG_ 1259 Byte3_Data_4EB "Flow Control message for TP_HU_MP_CLU";
CM_ SG_ 1259 Byte4_Data_4EB "Flow Control message for TP_HU_MP_CLU";
CM_ SG_ 1259 Byte5_Data_4EB "Flow Control message for TP_HU_MP_CLU";
CM_ SG_ 1259 Byte6_Data_4EB "Flow Control message for TP_HU_MP_CLU";
CM_ SG_ 1259 Byte7_Data_4EB "Flow Control message for TP_HU_MP_CLU";
CM_ BO_ 1258 "[TP] TP Message";
CM_ SG_ 1258 Byte0_TCP_4EA "Mozen phone number";
CM_ SG_ 1258 Byte1_Data_4EA "Mozen phone number";
CM_ SG_ 1258 Byte2_Data_4EA "Mozen phone number";
CM_ SG_ 1258 Byte3_Data_4EA "Mozen phone number";
CM_ SG_ 1258 Byte4_Data_4EA "Mozen phone number";
CM_ SG_ 1258 Byte5_Data_4EA "Mozen phone number";
CM_ SG_ 1258 Byte6_Data_4EA "Mozen phone number";
CM_ SG_ 1258 Byte7_Data_4EA "Mozen phone number";
CM_ BO_ 1257 "[TP] TP Message";
CM_ SG_ 1257 Byte0_TCP_4E9 "TP from CLU to HU (FM Station Name)";
CM_ SG_ 1257 Byte1_Data_4E9 "TP from CLU to HU (FM Station Name)";
CM_ SG_ 1257 Byte2_Data_4E9 "TP from CLU to HU (FM Station Name)";
CM_ SG_ 1257 Byte3_Data_4E9 "TP from CLU to HU (FM Station Name)";
CM_ SG_ 1257 Byte4_Data_4E9 "TP from CLU to HU (FM Station Name)";
CM_ SG_ 1257 Byte5_Data_4E9 "TP from CLU to HU (FM Station Name)";
CM_ SG_ 1257 Byte6_Data_4E9 "TP from CLU to HU (FM Station Name)";
CM_ SG_ 1257 Byte7_Data_4E9 "TP from CLU to HU (FM Station Name)";
CM_ BO_ 1256 "[TP] TP Message";
CM_ SG_ 1256 Byte0_TCP_4E8 "TP from HU to CLU (FM Station Name)";
CM_ SG_ 1256 Byte1_Data_4E8 "TP from HU to CLU (FM Station Name)";
CM_ SG_ 1256 Byte2_Data_4E8 "TP from HU to CLU (FM Station Name)";
CM_ SG_ 1256 Byte3_Data_4E8 "TP from HU to CLU (FM Station Name)";
CM_ SG_ 1256 Byte4_Data_4E8 "TP from HU to CLU (FM Station Name)";
CM_ SG_ 1256 Byte5_Data_4E8 "TP from HU to CLU (FM Station Name)";
CM_ SG_ 1256 Byte6_Data_4E8 "TP from HU to CLU (FM Station Name)";
CM_ SG_ 1256 Byte7_Data_4E8 "TP from HU to CLU (FM Station Name)";
CM_ BO_ 1255 "[TP] TP Message";
CM_ SG_ 1255 Byte0_TCP_4E7 "TP from CLU to HU (More Like this)";
CM_ SG_ 1255 Byte1_Data_4E7 "TP from CLU to HU (More Like this)";
CM_ SG_ 1255 Byte2_Data_4E7 "TP from CLU to HU (More Like this)";
CM_ SG_ 1255 Byte3_Data_4E7 "TP from CLU to HU (More Like this)";
CM_ SG_ 1255 Byte4_Data_4E7 "TP from CLU to HU (More Like this)";
CM_ SG_ 1255 Byte5_Data_4E7 "TP from CLU to HU (More Like this)";
CM_ SG_ 1255 Byte6_Data_4E7 "TP from CLU to HU (More Like this)";
CM_ SG_ 1255 Byte7_Data_4E7 "TP from CLU to HU (More Like this)";
CM_ BO_ 487 "[PE] Periodic and On Event";
CM_ SG_ 487 Navi_DistToPoint1_F "Distance to next point 1 (Under zero point)";
CM_ SG_ 487 Navi_DistToPoint1_I "Distance to next point 1 (Over zero point)";
CM_ SG_ 487 Navi_DistToPoint1_U "Unit of Distance to next point 1";
CM_ SG_ 487 Navi_DistToPoint2_I "Distance to next point 1 (Over zero point)";
CM_ SG_ 487 Navi_DistToPoint2_F "Distance to next point 1 (Under zero point)";
CM_ SG_ 487 Navi_DistToPoint2_U "Unit of Distance to next point 1";
CM_ SG_ 487 Navi_DistToPoint3_F "Distance to next point 2 (Under zero point)";
CM_ SG_ 487 Navi_DistToPoint3_I "Distance to next point 2 (Over zero point)";
CM_ SG_ 487 Navi_DistToPoint3_U "Unit of Distance to next point 2";
CM_ BO_ 1254 "[TP] TP Message";
CM_ SG_ 1254 Byte0_TCP_4E6 "TP from HU to CLU (More Like this)";
CM_ SG_ 1254 Byte1_Data_4E6 "TP from HU to CLU (More Like this)";
CM_ SG_ 1254 Byte2_Data_4E6 "TP from HU to CLU (More Like this)";
CM_ SG_ 1254 Byte3_Data_4E6 "TP from HU to CLU (More Like this)";
CM_ SG_ 1254 Byte4_Data_4E6 "TP from HU to CLU (More Like this)";
CM_ SG_ 1254 Byte5_Data_4E6 "TP from HU to CLU (More Like this)";
CM_ SG_ 1254 Byte6_Data_4E6 "TP from HU to CLU (More Like this)";
CM_ SG_ 1254 Byte7_Data_4E6 "TP from HU to CLU (More Like this)";
CM_ BO_ 486 "[PE] Periodic and On Event";
CM_ SG_ 486 Navi_DistToDest_I "Distance to destination (Over zero point)";
CM_ SG_ 486 Navi_DistToDest_F "Distance to destination (Under zero point)";
CM_ SG_ 486 Navi_DistToDest_U "Unit of Distance to destination";
CM_ BO_ 229 "[EC] On Event and On Change";
CM_ SG_ 229 SYS_SW_Ver_Req "Request the S/W versions of all CAN ECUs";
CM_ SG_ 229 SYS_CAN_Ver_Req "Request the CAN DB versions of all CAN ECUs";
CM_ SG_ 229 SYS_HW_Ver_Req "Request the H/W versions of all CAN ECUs";
CM_ SG_ 229 SYS_RBD_Req "Request the Ring Break Diagnosis";
CM_ SG_ 229 SYS_MOSTErrorDiag_Req "Request the Ring Break Diagnosis";
CM_ SG_ 229 SYS_Reset_Req "Request to reset";
CM_ BO_ 1253 "[TP] TP Message";
CM_ SG_ 1253 Byte0_TCP_4E5 "TP from CLU to HU (virtual Disc)";
CM_ SG_ 1253 Byte1_Data_4E5 "TP from CLU to HU (virtual Disc)";
CM_ SG_ 1253 Byte2_Data_4E5 "TP from CLU to HU (virtual Disc)";
CM_ SG_ 1253 Byte3_Data_4E5 "TP from CLU to HU (virtual Disc)";
CM_ SG_ 1253 Byte4_Data_4E5 "TP from CLU to HU (virtual Disc)";
CM_ SG_ 1253 Byte5_Data_4E5 "TP from CLU to HU (virtual Disc)";
CM_ SG_ 1253 Byte6_Data_4E5 "TP from CLU to HU (virtual Disc)";
CM_ SG_ 1253 Byte7_Data_4E5 "TP from CLU to HU (virtual Disc)";
CM_ BO_ 485 "[PE] Periodic and On Event";
CM_ SG_ 485 Navi_FixedSpdTrap "Inform a fixed Speed-Trap & speed limitation";
CM_ SG_ 485 Navi_MobileSpdTrap "Inform a mobile Speed-Trap & speed limitation";
CM_ SG_ 485 Navi_OverSpdAlarm "Alarm of Over speed";
CM_ SG_ 485 Navi_SpdRedlightTrap "Inform a Speed & Redlight Trap and speed limitation";
CM_ SG_ 485 Navi_NonSpdTrap "Inform Non Speed-Traps";
CM_ SG_ 485 Navi_WarningZone "Inform warning zones";
CM_ SG_ 485 Navi_MergeWarning "Warn a Merge";
CM_ SG_ 485 Navi_CurveWarning "Warn a curve";
CM_ SG_ 485 Navi_BusSpdTrap "Inform a Bus Only & Speed Trap including speed limitation";
CM_ SG_ 485 Navi_SpdLimit_Type "Type of Speed Limit Warning";
CM_ SG_ 485 Navi_SpdLimit_Unit "Unit of Speed Limit Warning";
CM_ SG_ 485 Navi_SpdInfo_Type "Type of Warning related with Speed";
CM_ SG_ 485 Navi_SpdLimit "Speed of Speed Limit Warning";
CM_ BO_ 1252 "[TP] TP Message";
CM_ SG_ 1252 Byte0_TCP_4E4 "TP from HU to CLU (virtual DIsc)";
CM_ SG_ 1252 Byte1_Data_4E4 "TP from HU to CLU (virtual DIsc)";
CM_ SG_ 1252 Byte2_Data_4E4 "TP from HU to CLU (virtual DIsc)";
CM_ SG_ 1252 Byte3_Data_4E4 "TP from HU to CLU (virtual DIsc)";
CM_ SG_ 1252 Byte4_Data_4E4 "TP from HU to CLU (virtual DIsc)";
CM_ SG_ 1252 Byte5_Data_4E4 "TP from HU to CLU (virtual DIsc)";
CM_ SG_ 1252 Byte6_Data_4E4 "TP from HU to CLU (virtual DIsc)";
CM_ SG_ 1252 Byte7_Data_4E4 "TP from HU to CLU (virtual DIsc)";
CM_ BO_ 1251 "[TP] TP Message";
CM_ SG_ 1251 Byte0_TCP_4E3 "TP from CLU to HU (Juke box)";
CM_ SG_ 1251 Byte1_Data_4E3 "TP from CLU to HU (Juke box)";
CM_ SG_ 1251 Byte2_Data_4E3 "TP from CLU to HU (Juke box)";
CM_ SG_ 1251 Byte3_Data_4E3 "TP from CLU to HU (Juke box)";
CM_ SG_ 1251 Byte4_Data_4E3 "TP from CLU to HU (Juke box)";
CM_ SG_ 1251 Byte5_Data_4E3 "TP from CLU to HU (Juke box)";
CM_ SG_ 1251 Byte6_Data_4E3 "TP from CLU to HU (Juke box)";
CM_ SG_ 1251 Byte7_Data_4E3 "TP from CLU to HU (Juke box)";
CM_ BO_ 1250 "[TP] TP Message";
CM_ SG_ 1250 Byte0_TCP_4E2 "TP from HU to CLU (Juke box)";
CM_ SG_ 1250 Byte1_Data_4E2 "TP from HU to CLU (Juke box)";
CM_ SG_ 1250 Byte2_Data_4E2 "TP from HU to CLU (Juke box)";
CM_ SG_ 1250 Byte3_Data_4E2 "TP from HU to CLU (Juke box)";
CM_ SG_ 1250 Byte4_Data_4E2 "TP from HU to CLU (Juke box)";
CM_ SG_ 1250 Byte5_Data_4E2 "TP from HU to CLU (Juke box)";
CM_ SG_ 1250 Byte6_Data_4E2 "TP from HU to CLU (Juke box)";
CM_ SG_ 1250 Byte7_Data_4E2 "TP from HU to CLU (Juke box)";
CM_ BO_ 1248 "[TP] TP Message";
CM_ BO_ 479 "[PE] Periodic and On Event";
CM_ SG_ 479 C_DRVDRSW "Driver Door Switch";
CM_ SG_ 479 CF_Clu_LowfuelWarning "Low fuel warning information";
CM_ SG_ 479 CLU_PowerInfo "Cluster Power Ready information";
CM_ SG_ 479 C_DrivingModeState "Information of Driving Mode State";
CM_ SG_ 479 C_Clu_ActiveEcoSW "Indication of Active Eco Switch";
CM_ SG_ 479 C_Detent "Information in light";
CM_ SG_ 479 C_DrivingModeOn "Driving Mode display On signal";
CM_ BO_ 2015 "[TP] TP Message";
CM_ SG_ 2015 Byte0_TCP_7DF "TP";
CM_ SG_ 2015 Byte1_Data_7DF "TP";
CM_ SG_ 2015 Byte2_Data_7DF "TP";
CM_ SG_ 2015 Byte3_Data_7DF "TP";
CM_ SG_ 2015 Byte4_Data_7DF "TP";
CM_ SG_ 2015 Byte5_Data_7DF "TP";
CM_ SG_ 2015 Byte6_Data_7DF "TP";
CM_ SG_ 2015 Byte7_Data_7DF "TP";
CM_ BO_ 474 "[PE] Periodic and On Event";
CM_ SG_ 474 CF_Clu_AvgFCU "Average fuel consumption UNIT 
(Message ID 0x137 의 CF_Clu_AvgFCU신호와 같음)";
CM_ SG_ 474 CF_Clu_AvgFCL "Average fuel consumption information
(Message ID 0x137 의 CF_Clu_AvgFCl 신호와 같음)";
CM_ SG_ 474 CF_Clu_TermAvgSync "2.5 minutes Sync for AVN";
CM_ SG_ 474 CF_Clu_EcoDriveInf "Information of Economy Drive Indication
(Message ID 0x139의 CF_Clu_EcoDriveInf 신호와 같음)";
CM_ SG_ 474 CR_Clu_TermAvgFCI "2.5 minutes interval Average fuel consumption information";
CM_ SG_ 474 CF_CLU_EcoScore "누적 ECO (0 ... 9999)";
CM_ BO_ 1495 "[P] Periodic";
CM_ SG_ 1495 Clu_TripUnit "Trip Unit";
CM_ SG_ 1495 Clu_DTEWarn "DTE Warning";
CM_ SG_ 1495 Clu_DTE "DistanceToEmpty";
CM_ SG_ 1495 Clu_AFC "Average Fuel Consumption";
CM_ SG_ 1495 Clu_IFC "Instant Fuel Consumption";
CM_ SG_ 1495 Clu_Odometer "Odometer";
CM_ BO_ 1494 "[P] Periodic";
CM_ SG_ 1494 CF_TripUnit "Trip Unit";
CM_ SG_ 1494 CF_DTE "DistanceToEmpty";
CM_ BO_ 214 "[EC] On Event and On Change";
CM_ SG_ 214 AMP_SWVerMajor "SW Major Version of Amplifier";
CM_ SG_ 214 AMP_SWVerMinor "SW Major Version of Amplifier";
CM_ SG_ 214 AMP_CANVerMajor "SW Major Version of Amplifier";
CM_ SG_ 214 AMP_CANVerMinor "SW Major Version of Amplifier";
CM_ SG_ 214 AMP_RBDResult "RBD Result of Amplifier";
CM_ SG_ 214 AMP_MOSTErrorDiagResult "MOST Error Diagnosis Result of Amplifier";
CM_ SG_ 214 AMP_HWVerMajor "HW Major Version of Amplifier";
CM_ SG_ 214 AMP_HWVerMinor "HW Minor Version of Amplifier";
CM_ BO_ 1492 "[P] Periodic";
CM_ SG_ 1492 MM_CR_Fatc_AcnComCst_W "냉방장치 소비전력";
CM_ SG_ 1492 MM_CR_Ldc_PwrMon_W "기타전장부품 소비전력";
CM_ SG_ 1492 MM_CR_Fatc_PTCPwrCon_W "난방장치 소비전력";
CM_ SG_ 1492 MM_CR_BmsChgExp_T_Fast "급속충전 예상시간";
CM_ SG_ 1492 MM_CR_BmsChgExp_T_Slow "완속충전 예상시간";
CM_ BO_ 1491 "[P] Periodic";
CM_ SG_ 1491 MM_CF_Vcu_EvMod "Vehicle Stop : Motor, Tire, Battery 표시
EV Propulsion : Motor가 차량을 구동 . 배터리>모터>타이어로 흐름
Regeneration : 회생제동으로 배터리 충전. 타이어>모터>배터리로 흐름";
CM_ SG_ 1491 MM_CF_Vcu_GarSelDisp "Gear 선택 상태
Display Gear state";
CM_ SG_ 1491 MM_CF_Vcu_ThiBatTir "에너지 흐름도에서 에너지 흐름 표시
Energy Flow Thickness of Battery~Tire";
CM_ SG_ 1491 CR_Mcu_MotEstTqPc "Estimated motor torque";
CM_ SG_ 1491 CR_Mcu_MotActRotSpd_rpm "Actual motor rotation speed
전원이 Cluster에 투입되고, MCU에서 rpm이 전달되기 전까지 이 값은 의미가 없다. 이런 경우 rpm을 영(zero,0)으로 표시함";
CM_ BO_ 1490 "[P] Periodic";
CM_ SG_ 1490 MM_CR_Vcu_EcoSco "경제 운전 점수
ECO LEVEL 8개칸";
CM_ SG_ 1490 MM_CF_Vcu_PgmRun5 "Program Run Bit
100msec마다 변하는 값
경제운전에서 CF_Vcu_PgmRun5가 100ms마다
1씩 증가하고 있는 상태에서 CR_Vcu_EcoSco
E H 입력 시 점수 1점 증가";
CM_ SG_ 1490 MM_CR_Clu_Odometer_kph "Odometer-Mileage information";
CM_ BO_ 1489 "[P] Periodic";
CM_ BO_ 465 "[PE] Periodic and On Event";
CM_ SG_ 465 CF_Clu_EVDTEDisp "This signal indicates EV DTE
DTE 0 (Display --- on)
DTE(1~510)
Invalid (Display --- blinking 1Hz)";
CM_ SG_ 465 CF_Clu_GasDTEDisp "Cluster display Gasoline DTE
DTE 0 (Display --- on)
DTE(1~1023)
Invalid (Display --- blinking 1Hz)";
CM_ SG_ 465 MM_CR_Clu_TotalDTEDisp "Cluster display total DTE (Gasline DTE + EV DTE)
DTE 0 (Display --- on)
DTE(1~2046)
Invalid (Display --- blinking 1Hz)";
CM_ SG_ 465 CF_Clu_TripUnit "This signal indicates Distance UNIT
(Message ID 0x50C 의 CF_Clu_TripUnit 신호와 같음)";
CM_ BO_ 1232 "[TP] TP Message";
CM_ BO_ 1488 "[P] Periodic";
CM_ SG_ 1488 MM_CR_Mcu_VehSpd_Kph "vehicle speed calculated by MCU";
CM_ SG_ 1488 MM_CR_Mcu_VehSpdDec_Kph "The value below decimal point of vehicle speed 
real vehicle speed =CR_Mcu_VehSpd_Kph + CR_Mcu_VehSpdDec_Kph (over 2km/h)
입력차속이 2km/h 미만에서는 0km/h 표시";
CM_ SG_ 1488 MM_CR_Bms_Soc_Pc "배터리잔량
state of charge : 0~100%
Tx Node : BMS";
CM_ SG_ 1488 MM_CR_Vcu_TqMotClu_Pc "Motor Torque Ratio to cluster
shows motor power status.
-100.0~100.0%";
CM_ SG_ 1488 MM_CR_Bms_DrvEnaDist "주행가능거리 (표시범위0~255km)";
CM_ SG_ 1488 MM_CR_Clu_Soc_Seg "배터리잔량
state of charge : Seg 0~8
Tx Node : CLU";
CM_ BO_ 208 "[EC] On Event and On Change";
CM_ SG_ 208 CLU_SWVerMajor "SW Major Version of Cluster";
CM_ SG_ 208 CLU_SWVerMinor "SW Major Version of Cluster";
CM_ SG_ 208 CLU_CANVerMajor "SW Major Version of Cluster";
CM_ SG_ 208 CLU_CANVerMinor "SW Major Version of Cluster";
CM_ SG_ 208 CLU_HWVerMajor "HW Major Version of Cluster";
CM_ SG_ 208 CLU_HWVerMinor "HW Minor Version of Cluster";
CM_ BO_ 448 "[PE] Periodic and On Event";
CM_ SG_ 448 DATC_AqsLevelChg "AQS LEVEL CHANGE";
CM_ SG_ 448 RSELockOnOff "Head Unit RSE Lock REQ";
CM_ SG_ 448 DATC_AqsMode "AQS Mode";
CM_ SG_ 448 HU_Graphreset_Info "Fuel Economy Graph reset Information";
CM_ SG_ 448 HU_VRActivity "Acitivity of VR";
CM_ SG_ 448 HU_PhoneActivity "Acitivity of Phone Call";
CM_ SG_ 448 BlowerNoiseControl "Setting value of Adaptive blower noise control under Voice setup";
CM_ BO_ 1211 "[TP] TP Message";
CM_ SG_ 1211 Byte0_TCP_4BB "Contents related with Navigation 
Maximum size :256byte";
CM_ SG_ 1211 Byte1_Data_4BB "Contents related with Navigation 
Maximum size :256byte";
CM_ SG_ 1211 Byte2_Data_4BB "Contents related with Navigation 
Maximum size :256byte";
CM_ SG_ 1211 Byte3_Data_4BB "Contents related with Navigation 
Maximum size :256byte";
CM_ SG_ 1211 Byte4_Data_4BB "Contents related with Navigation 
Maximum size :256byte";
CM_ SG_ 1211 Byte5_Data_4BB "Contents related with Navigation 
Maximum size :256byte";
CM_ SG_ 1211 Byte6_Data_4BB "Contents related with Navigation 
Maximum size :256byte";
CM_ SG_ 1211 Byte7_Data_4BB "Contents related with Navigation 
Maximum size :256byte";
CM_ BO_ 1207 "[TP] TP Message";
CM_ BO_ 1206 "[TP] TP Message";
CM_ SG_ 1206 Byte0_TCP_4B6 "Channel Name of XM Satellite Radio";
CM_ SG_ 1206 Byte1_Data_4B6 "Channel Name of XM Satellite Radio";
CM_ SG_ 1206 Byte2_Data_4B6 "Channel Name of XM Satellite Radio";
CM_ SG_ 1206 Byte3_Data_4B6 "Channel Name of XM Satellite Radio";
CM_ SG_ 1206 Byte4_Data_4B6 "Channel Name of XM Satellite Radio";
CM_ SG_ 1206 Byte5_Data_4B6 "Channel Name of XM Satellite Radio";
CM_ SG_ 1206 Byte6_Data_4B6 "Channel Name of XM Satellite Radio";
CM_ SG_ 1206 Byte7_Data_4B6 "Channel Name of XM Satellite Radio";
CM_ BO_ 1204 "[TP] TP Message";
CM_ SG_ 1204 Byte0_TCP_4B4 "Contents releted with DMB";
CM_ SG_ 1204 Byte1_Data_4B4 "Contents releted with DMB";
CM_ SG_ 1204 Byte2_Data_4B4 "Contents releted with DMB";
CM_ SG_ 1204 Byte3_Data_4B4 "Contents releted with DMB";
CM_ SG_ 1204 Byte4_Data_4B4 "Contents releted with DMB";
CM_ SG_ 1204 Byte5_Data_4B4 "Contents releted with DMB";
CM_ SG_ 1204 Byte6_Data_4B4 "Contents releted with DMB";
CM_ SG_ 1204 Byte7_Data_4B4 "Contents releted with DMB";
CM_ BO_ 432 "[PE] Periodic and On Event";
CM_ SG_ 432 C_DATCOnOffReq "원격 DATC On/Off Request";
CM_ SG_ 432 C_DATCTempUnit "원격 DATC 온도설정 모드(섭씨/화씨)";
CM_ SG_ 432 C_DATCTempSet "Remote DATC to set the target temperature";
CM_ SG_ 432 TMU_IVRActivity "Acitivity of IVR";
CM_ SG_ 432 TMU_PhoneActivity "Activity of TMU Phone call";
CM_ BO_ 1195 "[TP] TP Message";
CM_ SG_ 1195 Byte0_TCP_4AB "Contents related with Navigation 
Maximum size :256byte";
CM_ SG_ 1195 Byte1_Data_4AB "Contents related with Navigation 
Maximum size :256byte";
CM_ SG_ 1195 Byte2_Data_4AB "Contents related with Navigation 
Maximum size :256byte";
CM_ SG_ 1195 Byte3_Data_4AB "Contents related with Navigation 
Maximum size :256byte";
CM_ SG_ 1195 Byte4_Data_4AB "Contents related with Navigation 
Maximum size :256byte";
CM_ SG_ 1195 Byte5_Data_4AB "Contents related with Navigation 
Maximum size :256byte";
CM_ SG_ 1195 Byte6_Data_4AB "Contents related with Navigation 
Maximum size :256byte";
CM_ SG_ 1195 Byte7_Data_4AB "Contents related with Navigation 
Maximum size :256byte";
CM_ BO_ 1191 "[TP] TP Message";
CM_ BO_ 1190 "[TP] TP Message";
CM_ SG_ 1190 Byte0_TCP_4A6 "Channel Name of XM Satellite Radio";
CM_ SG_ 1190 Byte1_Data_4A6 "Channel Name of XM Satellite Radio";
CM_ SG_ 1190 Byte2_Data_4A6 "Channel Name of XM Satellite Radio";
CM_ SG_ 1190 Byte3_Data_4A6 "Channel Name of XM Satellite Radio";
CM_ SG_ 1190 Byte4_Data_4A6 "Channel Name of XM Satellite Radio";
CM_ SG_ 1190 Byte5_Data_4A6 "Channel Name of XM Satellite Radio";
CM_ SG_ 1190 Byte6_Data_4A6 "Channel Name of XM Satellite Radio";
CM_ SG_ 1190 Byte7_Data_4A6 "Channel Name of XM Satellite Radio";
CM_ BO_ 1188 "[TP] TP Message";
CM_ SG_ 1188 Byte0_TCP_4A4 "Contents releted with DMB";
CM_ SG_ 1188 Byte1_Data_4A4 "Contents releted with DMB";
CM_ SG_ 1188 Byte2_Data_4A4 "Contents releted with DMB";
CM_ SG_ 1188 Byte3_Data_4A4 "Contents releted with DMB";
CM_ SG_ 1188 Byte4_Data_4A4 "Contents releted with DMB";
CM_ SG_ 1188 Byte5_Data_4A4 "Contents releted with DMB";
CM_ SG_ 1188 Byte6_Data_4A4 "Contents releted with DMB";
CM_ SG_ 1188 Byte7_Data_4A4 "Contents releted with DMB";
CM_ BO_ 1179 "[TP] TP Message";
CM_ BO_ 1178 "[TP] TP Message";
CM_ BO_ 410 "[PE] Periodic and On Event";
CM_ SG_ 410 VCDC_SelDiscNo "Virtual CDC";
CM_ SG_ 410 VCDC_TrackChapterNo "Virtual CDC";
CM_ SG_ 410 VCDC_PlayTime "Virtual CDC";
CM_ SG_ 410 MLT_PlayTime "More like this";
CM_ BO_ 1176 "[TP] TP Message";
CM_ BO_ 1175 "[TP] TP Message";
CM_ BO_ 407 "[PE] Periodic and On Event";
CM_ SG_ 407 HU_LanguageInfo "System Language Info. for Display Font";
CM_ SG_ 407 HU_MuteStatus "System Mute Display Info.";
CM_ SG_ 407 HU_VolumeStatus "AVN Volume Info.";
CM_ SG_ 407 HU_NaviDisp "Navi Display status on Front Monito";
CM_ SG_ 407 HU_NaviStatus "Navigation Status (Booting, Normal Operation, No SD card)";
CM_ SG_ 407 HU_DistanceUnit "Distance Unit (m, km, mile, feet, yard)";
CM_ SG_ 407 HU_Navigation_On_Off "Navigation On/Off";
CM_ BO_ 1942 "[TP] TP Message";
CM_ BO_ 406 "[PE] Periodic and On Event";
CM_ SG_ 406 C_SDARS_ChannelNo "XM SIRIUS Channel Number";
CM_ SG_ 406 HD_SPS_ChannelNo "Supplementary Program Service Channel No information of HD Radio";
CM_ SG_ 406 DAB_ServiceFollowing "DAB to DAB/DAB to FM Service Following icon";
CM_ SG_ 406 SXM_ChannelNo "SXM Channel Number
Range 0~999";
CM_ BO_ 1941 "[TP] TP Message";
CM_ BO_ 1173 "[TP] TP Message";
CM_ BO_ 405 "[PE] Periodic and On Event";
CM_ SG_ 405 HU_IntegPresetNum "Integrated Preset Number Information.
(Use this Signal after Premium AVN 3.0 / Digital Audio)";
CM_ SG_ 405 DMB_PresetNo "(Do not use this signal after Premium 3.0 / Diplay Audio)
Use IntegPresetNum@HU_CLU_PE_03 instead";
CM_ SG_ 405 RADIO_PresetNo "(Do not use this signal after Premium 3.0 / Diplay Audio)
Use IntegPresetNum@HU_CLU_PE_03 instead";
CM_ SG_ 405 HU_Opstate_DIS2 "AVN Operation Status for Premimum 3.0";
CM_ BO_ 1168 "[TP] TP Message";
CM_ BO_ 1936 "[TP] TP Message";
CM_ BO_ 1167 "[TP] TP Message";
CM_ BO_ 1166 "[TP] TP Message";
CM_ BO_ 1165 "[TP] TP Message";
CM_ BO_ 1164 "[TP] TP Message";
BA_DEF_ SG_  "Gatewaysignal" ENUM  "No","M-B","B-M","M-C","C-M","M-C-B";
BA_DEF_ SG_  "GenSigEnvVarType" ENUM  "Int","Float","undef";
BA_DEF_ SG_  "GenSigSendType" ENUM  "Cyclic","OnWrite","OnWriteWithRepetition","OnChange","OnChangeWithRepetition","IfActive","IfActiveWithRepetition","NoSigSendType";
BA_DEF_ SG_  "GenSigStartValue" INT 0 0;
BA_DEF_ SG_  "GwSigLatencyTime" INT 0 65535;
BA_DEF_ SG_  "GwSigMissingSourceType" ENUM  "Undef","OldValue","DefaultValue","InitialValue";
BA_DEF_ SG_  "NmNetworkRequest" ENUM  "No","Yes";
BA_DEF_ SG_  "NmNetworkRequestHoldingTime" INT 0 65535;
BA_DEF_ SG_  "Purpose" ENUM  "<t.b.d.>","Function","Diagnostic","Development","NM";
BA_DEF_ SG_  "SignalCategory" HEX 10 15;
BA_DEF_ SG_  "TimeoutValue" STRING ;
BA_DEF_ SG_  "UpdateRateMax" INT 0 0;
BA_DEF_ SG_  "UpdateRateMin" INT 0 0;
BA_DEF_ SG_  "Validity" ENUM  "B+","ACC","IGN1","IGN2";
BA_DEF_ BO_  "DiagRequest" ENUM  "No","Yes";
BA_DEF_ BO_  "DiagResponse" ENUM  "No","Yes";
BA_DEF_ BO_  "DiagState" ENUM  "No","Yes";
BA_DEF_ BO_  "GenMsgCycleTime" INT 0 100000;
BA_DEF_ BO_  "GenMsgCycleTimeFast" INT 0 500;
BA_DEF_ BO_  "GenMsgDelayTime" INT 0 20;
BA_DEF_ BO_  "GenMsgEVName" STRING ;
BA_DEF_ BO_  "GenMsgILSupport" ENUM  "No","Yes";
BA_DEF_ BO_  "GenMsgNrOfRepetition" INT 0 3;
BA_DEF_ BO_  "GenMsgSendType" ENUM  "Cyclic","not_used","not_used","not_used","not_used","not_used","not_used","not_used","NoMsgSendType";
BA_DEF_ BO_  "GenMsgStartDelayTime" INT 0 2000;
BA_DEF_ BO_  "NmMessage" ENUM  "No","Yes";
BA_DEF_ BO_  "RoutingType" ENUM  "<n.a.>","Direct","Indirect";
BA_DEF_ BO_  "TpMessage" ENUM  "No","Yes";
BA_DEF_ BO_  "TpTxIndex" INT 0 255;
BA_DEF_ BU_  "GenNodSleepTime" INT 1375 1650;
BA_DEF_ BU_  "ILUsed" ENUM  "No","Yes";
BA_DEF_ BU_  "NmCAN" INT 1 2;
BA_DEF_ BU_  "NmNode" ENUM  "No","Yes";
BA_DEF_ BU_  "NmStationAddress" HEX 0 255;
BA_DEF_ BU_  "NodeLayerModules" STRING ;
BA_DEF_  "Baudrate" INT 50000 500000;
BA_DEF_  "BusType" STRING ;
BA_DEF_  "GenEnvVarEndingDsp" STRING ;
BA_DEF_  "GenEnvVarEndingSnd" STRING ;
BA_DEF_  "GenEnvVarPrefix" STRING ;
BA_DEF_  "GenNWMApBusSleep" STRING ;
BA_DEF_  "GenNWMApCanNormal" STRING ;
BA_DEF_  "GenNWMApCanOff" STRING ;
BA_DEF_  "GenNWMApCanOn" STRING ;
BA_DEF_  "GenNWMApCanSleep" STRING ;
BA_DEF_  "GenNWMApCanWakeUp" STRING ;
BA_DEF_  "GenNWMGotoMode_Awake" STRING ;
BA_DEF_  "GenNWMGotoMode_BusSleep" STRING ;
BA_DEF_  "GenNWMSleepTime" INT 1375 1650;
BA_DEF_  "GenNWMTalkNM" STRING ;
BA_DEF_  "Manufacturer" STRING ;
BA_DEF_  "NmBaseAddress" HEX 0 2047;
BA_DEF_  "NmMessageCount" INT 0 128;
BA_DEF_  "NmType" STRING ;
BA_DEF_  "SamplePointMax" INT 50 85;
BA_DEF_  "SamplePointMin" INT 55 85;
BA_DEF_  "SyncJumpWidthMax" INT 1 8;
BA_DEF_  "SyncJumpWidthMin" INT 1 4;
BA_DEF_  "VersionDay" INT 1 31;
BA_DEF_  "VersionMonth" INT 1 12;
BA_DEF_  "VersionNumber" INT 0 999999;
BA_DEF_  "VersionWeek" INT 1 53;
BA_DEF_  "VersionYear" INT 0 9999;
BA_DEF_REL_ BU_SG_REL_  "GenSigTimeoutTime" INT 0 7000;
BA_DEF_DEF_  "Gatewaysignal" "No";
BA_DEF_DEF_  "GenSigEnvVarType" "undef";
BA_DEF_DEF_  "GenSigSendType" "NoSigSendType";
BA_DEF_DEF_  "GenSigStartValue" 0;
BA_DEF_DEF_  "GwSigLatencyTime" 40;
BA_DEF_DEF_  "GwSigMissingSourceType" "Undef";
BA_DEF_DEF_  "NmNetworkRequest" "No";
BA_DEF_DEF_  "NmNetworkRequestHoldingTime" 0;
BA_DEF_DEF_  "Purpose" "<t.b.d.>";
BA_DEF_DEF_  "SignalCategory" 12;
BA_DEF_DEF_  "TimeoutValue" "";
BA_DEF_DEF_  "UpdateRateMax" 0;
BA_DEF_DEF_  "UpdateRateMin" 0;
BA_DEF_DEF_  "Validity" "ACC";
BA_DEF_DEF_  "DiagRequest" "No";
BA_DEF_DEF_  "DiagResponse" "No";
BA_DEF_DEF_  "DiagState" "No";
BA_DEF_DEF_  "GenMsgCycleTime" 0;
BA_DEF_DEF_  "GenMsgCycleTimeFast" 0;
BA_DEF_DEF_  "GenMsgDelayTime" 20;
BA_DEF_DEF_  "GenMsgEVName" "@Signame";
BA_DEF_DEF_  "GenMsgILSupport" "Yes";
BA_DEF_DEF_  "GenMsgNrOfRepetition" 0;
BA_DEF_DEF_  "GenMsgSendType" "NoMsgSendType";
BA_DEF_DEF_  "GenMsgStartDelayTime" 0;
BA_DEF_DEF_  "NmMessage" "No";
BA_DEF_DEF_  "RoutingType" "<n.a.>";
BA_DEF_DEF_  "TpMessage" "No";
BA_DEF_DEF_  "TpTxIndex" 0;
BA_DEF_DEF_  "GenNodSleepTime" 1500;
BA_DEF_DEF_  "ILUsed" "Yes";
BA_DEF_DEF_  "NmCAN" 1;
BA_DEF_DEF_  "NmNode" "Yes";
BA_DEF_DEF_  "NmStationAddress" 0;
BA_DEF_DEF_  "NodeLayerModules" "oseknm01.dll";
BA_DEF_DEF_  "Baudrate" 100000;
BA_DEF_DEF_  "BusType" "CAN";
BA_DEF_DEF_  "GenEnvVarEndingDsp" "Dsp_";
BA_DEF_DEF_  "GenEnvVarEndingSnd" "_";
BA_DEF_DEF_  "GenEnvVarPrefix" "Env";
BA_DEF_DEF_  "GenNWMApBusSleep" "ApplNmCanBusSleep()";
BA_DEF_DEF_  "GenNWMApCanNormal" "ApplNmCanNormal()";
BA_DEF_DEF_  "GenNWMApCanOff" "ApplCanOffline()";
BA_DEF_DEF_  "GenNWMApCanOn" "ApplCanOnline()";
BA_DEF_DEF_  "GenNWMApCanSleep" "ApplNmCanSleep()";
BA_DEF_DEF_  "GenNWMApCanWakeUp" "ApplCanWakeUp()";
BA_DEF_DEF_  "GenNWMGotoMode_Awake" "GotoMode_Awake()";
BA_DEF_DEF_  "GenNWMGotoMode_BusSleep" "GotoMode_BusSleep()";
BA_DEF_DEF_  "GenNWMSleepTime" 1500;
BA_DEF_DEF_  "GenNWMTalkNM" "TalkNM()";
BA_DEF_DEF_  "Manufacturer" "HMC";
BA_DEF_DEF_  "NmBaseAddress" 1024;
BA_DEF_DEF_  "NmMessageCount" 128;
BA_DEF_DEF_  "NmType" "Vector";
BA_DEF_DEF_  "SamplePointMax" 82;
BA_DEF_DEF_  "SamplePointMin" 75;
BA_DEF_DEF_  "SyncJumpWidthMax" 3;
BA_DEF_DEF_  "SyncJumpWidthMin" 2;
BA_DEF_DEF_  "VersionDay" 1;
BA_DEF_DEF_  "VersionMonth" 1;
BA_DEF_DEF_  "VersionNumber" 0;
BA_DEF_DEF_  "VersionWeek" 1;
BA_DEF_DEF_  "VersionYear" 2010;
BA_DEF_DEF_REL_ "GenSigTimeoutTime" 700;
BA_ "VersionDay" 5;
BA_ "VersionNumber" 102;
BA_ "VersionWeek" 2;
BA_ "VersionYear" 2015;
BA_ "NmStationAddress" BU_ CLOCK 68;
BA_ "NmStationAddress" BU_ HUD 84;
BA_ "NmStationAddress" BU_ H_U 64;
BA_ "NmStationAddress" BU_ DATC 67;
BA_ "NmStationAddress" BU_ CCP 81;
BA_ "NmStationAddress" BU_ KMA_TMU 76;
BA_ "NmStationAddress" BU_ CUBIS 74;
BA_ "NmStationAddress" BU_ TMU 75;
BA_ "NmStationAddress" BU_ IPM 71;
BA_ "NmStationAddress" BU_ RSE_R 83;
BA_ "NmStationAddress" BU_ RRC 69;
BA_ "NmStationAddress" BU_ CGW 85;
BA_ "NmStationAddress" BU_ RSE_L 82;
BA_ "NmStationAddress" BU_ AMP 72;
BA_ "NmStationAddress" BU_ EDT 79;
BA_ "NmStationAddress" BU_ SWRC 86;
BA_ "NmStationAddress" BU_ IBOX 78;
BA_ "NmStationAddress" BU_ CLU 77;
BA_ "NmStationAddress" BU_ FHCU 73;
BA_ "NmStationAddress" BU_ ASD 70;
BA_ "NmStationAddress" BU_ MON 65;
BA_ "NmStationAddress" BU_ AVM 80;
BA_ "NmStationAddress" BU_ KBD 66;
BA_ "GenMsgILSupport" BO_ 2046 0;
BA_ "TpMessage" BO_ 2046 1;
BA_ "TpTxIndex" BO_ 2046 6;
BA_ "GenMsgCycleTimeFast" BO_ 251 40;
BA_ "GenMsgNrOfRepetition" BO_ 251 3;
BA_ "GenMsgCycleTimeFast" BO_ 250 40;
BA_ "GenMsgNrOfRepetition" BO_ 250 3;
BA_ "GenMsgILSupport" BO_ 1269 0;
BA_ "TpMessage" BO_ 1269 1;
BA_ "TpTxIndex" BO_ 1269 45;
BA_ "GenMsgILSupport" BO_ 1268 0;
BA_ "TpMessage" BO_ 1268 1;
BA_ "TpTxIndex" BO_ 1268 45;
BA_ "GenMsgILSupport" BO_ 1267 0;
BA_ "TpMessage" BO_ 1267 1;
BA_ "TpTxIndex" BO_ 1267 44;
BA_ "GenMsgILSupport" BO_ 1266 0;
BA_ "TpMessage" BO_ 1266 1;
BA_ "TpTxIndex" BO_ 1266 44;
BA_ "GenMsgILSupport" BO_ 1263 0;
BA_ "TpMessage" BO_ 1263 1;
BA_ "TpTxIndex" BO_ 1263 39;
BA_ "GenMsgILSupport" BO_ 1262 0;
BA_ "TpMessage" BO_ 1262 1;
BA_ "TpTxIndex" BO_ 1262 39;
BA_ "GenMsgILSupport" BO_ 1261 0;
BA_ "TpMessage" BO_ 1261 1;
BA_ "TpTxIndex" BO_ 1261 38;
BA_ "GenMsgILSupport" BO_ 1260 0;
BA_ "TpMessage" BO_ 1260 1;
BA_ "TpTxIndex" BO_ 1260 38;
BA_ "GenMsgSendType" BO_ 491 0;
BA_ "GenMsgCycleTime" BO_ 491 200;
BA_ "GenMsgCycleTimeFast" BO_ 491 40;
BA_ "GenMsgNrOfRepetition" BO_ 491 3;
BA_ "GenMsgILSupport" BO_ 1259 0;
BA_ "TpMessage" BO_ 1259 1;
BA_ "TpTxIndex" BO_ 1259 37;
BA_ "GenMsgILSupport" BO_ 1258 0;
BA_ "TpMessage" BO_ 1258 1;
BA_ "TpTxIndex" BO_ 1258 37;
BA_ "GenMsgILSupport" BO_ 1257 0;
BA_ "TpMessage" BO_ 1257 1;
BA_ "TpTxIndex" BO_ 1257 36;
BA_ "GenMsgILSupport" BO_ 1256 0;
BA_ "TpMessage" BO_ 1256 1;
BA_ "TpTxIndex" BO_ 1256 36;
BA_ "GenMsgILSupport" BO_ 1255 0;
BA_ "TpMessage" BO_ 1255 1;
BA_ "TpTxIndex" BO_ 1255 35;
BA_ "GenMsgSendType" BO_ 487 0;
BA_ "GenMsgCycleTime" BO_ 487 200;
BA_ "GenMsgILSupport" BO_ 1254 0;
BA_ "TpMessage" BO_ 1254 1;
BA_ "TpTxIndex" BO_ 1254 35;
BA_ "GenMsgSendType" BO_ 486 0;
BA_ "GenMsgCycleTime" BO_ 486 200;
BA_ "GenMsgStartDelayTime" BO_ 486 130;
BA_ "GenMsgCycleTimeFast" BO_ 229 40;
BA_ "GenMsgNrOfRepetition" BO_ 229 3;
BA_ "GenMsgILSupport" BO_ 1253 0;
BA_ "TpMessage" BO_ 1253 1;
BA_ "TpTxIndex" BO_ 1253 34;
BA_ "GenMsgSendType" BO_ 485 0;
BA_ "GenMsgCycleTime" BO_ 485 200;
BA_ "GenMsgCycleTimeFast" BO_ 485 40;
BA_ "GenMsgNrOfRepetition" BO_ 485 3;
BA_ "GenMsgStartDelayTime" BO_ 485 140;
BA_ "GenMsgILSupport" BO_ 1252 0;
BA_ "TpMessage" BO_ 1252 1;
BA_ "TpTxIndex" BO_ 1252 34;
BA_ "GenMsgILSupport" BO_ 1251 0;
BA_ "TpMessage" BO_ 1251 1;
BA_ "TpTxIndex" BO_ 1251 33;
BA_ "GenMsgILSupport" BO_ 1250 0;
BA_ "TpMessage" BO_ 1250 1;
BA_ "TpTxIndex" BO_ 1250 33;
BA_ "GenMsgILSupport" BO_ 1248 0;
BA_ "TpMessage" BO_ 1248 1;
BA_ "TpTxIndex" BO_ 1248 29;
BA_ "GenMsgSendType" BO_ 479 0;
BA_ "GenMsgCycleTime" BO_ 479 200;
BA_ "GenMsgCycleTimeFast" BO_ 479 40;
BA_ "GenMsgNrOfRepetition" BO_ 479 3;
BA_ "DiagState" BO_ 2015 1;
BA_ "GenMsgILSupport" BO_ 2015 0;
BA_ "TpMessage" BO_ 2015 1;
BA_ "GenMsgSendType" BO_ 474 0;
BA_ "GenMsgCycleTime" BO_ 474 200;
BA_ "GenMsgSendType" BO_ 1495 0;
BA_ "GenMsgCycleTime" BO_ 1495 1000;
BA_ "GenMsgSendType" BO_ 1494 0;
BA_ "GenMsgCycleTime" BO_ 1494 200;
BA_ "GenMsgCycleTimeFast" BO_ 214 40;
BA_ "GenMsgNrOfRepetition" BO_ 214 3;
BA_ "GenMsgSendType" BO_ 1492 0;
BA_ "GenMsgCycleTime" BO_ 1492 200;
BA_ "GenMsgSendType" BO_ 1491 0;
BA_ "GenMsgCycleTime" BO_ 1491 200;
BA_ "GenMsgSendType" BO_ 1490 0;
BA_ "GenMsgCycleTime" BO_ 1490 200;
BA_ "GenMsgNrOfRepetition" BO_ 1489 3;
BA_ "GenMsgCycleTimeFast" BO_ 1489 40;
BA_ "GenMsgSendType" BO_ 1489 0;
BA_ "GenMsgCycleTime" BO_ 1489 200;
BA_ "GenMsgSendType" BO_ 465 0;
BA_ "GenMsgCycleTime" BO_ 465 200;
BA_ "GenMsgILSupport" BO_ 1232 0;
BA_ "TpMessage" BO_ 1232 1;
BA_ "TpTxIndex" BO_ 1232 29;
BA_ "GenMsgSendType" BO_ 1488 0;
BA_ "GenMsgCycleTime" BO_ 1488 200;
BA_ "GenMsgCycleTimeFast" BO_ 208 40;
BA_ "GenMsgNrOfRepetition" BO_ 208 3;
BA_ "GenMsgSendType" BO_ 448 0;
BA_ "GenMsgCycleTime" BO_ 448 1000;
BA_ "GenMsgCycleTimeFast" BO_ 448 40;
BA_ "GenMsgNrOfRepetition" BO_ 448 3;
BA_ "GenMsgILSupport" BO_ 1211 0;
BA_ "TpMessage" BO_ 1211 1;
BA_ "TpTxIndex" BO_ 1211 5;
BA_ "GenMsgILSupport" BO_ 1207 0;
BA_ "TpMessage" BO_ 1207 1;
BA_ "TpTxIndex" BO_ 1207 40;
BA_ "GenMsgILSupport" BO_ 1206 0;
BA_ "TpMessage" BO_ 1206 1;
BA_ "TpTxIndex" BO_ 1206 4;
BA_ "GenMsgILSupport" BO_ 1204 0;
BA_ "TpMessage" BO_ 1204 1;
BA_ "TpTxIndex" BO_ 1204 3;
BA_ "GenMsgSendType" BO_ 432 0;
BA_ "GenMsgCycleTime" BO_ 432 1000;
BA_ "GenMsgCycleTimeFast" BO_ 432 40;
BA_ "GenMsgNrOfRepetition" BO_ 432 3;
BA_ "GenMsgILSupport" BO_ 1195 0;
BA_ "TpMessage" BO_ 1195 1;
BA_ "TpTxIndex" BO_ 1195 5;
BA_ "GenMsgILSupport" BO_ 1191 0;
BA_ "TpMessage" BO_ 1191 1;
BA_ "TpTxIndex" BO_ 1191 40;
BA_ "GenMsgILSupport" BO_ 1190 0;
BA_ "TpMessage" BO_ 1190 1;
BA_ "TpTxIndex" BO_ 1190 4;
BA_ "GenMsgILSupport" BO_ 1188 0;
BA_ "TpMessage" BO_ 1188 1;
BA_ "TpTxIndex" BO_ 1188 3;
BA_ "GenMsgILSupport" BO_ 1179 0;
BA_ "TpMessage" BO_ 1179 1;
BA_ "TpTxIndex" BO_ 1179 9;
BA_ "GenMsgILSupport" BO_ 1178 0;
BA_ "TpMessage" BO_ 1178 1;
BA_ "TpTxIndex" BO_ 1178 8;
BA_ "GenMsgSendType" BO_ 410 0;
BA_ "GenMsgCycleTime" BO_ 410 200;
BA_ "GenMsgCycleTimeFast" BO_ 410 40;
BA_ "GenMsgNrOfRepetition" BO_ 410 3;
BA_ "GenMsgStartDelayTime" BO_ 410 70;
BA_ "GenMsgILSupport" BO_ 1176 0;
BA_ "TpMessage" BO_ 1176 1;
BA_ "TpTxIndex" BO_ 1176 28;
BA_ "GenMsgILSupport" BO_ 1175 0;
BA_ "TpMessage" BO_ 1175 1;
BA_ "TpTxIndex" BO_ 1175 14;
BA_ "GenMsgSendType" BO_ 407 0;
BA_ "GenMsgCycleTime" BO_ 407 1000;
BA_ "GenMsgCycleTimeFast" BO_ 407 40;
BA_ "GenMsgNrOfRepetition" BO_ 407 3;
BA_ "GenMsgStartDelayTime" BO_ 407 160;
BA_ "DiagResponse" BO_ 1942 1;
BA_ "GenMsgILSupport" BO_ 1942 0;
BA_ "TpMessage" BO_ 1942 1;
BA_ "TpTxIndex" BO_ 1942 21;
BA_ "GenMsgSendType" BO_ 406 0;
BA_ "GenMsgCycleTime" BO_ 406 200;
BA_ "GenMsgCycleTimeFast" BO_ 406 40;
BA_ "GenMsgNrOfRepetition" BO_ 406 3;
BA_ "GenMsgStartDelayTime" BO_ 406 80;
BA_ "DiagRequest" BO_ 1941 1;
BA_ "GenMsgILSupport" BO_ 1941 0;
BA_ "TpMessage" BO_ 1941 1;
BA_ "TpTxIndex" BO_ 1941 21;
BA_ "GenMsgILSupport" BO_ 1173 0;
BA_ "TpMessage" BO_ 1173 1;
BA_ "TpTxIndex" BO_ 1173 2;
BA_ "GenMsgSendType" BO_ 405 0;
BA_ "GenMsgCycleTime" BO_ 405 200;
BA_ "GenMsgStartDelayTime" BO_ 405 50;
BA_ "GenMsgCycleTimeFast" BO_ 405 40;
BA_ "GenMsgNrOfRepetition" BO_ 405 3;
BA_ "GenMsgILSupport" BO_ 1168 0;
BA_ "TpMessage" BO_ 1168 1;
BA_ "TpTxIndex" BO_ 1168 14;
BA_ "DiagState" BO_ 1936 1;
BA_ "GenMsgILSupport" BO_ 1936 0;
BA_ "TpMessage" BO_ 1936 1;
BA_ "GenMsgILSupport" BO_ 1167 0;
BA_ "TpMessage" BO_ 1167 1;
BA_ "TpTxIndex" BO_ 1167 8;
BA_ "GenMsgILSupport" BO_ 1166 0;
BA_ "TpMessage" BO_ 1166 1;
BA_ "TpTxIndex" BO_ 1166 28;
BA_ "GenMsgILSupport" BO_ 1165 0;
BA_ "TpMessage" BO_ 1165 1;
BA_ "TpTxIndex" BO_ 1165 2;
BA_ "GenMsgILSupport" BO_ 1164 0;
BA_ "TpMessage" BO_ 1164 1;
BA_ "TpTxIndex" BO_ 1164 9;
BA_ "TimeoutValue" SG_ 3221225472 C_WHEEL_FL "Old Value";
BA_ "Validity" SG_ 3221225472 C_WHEEL_FL 2;
BA_ "TimeoutValue" SG_ 3221225472 C_WHEEL_FR "Old Value";
BA_ "Validity" SG_ 3221225472 C_WHEEL_FR 2;
BA_ "TimeoutValue" SG_ 3221225472 C_WHEEL_RL "Old Value";
BA_ "Validity" SG_ 3221225472 C_WHEEL_RL 2;
BA_ "TimeoutValue" SG_ 3221225472 C_WHEEL_RR "Old Value";
BA_ "Validity" SG_ 3221225472 C_WHEEL_RR 2;
BA_ "GenSigSendType" SG_ 251 HU_GPS_Year 4;
BA_ "GenSigStartValue" SG_ 251 HU_GPS_Year 255;
BA_ "NmNetworkRequest" SG_ 251 HU_GPS_Year 1;
BA_ "GenSigSendType" SG_ 251 HU_GPS_Month 4;
BA_ "GenSigStartValue" SG_ 251 HU_GPS_Month 255;
BA_ "NmNetworkRequest" SG_ 251 HU_GPS_Month 1;
BA_ "GenSigSendType" SG_ 251 HU_GPS_Day 4;
BA_ "GenSigStartValue" SG_ 251 HU_GPS_Day 255;
BA_ "NmNetworkRequest" SG_ 251 HU_GPS_Day 1;
BA_ "GenSigSendType" SG_ 251 HU_GPS_Hour 4;
BA_ "GenSigStartValue" SG_ 251 HU_GPS_Hour 255;
BA_ "NmNetworkRequest" SG_ 251 HU_GPS_Hour 1;
BA_ "GenSigSendType" SG_ 251 HU_GPS_Minute 4;
BA_ "GenSigStartValue" SG_ 251 HU_GPS_Minute 255;
BA_ "NmNetworkRequest" SG_ 251 HU_GPS_Minute 1;
BA_ "GenSigSendType" SG_ 251 HU_GPS_Second 4;
BA_ "GenSigStartValue" SG_ 251 HU_GPS_Second 255;
BA_ "NmNetworkRequest" SG_ 251 HU_GPS_Second 1;
BA_ "GenSigSendType" SG_ 250 HU_VoiceRecCom 4;
BA_ "GenSigStartValue" SG_ 250 HU_VoiceRecCom 7;
BA_ "NmNetworkRequest" SG_ 250 HU_VoiceRecCom 1;
BA_ "GenSigSendType" SG_ 250 HU_LangChgCom 4;
BA_ "GenSigStartValue" SG_ 250 HU_LangChgCom 7;
BA_ "NmNetworkRequest" SG_ 250 HU_LangChgCom 1;
BA_ "GenSigSendType" SG_ 250 HU_CallEndCmd 4;
BA_ "GenSigStartValue" SG_ 250 HU_CallEndCmd 3;
BA_ "NmNetworkRequest" SG_ 250 HU_CallEndCmd 1;
BA_ "GenSigSendType" SG_ 250 HU_ServiceReqtID 4;
BA_ "GenSigStartValue" SG_ 250 HU_ServiceReqtID 15;
BA_ "NmNetworkRequest" SG_ 250 HU_ServiceReqtID 1;
BA_ "GenSigSendType" SG_ 250 HU_MicReqCmd 4;
BA_ "GenSigStartValue" SG_ 250 HU_MicReqCmd 3;
BA_ "NmNetworkRequest" SG_ 250 HU_MicReqCmd 1;
BA_ "GenSigSendType" SG_ 250 HU_SeviceAction 4;
BA_ "GenSigStartValue" SG_ 250 HU_SeviceAction 7;
BA_ "NmNetworkRequest" SG_ 250 HU_SeviceAction 1;
BA_ "GenSigSendType" SG_ 250 HU_eCallStatus 4;
BA_ "GenSigStartValue" SG_ 250 HU_eCallStatus 3;
BA_ "NmNetworkRequest" SG_ 250 HU_eCallStatus 1;
BA_ "GenSigSendType" SG_ 491 C_DRVDoorStatus 4;
BA_ "GenSigStartValue" SG_ 491 C_DRVDoorStatus 3;
BA_ "Gatewaysignal" SG_ 491 C_DRVDoorStatus 2;
BA_ "NmNetworkRequest" SG_ 491 C_DRVDoorStatus 1;
BA_ "NmNetworkRequestHoldingTime" SG_ 491 C_DRVDoorStatus 5;
BA_ "TimeoutValue" SG_ 491 C_DRVDoorStatus "Old Value";
BA_ "Validity" SG_ 491 C_DRVDoorStatus 0;
BA_ "GenSigSendType" SG_ 491 C_ASTDoorStatus 4;
BA_ "GenSigStartValue" SG_ 491 C_ASTDoorStatus 3;
BA_ "Gatewaysignal" SG_ 491 C_ASTDoorStatus 2;
BA_ "NmNetworkRequest" SG_ 491 C_ASTDoorStatus 1;
BA_ "NmNetworkRequestHoldingTime" SG_ 491 C_ASTDoorStatus 5;
BA_ "TimeoutValue" SG_ 491 C_ASTDoorStatus "Old Value";
BA_ "Validity" SG_ 491 C_ASTDoorStatus 0;
BA_ "GenSigSendType" SG_ 491 C_RLDoorStatus 4;
BA_ "GenSigStartValue" SG_ 491 C_RLDoorStatus 3;
BA_ "Gatewaysignal" SG_ 491 C_RLDoorStatus 2;
BA_ "NmNetworkRequest" SG_ 491 C_RLDoorStatus 1;
BA_ "NmNetworkRequestHoldingTime" SG_ 491 C_RLDoorStatus 5;
BA_ "TimeoutValue" SG_ 491 C_RLDoorStatus "Old Value";
BA_ "Validity" SG_ 491 C_RLDoorStatus 0;
BA_ "GenSigSendType" SG_ 491 C_RRDoorStatus 4;
BA_ "GenSigStartValue" SG_ 491 C_RRDoorStatus 3;
BA_ "Gatewaysignal" SG_ 491 C_RRDoorStatus 2;
BA_ "NmNetworkRequest" SG_ 491 C_RRDoorStatus 1;
BA_ "NmNetworkRequestHoldingTime" SG_ 491 C_RRDoorStatus 5;
BA_ "TimeoutValue" SG_ 491 C_RRDoorStatus "Old Value";
BA_ "Validity" SG_ 491 C_RRDoorStatus 0;
BA_ "GenSigSendType" SG_ 491 C_TrunkStatus 4;
BA_ "GenSigStartValue" SG_ 491 C_TrunkStatus 3;
BA_ "Gatewaysignal" SG_ 491 C_TrunkStatus 2;
BA_ "NmNetworkRequest" SG_ 491 C_TrunkStatus 1;
BA_ "NmNetworkRequestHoldingTime" SG_ 491 C_TrunkStatus 5;
BA_ "TimeoutValue" SG_ 491 C_TrunkStatus "Old Value";
BA_ "Validity" SG_ 491 C_TrunkStatus 0;
BA_ "GenSigSendType" SG_ 491 C_OSMirrorStatus 4;
BA_ "GenSigStartValue" SG_ 491 C_OSMirrorStatus 3;
BA_ "Gatewaysignal" SG_ 491 C_OSMirrorStatus 2;
BA_ "NmNetworkRequest" SG_ 491 C_OSMirrorStatus 1;
BA_ "NmNetworkRequestHoldingTime" SG_ 491 C_OSMirrorStatus 5;
BA_ "TimeoutValue" SG_ 491 C_OSMirrorStatus "Old Value";
BA_ "Validity" SG_ 491 C_OSMirrorStatus 0;
BA_ "GenSigSendType" SG_ 487 Navi_DistToPoint1_F 3;
BA_ "GenSigStartValue" SG_ 487 Navi_DistToPoint1_F 15;
BA_ "TimeoutValue" SG_ 487 Navi_DistToPoint1_F "Old Value";
BA_ "GenSigSendType" SG_ 487 Navi_DistToPoint1_I 3;
BA_ "GenSigStartValue" SG_ 487 Navi_DistToPoint1_I 4095;
BA_ "TimeoutValue" SG_ 487 Navi_DistToPoint1_I "Old Value";
BA_ "GenSigSendType" SG_ 487 Navi_DistToPoint1_U 3;
BA_ "GenSigStartValue" SG_ 487 Navi_DistToPoint1_U 15;
BA_ "TimeoutValue" SG_ 487 Navi_DistToPoint1_U "Old Value";
BA_ "GenSigSendType" SG_ 487 Navi_DistToPoint2_I 3;
BA_ "GenSigStartValue" SG_ 487 Navi_DistToPoint2_I 4095;
BA_ "TimeoutValue" SG_ 487 Navi_DistToPoint2_I "Old Value";
BA_ "GenSigSendType" SG_ 487 Navi_DistToPoint2_F 3;
BA_ "GenSigStartValue" SG_ 487 Navi_DistToPoint2_F 15;
BA_ "TimeoutValue" SG_ 487 Navi_DistToPoint2_F "Old Value";
BA_ "GenSigSendType" SG_ 487 Navi_DistToPoint2_U 3;
BA_ "GenSigStartValue" SG_ 487 Navi_DistToPoint2_U 15;
BA_ "TimeoutValue" SG_ 487 Navi_DistToPoint2_U "Old Value";
BA_ "GenSigSendType" SG_ 487 Navi_DistToPoint3_F 3;
BA_ "GenSigStartValue" SG_ 487 Navi_DistToPoint3_F 15;
BA_ "TimeoutValue" SG_ 487 Navi_DistToPoint3_F "Old Value";
BA_ "GenSigSendType" SG_ 487 Navi_DistToPoint3_I 3;
BA_ "GenSigStartValue" SG_ 487 Navi_DistToPoint3_I 4095;
BA_ "TimeoutValue" SG_ 487 Navi_DistToPoint3_I "Old Value";
BA_ "GenSigSendType" SG_ 487 Navi_DistToPoint3_U 3;
BA_ "GenSigStartValue" SG_ 487 Navi_DistToPoint3_U 15;
BA_ "TimeoutValue" SG_ 487 Navi_DistToPoint3_U "Old Value";
BA_ "GenSigSendType" SG_ 486 Navi_DistToDest_I 3;
BA_ "GenSigStartValue" SG_ 486 Navi_DistToDest_I 65535;
BA_ "SignalCategory" SG_ 486 Navi_DistToDest_I 13;
BA_ "TimeoutValue" SG_ 486 Navi_DistToDest_I "Old Value";
BA_ "GenSigSendType" SG_ 486 Navi_DistToDest_F 3;
BA_ "GenSigStartValue" SG_ 486 Navi_DistToDest_F 15;
BA_ "SignalCategory" SG_ 486 Navi_DistToDest_F 13;
BA_ "TimeoutValue" SG_ 486 Navi_DistToDest_F "Old Value";
BA_ "GenSigSendType" SG_ 486 Navi_DistToDest_U 3;
BA_ "GenSigStartValue" SG_ 486 Navi_DistToDest_U 15;
BA_ "SignalCategory" SG_ 486 Navi_DistToDest_U 13;
BA_ "TimeoutValue" SG_ 486 Navi_DistToDest_U "Old Value";
BA_ "GenSigSendType" SG_ 486 Navi_EstimHour 3;
BA_ "GenSigStartValue" SG_ 486 Navi_EstimHour 255;
BA_ "SignalCategory" SG_ 486 Navi_EstimHour 13;
BA_ "TimeoutValue" SG_ 486 Navi_EstimHour "Old Value";
BA_ "GenSigSendType" SG_ 486 Navi_EstimMin 3;
BA_ "GenSigStartValue" SG_ 486 Navi_EstimMin 63;
BA_ "SignalCategory" SG_ 486 Navi_EstimMin 13;
BA_ "TimeoutValue" SG_ 486 Navi_EstimMin "Old Value";
BA_ "GenSigSendType" SG_ 486 Navi_EstimTimeType 3;
BA_ "GenSigStartValue" SG_ 486 Navi_EstimTimeType 3;
BA_ "SignalCategory" SG_ 486 Navi_EstimTimeType 13;
BA_ "TimeoutValue" SG_ 486 Navi_EstimTimeType "Old Value";
BA_ "GenSigSendType" SG_ 486 Navi_Compass 3;
BA_ "GenSigStartValue" SG_ 486 Navi_Compass 63;
BA_ "SignalCategory" SG_ 486 Navi_Compass 13;
BA_ "TimeoutValue" SG_ 486 Navi_Compass "Old Value";
BA_ "GenSigSendType" SG_ 229 SYS_SW_Ver_Req 4;
BA_ "GenSigStartValue" SG_ 229 SYS_SW_Ver_Req 3;
BA_ "NmNetworkRequest" SG_ 229 SYS_SW_Ver_Req 1;
BA_ "GenSigSendType" SG_ 229 SYS_CAN_Ver_Req 4;
BA_ "GenSigStartValue" SG_ 229 SYS_CAN_Ver_Req 3;
BA_ "NmNetworkRequest" SG_ 229 SYS_CAN_Ver_Req 1;
BA_ "GenSigSendType" SG_ 229 SYS_HW_Ver_Req 4;
BA_ "GenSigStartValue" SG_ 229 SYS_HW_Ver_Req 3;
BA_ "NmNetworkRequest" SG_ 229 SYS_HW_Ver_Req 1;
BA_ "GenSigSendType" SG_ 229 SYS_RBD_Req 4;
BA_ "GenSigStartValue" SG_ 229 SYS_RBD_Req 3;
BA_ "NmNetworkRequest" SG_ 229 SYS_RBD_Req 1;
BA_ "GenSigSendType" SG_ 229 SYS_MOSTErrorDiag_Req 4;
BA_ "GenSigStartValue" SG_ 229 SYS_MOSTErrorDiag_Req 3;
BA_ "NmNetworkRequest" SG_ 229 SYS_MOSTErrorDiag_Req 1;
BA_ "GenSigSendType" SG_ 229 SYS_Reset_Req 4;
BA_ "GenSigStartValue" SG_ 229 SYS_Reset_Req 3;
BA_ "NmNetworkRequest" SG_ 229 SYS_Reset_Req 1;
BA_ "GenSigSendType" SG_ 485 Navi_FixedSpdTrap 4;
BA_ "GenSigStartValue" SG_ 485 Navi_FixedSpdTrap 15;
BA_ "NmNetworkRequest" SG_ 485 Navi_FixedSpdTrap 1;
BA_ "SignalCategory" SG_ 485 Navi_FixedSpdTrap 13;
BA_ "TimeoutValue" SG_ 485 Navi_FixedSpdTrap "Old Value";
BA_ "GenSigSendType" SG_ 485 Navi_MobileSpdTrap 4;
BA_ "GenSigStartValue" SG_ 485 Navi_MobileSpdTrap 15;
BA_ "NmNetworkRequest" SG_ 485 Navi_MobileSpdTrap 1;
BA_ "SignalCategory" SG_ 485 Navi_MobileSpdTrap 13;
BA_ "TimeoutValue" SG_ 485 Navi_MobileSpdTrap "Old Value";
BA_ "GenSigSendType" SG_ 485 Navi_OverSpdAlarm 4;
BA_ "GenSigStartValue" SG_ 485 Navi_OverSpdAlarm 3;
BA_ "Gatewaysignal" SG_ 485 Navi_OverSpdAlarm 1;
BA_ "NmNetworkRequest" SG_ 485 Navi_OverSpdAlarm 1;
BA_ "SignalCategory" SG_ 485 Navi_OverSpdAlarm 13;
BA_ "TimeoutValue" SG_ 485 Navi_OverSpdAlarm "Old value";
BA_ "GenSigSendType" SG_ 485 Navi_SpdRedlightTrap 4;
BA_ "GenSigStartValue" SG_ 485 Navi_SpdRedlightTrap 15;
BA_ "NmNetworkRequest" SG_ 485 Navi_SpdRedlightTrap 1;
BA_ "SignalCategory" SG_ 485 Navi_SpdRedlightTrap 13;
BA_ "TimeoutValue" SG_ 485 Navi_SpdRedlightTrap "Old Value";
BA_ "GenSigSendType" SG_ 485 Navi_NonSpdTrap 3;
BA_ "GenSigStartValue" SG_ 485 Navi_NonSpdTrap 31;
BA_ "TimeoutValue" SG_ 485 Navi_NonSpdTrap "Old Value";
BA_ "GenSigSendType" SG_ 485 Navi_WarningZone 3;
BA_ "GenSigStartValue" SG_ 485 Navi_WarningZone 15;
BA_ "TimeoutValue" SG_ 485 Navi_WarningZone "Old Value";
BA_ "GenSigSendType" SG_ 485 Navi_MergeWarning 4;
BA_ "GenSigStartValue" SG_ 485 Navi_MergeWarning 3;
BA_ "NmNetworkRequest" SG_ 485 Navi_MergeWarning 1;
BA_ "SignalCategory" SG_ 485 Navi_MergeWarning 13;
BA_ "TimeoutValue" SG_ 485 Navi_MergeWarning "Old Value";
BA_ "GenSigSendType" SG_ 485 Navi_CurveWarning 4;
BA_ "GenSigStartValue" SG_ 485 Navi_CurveWarning 15;
BA_ "NmNetworkRequest" SG_ 485 Navi_CurveWarning 1;
BA_ "SignalCategory" SG_ 485 Navi_CurveWarning 13;
BA_ "TimeoutValue" SG_ 485 Navi_CurveWarning "Old Value";
BA_ "GenSigSendType" SG_ 485 Navi_BusSpdTrap 4;
BA_ "GenSigStartValue" SG_ 485 Navi_BusSpdTrap 15;
BA_ "NmNetworkRequest" SG_ 485 Navi_BusSpdTrap 1;
BA_ "SignalCategory" SG_ 485 Navi_BusSpdTrap 13;
BA_ "TimeoutValue" SG_ 485 Navi_BusSpdTrap "Old Value";
BA_ "GenSigSendType" SG_ 485 Navi_SpdLimit_Type 4;
BA_ "GenSigStartValue" SG_ 485 Navi_SpdLimit_Type 3;
BA_ "NmNetworkRequest" SG_ 485 Navi_SpdLimit_Type 1;
BA_ "TimeoutValue" SG_ 485 Navi_SpdLimit_Type "Old Value";
BA_ "GenSigSendType" SG_ 485 Navi_SpdLimit_Unit 4;
BA_ "GenSigStartValue" SG_ 485 Navi_SpdLimit_Unit 3;
BA_ "NmNetworkRequest" SG_ 485 Navi_SpdLimit_Unit 1;
BA_ "TimeoutValue" SG_ 485 Navi_SpdLimit_Unit "Old Value";
BA_ "GenSigSendType" SG_ 485 Navi_SpdInfo_Type 3;
BA_ "GenSigStartValue" SG_ 485 Navi_SpdInfo_Type 15;
BA_ "TimeoutValue" SG_ 485 Navi_SpdInfo_Type "Old Value";
BA_ "GenSigSendType" SG_ 485 Navi_SpdLimit 4;
BA_ "GenSigStartValue" SG_ 485 Navi_SpdLimit 255;
BA_ "NmNetworkRequest" SG_ 485 Navi_SpdLimit 1;
BA_ "TimeoutValue" SG_ 485 Navi_SpdLimit "Old Value";
BA_ "GenSigSendType" SG_ 479 CLU_Type 4;
BA_ "GenSigStartValue" SG_ 479 CLU_Type 3;
BA_ "NmNetworkRequest" SG_ 479 CLU_Type 1;
BA_ "TimeoutValue" SG_ 479 CLU_Type "0x3";
BA_ "GenSigSendType" SG_ 479 CLU_Region 4;
BA_ "GenSigStartValue" SG_ 479 CLU_Region 3;
BA_ "NmNetworkRequest" SG_ 479 CLU_Region 1;
BA_ "TimeoutValue" SG_ 479 CLU_Region "0x3";
BA_ "GenSigSendType" SG_ 479 CLU_VersionMinor 4;
BA_ "GenSigStartValue" SG_ 479 CLU_VersionMinor 3;
BA_ "NmNetworkRequest" SG_ 479 CLU_VersionMinor 1;
BA_ "TimeoutValue" SG_ 479 CLU_VersionMinor "0x3";
BA_ "GenSigSendType" SG_ 479 CLU_VersionMajor 4;
BA_ "GenSigStartValue" SG_ 479 CLU_VersionMajor 3;
BA_ "NmNetworkRequest" SG_ 479 CLU_VersionMajor 1;
BA_ "TimeoutValue" SG_ 479 CLU_VersionMajor "0x3";
BA_ "GenSigSendType" SG_ 479 CLU_CurrentDispState 4;
BA_ "GenSigStartValue" SG_ 479 CLU_CurrentDispState 3;
BA_ "NmNetworkRequest" SG_ 479 CLU_CurrentDispState 1;
BA_ "TimeoutValue" SG_ 479 CLU_CurrentDispState "0x3";
BA_ "GenSigSendType" SG_ 479 C_DRVDRSW 4;
BA_ "GenSigStartValue" SG_ 479 C_DRVDRSW 3;
BA_ "NmNetworkRequest" SG_ 479 C_DRVDRSW 1;
BA_ "NmNetworkRequestHoldingTime" SG_ 479 C_DRVDRSW 5;
BA_ "Validity" SG_ 479 C_DRVDRSW 0;
BA_ "GenSigSendType" SG_ 479 CF_Clu_LowfuelWarning 4;
BA_ "NmNetworkRequest" SG_ 479 CF_Clu_LowfuelWarning 1;
BA_ "TimeoutValue" SG_ 479 CF_Clu_LowfuelWarning "OldValue";
BA_ "GenSigSendType" SG_ 479 CLU_PowerInfo 4;
BA_ "GenSigStartValue" SG_ 479 CLU_PowerInfo 3;
BA_ "NmNetworkRequest" SG_ 479 CLU_PowerInfo 1;
BA_ "Validity" SG_ 479 CLU_PowerInfo 2;
BA_ "GenSigSendType" SG_ 479 C_DrivingModeState 4;
BA_ "GenSigStartValue" SG_ 479 C_DrivingModeState 7;
BA_ "NmNetworkRequest" SG_ 479 C_DrivingModeState 1;
BA_ "TimeoutValue" SG_ 479 C_DrivingModeState "Old Value";
BA_ "GenSigSendType" SG_ 479 Clu_RheostatLvl 4;
BA_ "GenSigStartValue" SG_ 479 Clu_RheostatLvl 31;
BA_ "NmNetworkRequest" SG_ 479 Clu_RheostatLvl 1;
BA_ "TimeoutValue" SG_ 479 Clu_RheostatLvl "Old Value";
BA_ "GenSigSendType" SG_ 479 C_Clu_ActiveEcoSW 4;
BA_ "GenSigStartValue" SG_ 479 C_Clu_ActiveEcoSW 3;
BA_ "NmNetworkRequest" SG_ 479 C_Clu_ActiveEcoSW 1;
BA_ "SignalCategory" SG_ 479 C_Clu_ActiveEcoSW 13;
BA_ "TimeoutValue" SG_ 479 C_Clu_ActiveEcoSW "Old Value";
BA_ "GenSigSendType" SG_ 479 C_Detent 4;
BA_ "GenSigStartValue" SG_ 479 C_Detent 3;
BA_ "NmNetworkRequest" SG_ 479 C_Detent 1;
BA_ "TimeoutValue" SG_ 479 C_Detent "0x0";
BA_ "GenSigSendType" SG_ 479 C_DrivingModeOn 3;
BA_ "GenSigStartValue" SG_ 479 C_DrivingModeOn 3;
BA_ "Validity" SG_ 479 C_DrivingModeOn 2;
BA_ "GenSigSendType" SG_ 474 CF_Clu_AvgFCU 3;
BA_ "Validity" SG_ 474 CF_Clu_AvgFCU 2;
BA_ "GenSigSendType" SG_ 474 CF_Clu_AvgFCL 3;
BA_ "Validity" SG_ 474 CF_Clu_AvgFCL 2;
BA_ "GenSigSendType" SG_ 474 CF_Clu_TermAvgSync 3;
BA_ "Validity" SG_ 474 CF_Clu_TermAvgSync 2;
BA_ "GenSigSendType" SG_ 474 CF_Clu_EcoDriveInf 3;
BA_ "Validity" SG_ 474 CF_Clu_EcoDriveInf 2;
BA_ "GenSigSendType" SG_ 474 CR_Clu_TermAvgFCI 3;
BA_ "Validity" SG_ 474 CR_Clu_TermAvgFCI 2;
BA_ "GenSigSendType" SG_ 474 CF_CLU_EcoScore 3;
BA_ "Validity" SG_ 474 CF_CLU_EcoScore 2;
BA_ "GenSigStartValue" SG_ 1495 Clu_TripUnit 3;
BA_ "NmNetworkRequest" SG_ 1495 Clu_TripUnit 1;
BA_ "TimeoutValue" SG_ 1495 Clu_TripUnit "Old Value";
BA_ "Validity" SG_ 1495 Clu_TripUnit 2;
BA_ "GenSigStartValue" SG_ 1495 Clu_DTEWarn 3;
BA_ "NmNetworkRequest" SG_ 1495 Clu_DTEWarn 1;
BA_ "TimeoutValue" SG_ 1495 Clu_DTEWarn "Old Value";
BA_ "Validity" SG_ 1495 Clu_DTEWarn 2;
BA_ "GenSigStartValue" SG_ 1495 Clu_DTE 4095;
BA_ "NmNetworkRequest" SG_ 1495 Clu_DTE 1;
BA_ "TimeoutValue" SG_ 1495 Clu_DTE "0xFFF";
BA_ "Validity" SG_ 1495 Clu_DTE 2;
BA_ "GenSigStartValue" SG_ 1495 Clu_AFC 1023;
BA_ "NmNetworkRequest" SG_ 1495 Clu_AFC 1;
BA_ "TimeoutValue" SG_ 1495 Clu_AFC "0x3FF";
BA_ "Validity" SG_ 1495 Clu_AFC 2;
BA_ "GenSigStartValue" SG_ 1495 Clu_IFC 1023;
BA_ "NmNetworkRequest" SG_ 1495 Clu_IFC 1;
BA_ "TimeoutValue" SG_ 1495 Clu_IFC "0x3FF";
BA_ "Validity" SG_ 1495 Clu_IFC 2;
BA_ "GenSigStartValue" SG_ 1495 Clu_Odometer 16777215;
BA_ "NmNetworkRequest" SG_ 1495 Clu_Odometer 1;
BA_ "TimeoutValue" SG_ 1495 Clu_Odometer "0xFFFFFF";
BA_ "Validity" SG_ 1495 Clu_Odometer 2;
BA_ "GenSigStartValue" SG_ 1494 CF_TripUnit 3;
BA_ "Validity" SG_ 1494 CF_TripUnit 2;
BA_ "Validity" SG_ 1494 CF_DTE 2;
BA_ "GenSigSendType" SG_ 214 AMP_SWVerMajor 4;
BA_ "GenSigStartValue" SG_ 214 AMP_SWVerMajor 255;
BA_ "NmNetworkRequest" SG_ 214 AMP_SWVerMajor 1;
BA_ "GenSigSendType" SG_ 214 AMP_SWVerMinor 4;
BA_ "GenSigStartValue" SG_ 214 AMP_SWVerMinor 255;
BA_ "NmNetworkRequest" SG_ 214 AMP_SWVerMinor 1;
BA_ "GenSigSendType" SG_ 214 AMP_CANVerMajor 4;
BA_ "GenSigStartValue" SG_ 214 AMP_CANVerMajor 255;
BA_ "NmNetworkRequest" SG_ 214 AMP_CANVerMajor 1;
BA_ "GenSigSendType" SG_ 214 AMP_CANVerMinor 4;
BA_ "GenSigStartValue" SG_ 214 AMP_CANVerMinor 255;
BA_ "NmNetworkRequest" SG_ 214 AMP_CANVerMinor 1;
BA_ "GenSigSendType" SG_ 214 AMP_RBDResult 4;
BA_ "GenSigStartValue" SG_ 214 AMP_RBDResult 7;
BA_ "NmNetworkRequest" SG_ 214 AMP_RBDResult 1;
BA_ "GenSigSendType" SG_ 214 AMP_MOSTErrorDiagResult 4;
BA_ "GenSigStartValue" SG_ 214 AMP_MOSTErrorDiagResult 7;
BA_ "NmNetworkRequest" SG_ 214 AMP_MOSTErrorDiagResult 1;
BA_ "GenSigSendType" SG_ 214 AMP_HWVerMajor 4;
BA_ "GenSigStartValue" SG_ 214 AMP_HWVerMajor 255;
BA_ "NmNetworkRequest" SG_ 214 AMP_HWVerMajor 1;
BA_ "GenSigSendType" SG_ 214 AMP_HWVerMinor 4;
BA_ "GenSigStartValue" SG_ 214 AMP_HWVerMinor 255;
BA_ "NmNetworkRequest" SG_ 214 AMP_HWVerMinor 1;
BA_ "GenSigStartValue" SG_ 1492 MM_CR_Fatc_AcnComCst_W 1022;
BA_ "Validity" SG_ 1492 MM_CR_Fatc_AcnComCst_W 2;
BA_ "GenSigStartValue" SG_ 1492 MM_CR_Ldc_PwrMon_W 255;
BA_ "Validity" SG_ 1492 MM_CR_Ldc_PwrMon_W 2;
BA_ "GenSigStartValue" SG_ 1492 MM_CR_Fatc_PTCPwrCon_W 1022;
BA_ "Validity" SG_ 1492 MM_CR_Fatc_PTCPwrCon_W 2;
BA_ "GenSigStartValue" SG_ 1492 MM_CR_BmsChgExp_T_Fast 65535;
BA_ "Validity" SG_ 1492 MM_CR_BmsChgExp_T_Fast 2;
BA_ "GenSigStartValue" SG_ 1492 MM_CR_BmsChgExp_T_Slow 65535;
BA_ "Validity" SG_ 1492 MM_CR_BmsChgExp_T_Slow 2;
BA_ "GenSigStartValue" SG_ 1491 MM_CF_Vcu_EvMod 15;
BA_ "TimeoutValue" SG_ 1491 MM_CF_Vcu_EvMod "0xF";
BA_ "Validity" SG_ 1491 MM_CF_Vcu_EvMod 2;
BA_ "GenSigStartValue" SG_ 1491 MM_CF_Vcu_GarSelDisp 13;
BA_ "TimeoutValue" SG_ 1491 MM_CF_Vcu_GarSelDisp "old";
BA_ "Validity" SG_ 1491 MM_CF_Vcu_GarSelDisp 2;
BA_ "TimeoutValue" SG_ 1491 MM_CF_Vcu_ThiBatTir "old";
BA_ "Validity" SG_ 1491 MM_CF_Vcu_ThiBatTir 2;
BA_ "GenSigStartValue" SG_ 1491 CR_Mcu_MotEstTqPc 1023;
BA_ "TimeoutValue" SG_ 1491 CR_Mcu_MotEstTqPc "0x3FF";
BA_ "Validity" SG_ 1491 CR_Mcu_MotEstTqPc 2;
BA_ "GenSigStartValue" SG_ 1491 CR_Mcu_MotActRotSpd_rpm 32768;
BA_ "TimeoutValue" SG_ 1491 CR_Mcu_MotActRotSpd_rpm "old";
BA_ "Validity" SG_ 1491 CR_Mcu_MotActRotSpd_rpm 2;
BA_ "GenSigStartValue" SG_ 1490 MM_CR_Vcu_EcoSco 15;
BA_ "TimeoutValue" SG_ 1490 MM_CR_Vcu_EcoSco "Old Value";
BA_ "Validity" SG_ 1490 MM_CR_Vcu_EcoSco 2;
BA_ "GenSigStartValue" SG_ 1490 MM_CF_Vcu_PgmRun5 3;
BA_ "Validity" SG_ 1490 MM_CF_Vcu_PgmRun5 2;
BA_ "GenSigStartValue" SG_ 1490 MM_CR_Clu_Odometer_kph 16777214;
BA_ "Validity" SG_ 1490 MM_CR_Clu_Odometer_kph 2;
BA_ "Gatewaysignal" SG_ 1489 C_InhibitR_DATC 4;
BA_ "GenSigSendType" SG_ 1489 C_InhibitR_DATC 4;
BA_ "Gatewaysignal" SG_ 1489 C_InhibitP_DATC 4;
BA_ "GenSigSendType" SG_ 1489 C_InhibitP_DATC 4;
BA_ "Gatewaysignal" SG_ 1489 C_InhibitN_DATC 4;
BA_ "GenSigSendType" SG_ 1489 C_InhibitN_DATC 4;
BA_ "Gatewaysignal" SG_ 1489 C_InhibitD_DATC 4;
BA_ "GenSigSendType" SG_ 1489 C_InhibitD_DATC 4;
BA_ "GenSigSendType" SG_ 465 CF_Clu_EVDTEDisp 3;
BA_ "GenSigStartValue" SG_ 465 CF_Clu_EVDTEDisp 511;
BA_ "Validity" SG_ 465 CF_Clu_EVDTEDisp 2;
BA_ "GenSigSendType" SG_ 465 CF_Clu_GasDTEDisp 3;
BA_ "GenSigStartValue" SG_ 465 CF_Clu_GasDTEDisp 1023;
BA_ "Validity" SG_ 465 CF_Clu_GasDTEDisp 2;
BA_ "GenSigSendType" SG_ 465 MM_CR_Clu_TotalDTEDisp 3;
BA_ "GenSigStartValue" SG_ 465 MM_CR_Clu_TotalDTEDisp 1279;
BA_ "Validity" SG_ 465 MM_CR_Clu_TotalDTEDisp 2;
BA_ "GenSigSendType" SG_ 465 CF_Clu_TripUnit 3;
BA_ "GenSigStartValue" SG_ 465 CF_Clu_TripUnit 3;
BA_ "Validity" SG_ 465 CF_Clu_TripUnit 2;
BA_ "GenSigStartValue" SG_ 1488 MM_CR_Mcu_VehSpd_Kph 255;
BA_ "Validity" SG_ 1488 MM_CR_Mcu_VehSpd_Kph 2;
BA_ "GenSigStartValue" SG_ 1488 MM_CR_Mcu_VehSpdDec_Kph 255;
BA_ "Validity" SG_ 1488 MM_CR_Mcu_VehSpdDec_Kph 2;
BA_ "GenSigStartValue" SG_ 1488 MM_CR_Bms_Soc_Pc 255;
BA_ "Validity" SG_ 1488 MM_CR_Bms_Soc_Pc 2;
BA_ "GenSigStartValue" SG_ 1488 MM_CR_Vcu_TqMotClu_Pc 255;
BA_ "Validity" SG_ 1488 MM_CR_Vcu_TqMotClu_Pc 2;
BA_ "GenSigStartValue" SG_ 1488 MM_CR_Bms_DrvEnaDist 255;
BA_ "Validity" SG_ 1488 MM_CR_Bms_DrvEnaDist 2;
BA_ "GenSigStartValue" SG_ 1488 MM_CR_Clu_Soc_Seg 31;
BA_ "TimeoutValue" SG_ 1488 MM_CR_Clu_Soc_Seg "Old Value";
BA_ "Validity" SG_ 1488 MM_CR_Clu_Soc_Seg 2;
BA_ "GenSigSendType" SG_ 208 CLU_SWVerMajor 4;
BA_ "GenSigStartValue" SG_ 208 CLU_SWVerMajor 255;
BA_ "NmNetworkRequest" SG_ 208 CLU_SWVerMajor 1;
BA_ "GenSigSendType" SG_ 208 CLU_SWVerMinor 4;
BA_ "GenSigStartValue" SG_ 208 CLU_SWVerMinor 255;
BA_ "NmNetworkRequest" SG_ 208 CLU_SWVerMinor 1;
BA_ "GenSigSendType" SG_ 208 CLU_CANVerMajor 4;
BA_ "GenSigStartValue" SG_ 208 CLU_CANVerMajor 255;
BA_ "NmNetworkRequest" SG_ 208 CLU_CANVerMajor 1;
BA_ "GenSigSendType" SG_ 208 CLU_CANVerMinor 4;
BA_ "GenSigStartValue" SG_ 208 CLU_CANVerMinor 255;
BA_ "NmNetworkRequest" SG_ 208 CLU_CANVerMinor 1;
BA_ "GenSigSendType" SG_ 208 CLU_HWVerMajor 4;
BA_ "GenSigStartValue" SG_ 208 CLU_HWVerMajor 255;
BA_ "NmNetworkRequest" SG_ 208 CLU_HWVerMajor 1;
BA_ "GenSigSendType" SG_ 208 CLU_HWVerMinor 4;
BA_ "GenSigStartValue" SG_ 208 CLU_HWVerMinor 255;
BA_ "NmNetworkRequest" SG_ 208 CLU_HWVerMinor 1;
BA_ "GenSigSendType" SG_ 448 DATC_AqsLevelChg 4;
BA_ "GenSigStartValue" SG_ 448 DATC_AqsLevelChg 15;
BA_ "NmNetworkRequest" SG_ 448 DATC_AqsLevelChg 1;
BA_ "TimeoutValue" SG_ 448 DATC_AqsLevelChg "Old";
BA_ "Validity" SG_ 448 DATC_AqsLevelChg 2;
BA_ "GenSigSendType" SG_ 448 RSELockOnOff 4;
BA_ "GenSigStartValue" SG_ 448 RSELockOnOff 3;
BA_ "NmNetworkRequest" SG_ 448 RSELockOnOff 1;
BA_ "TimeoutValue" SG_ 448 RSELockOnOff "Old";
BA_ "Validity" SG_ 448 RSELockOnOff 2;
BA_ "GenSigSendType" SG_ 448 DATC_AqsMode 4;
BA_ "GenSigStartValue" SG_ 448 DATC_AqsMode 3;
BA_ "NmNetworkRequest" SG_ 448 DATC_AqsMode 1;
BA_ "TimeoutValue" SG_ 448 DATC_AqsMode "Old";
BA_ "Validity" SG_ 448 DATC_AqsMode 2;
BA_ "GenSigSendType" SG_ 448 HU_Graphreset_Info 3;
BA_ "GenSigStartValue" SG_ 448 HU_Graphreset_Info 3;
BA_ "SignalCategory" SG_ 448 HU_Graphreset_Info 13;
BA_ "TimeoutValue" SG_ 448 HU_Graphreset_Info "Old Value";
BA_ "GenSigSendType" SG_ 448 HU_VRActivity 4;
BA_ "GenSigStartValue" SG_ 448 HU_VRActivity 3;
BA_ "Gatewaysignal" SG_ 448 HU_VRActivity 3;
BA_ "NmNetworkRequest" SG_ 448 HU_VRActivity 1;
BA_ "SignalCategory" SG_ 448 HU_VRActivity 13;
BA_ "TimeoutValue" SG_ 448 HU_VRActivity "Old Value";
BA_ "GenSigSendType" SG_ 448 HU_PhoneActivity 4;
BA_ "GenSigStartValue" SG_ 448 HU_PhoneActivity 3;
BA_ "Gatewaysignal" SG_ 448 HU_PhoneActivity 3;
BA_ "NmNetworkRequest" SG_ 448 HU_PhoneActivity 1;
BA_ "SignalCategory" SG_ 448 HU_PhoneActivity 13;
BA_ "TimeoutValue" SG_ 448 HU_PhoneActivity "Old Value";
BA_ "GenSigSendType" SG_ 448 BlowerNoiseControl 4;
BA_ "GenSigStartValue" SG_ 448 BlowerNoiseControl 3;
BA_ "Gatewaysignal" SG_ 448 BlowerNoiseControl 3;
BA_ "NmNetworkRequest" SG_ 448 BlowerNoiseControl 1;
BA_ "TimeoutValue" SG_ 448 BlowerNoiseControl "Invalid";
BA_ "GenSigSendType" SG_ 432 C_DATCOnOffReq 4;
BA_ "GenSigStartValue" SG_ 432 C_DATCOnOffReq 3;
BA_ "NmNetworkRequest" SG_ 432 C_DATCOnOffReq 1;
BA_ "TimeoutValue" SG_ 432 C_DATCOnOffReq "Old Value";
BA_ "GenSigSendType" SG_ 432 C_DATCTempUnit 4;
BA_ "GenSigStartValue" SG_ 432 C_DATCTempUnit 3;
BA_ "NmNetworkRequest" SG_ 432 C_DATCTempUnit 1;
BA_ "TimeoutValue" SG_ 432 C_DATCTempUnit "Old Value";
BA_ "GenSigSendType" SG_ 432 C_DATCTempSet 4;
BA_ "GenSigStartValue" SG_ 432 C_DATCTempSet 255;
BA_ "NmNetworkRequest" SG_ 432 C_DATCTempSet 1;
BA_ "TimeoutValue" SG_ 432 C_DATCTempSet "Old Value";
BA_ "GenSigSendType" SG_ 432 TMU_IVRActivity 4;
BA_ "GenSigStartValue" SG_ 432 TMU_IVRActivity 3;
BA_ "Gatewaysignal" SG_ 432 TMU_IVRActivity 3;
BA_ "NmNetworkRequest" SG_ 432 TMU_IVRActivity 1;
BA_ "SignalCategory" SG_ 432 TMU_IVRActivity 13;
BA_ "TimeoutValue" SG_ 432 TMU_IVRActivity "Old Value";
BA_ "GenSigSendType" SG_ 432 TMU_PhoneActivity 4;
BA_ "GenSigStartValue" SG_ 432 TMU_PhoneActivity 3;
BA_ "Gatewaysignal" SG_ 432 TMU_PhoneActivity 3;
BA_ "NmNetworkRequest" SG_ 432 TMU_PhoneActivity 1;
BA_ "SignalCategory" SG_ 432 TMU_PhoneActivity 13;
BA_ "TimeoutValue" SG_ 432 TMU_PhoneActivity "Old Value";
BA_ "GenSigSendType" SG_ 410 VCDC_SelDiscNo 4;
BA_ "GenSigStartValue" SG_ 410 VCDC_SelDiscNo 15;
BA_ "NmNetworkRequest" SG_ 410 VCDC_SelDiscNo 1;
BA_ "TimeoutValue" SG_ 410 VCDC_SelDiscNo "Old";
BA_ "GenSigSendType" SG_ 410 VCDC_TrackChapterNo 4;
BA_ "GenSigStartValue" SG_ 410 VCDC_TrackChapterNo 1023;
BA_ "NmNetworkRequest" SG_ 410 VCDC_TrackChapterNo 1;
BA_ "TimeoutValue" SG_ 410 VCDC_TrackChapterNo "Old";
BA_ "GenSigSendType" SG_ 410 VCDC_PlayTime 4;
BA_ "GenSigStartValue" SG_ 410 VCDC_PlayTime 16777215;
BA_ "NmNetworkRequest" SG_ 410 VCDC_PlayTime 1;
BA_ "TimeoutValue" SG_ 410 VCDC_PlayTime "Old";
BA_ "GenSigSendType" SG_ 410 MLT_PlayTime 4;
BA_ "GenSigStartValue" SG_ 410 MLT_PlayTime 16777215;
BA_ "NmNetworkRequest" SG_ 410 MLT_PlayTime 1;
BA_ "TimeoutValue" SG_ 410 MLT_PlayTime "Old";
BA_ "GenSigSendType" SG_ 407 HU_LanguageInfo 4;
BA_ "GenSigStartValue" SG_ 407 HU_LanguageInfo 255;
BA_ "NmNetworkRequest" SG_ 407 HU_LanguageInfo 1;
BA_ "TimeoutValue" SG_ 407 HU_LanguageInfo "Old Value";
BA_ "GenSigSendType" SG_ 407 HU_MuteStatus 4;
BA_ "GenSigStartValue" SG_ 407 HU_MuteStatus 3;
BA_ "NmNetworkRequest" SG_ 407 HU_MuteStatus 1;
BA_ "TimeoutValue" SG_ 407 HU_MuteStatus "Old Value";
BA_ "GenSigSendType" SG_ 407 HU_VolumeStatus 4;
BA_ "GenSigStartValue" SG_ 407 HU_VolumeStatus 63;
BA_ "NmNetworkRequest" SG_ 407 HU_VolumeStatus 1;
BA_ "TimeoutValue" SG_ 407 HU_VolumeStatus "Old Value";
BA_ "GenSigSendType" SG_ 407 HU_NaviDisp 4;
BA_ "GenSigStartValue" SG_ 407 HU_NaviDisp 3;
BA_ "NmNetworkRequest" SG_ 407 HU_NaviDisp 1;
BA_ "TimeoutValue" SG_ 407 HU_NaviDisp "Old Value";
BA_ "GenSigSendType" SG_ 407 HU_NaviStatus 4;
BA_ "GenSigStartValue" SG_ 407 HU_NaviStatus 3;
BA_ "Gatewaysignal" SG_ 407 HU_NaviStatus 5;
BA_ "NmNetworkRequest" SG_ 407 HU_NaviStatus 1;
BA_ "TimeoutValue" SG_ 407 HU_NaviStatus "Old Value";
BA_ "GenSigSendType" SG_ 407 HU_DistanceUnit 4;
BA_ "GenSigStartValue" SG_ 407 HU_DistanceUnit 3;
BA_ "NmNetworkRequest" SG_ 407 HU_DistanceUnit 1;
BA_ "TimeoutValue" SG_ 407 HU_DistanceUnit "Old value";
BA_ "GenSigSendType" SG_ 407 HU_Navigation_On_Off 4;
BA_ "GenSigStartValue" SG_ 407 HU_Navigation_On_Off 3;
BA_ "NmNetworkRequest" SG_ 407 HU_Navigation_On_Off 1;
BA_ "TimeoutValue" SG_ 407 HU_Navigation_On_Off "Old Value";
BA_ "GenSigSendType" SG_ 406 C_SDARS_ChannelNo 4;
BA_ "GenSigStartValue" SG_ 406 C_SDARS_ChannelNo 255;
BA_ "NmNetworkRequest" SG_ 406 C_SDARS_ChannelNo 1;
BA_ "GenSigSendType" SG_ 406 C_NaviRouteGuidance 4;
BA_ "GenSigStartValue" SG_ 406 C_NaviRouteGuidance 3;
BA_ "NmNetworkRequest" SG_ 406 C_NaviRouteGuidance 1;
BA_ "GenSigSendType" SG_ 406 HD_SPS_ChannelNo 4;
BA_ "GenSigStartValue" SG_ 406 HD_SPS_ChannelNo 15;
BA_ "NmNetworkRequest" SG_ 406 HD_SPS_ChannelNo 1;
BA_ "GenSigSendType" SG_ 406 C_SDARS_PresetNo 4;
BA_ "GenSigStartValue" SG_ 406 C_SDARS_PresetNo 15;
BA_ "NmNetworkRequest" SG_ 406 C_SDARS_PresetNo 1;
BA_ "GenSigSendType" SG_ 406 DAB_ServiceFollowing 3;
BA_ "GenSigStartValue" SG_ 406 DAB_ServiceFollowing 3;
BA_ "GenSigSendType" SG_ 406 SXM_ChannelNo 4;
BA_ "GenSigStartValue" SG_ 406 SXM_ChannelNo 1023;
BA_ "NmNetworkRequest" SG_ 406 SXM_ChannelNo 1;
BA_ "TimeoutValue" SG_ 406 SXM_ChannelNo "Old Value";
BA_ "GenSigSendType" SG_ 405 HU_IntegPresetNum 3;
BA_ "GenSigStartValue" SG_ 405 HU_IntegPresetNum 255;
BA_ "TimeoutValue" SG_ 405 HU_IntegPresetNum "Old value";
BA_ "GenSigSendType" SG_ 405 Radio_Area 4;
BA_ "GenSigStartValue" SG_ 405 Radio_Area 7;
BA_ "NmNetworkRequest" SG_ 405 Radio_Area 1;
BA_ "GenSigSendType" SG_ 405 DMB_PresetNo 4;
BA_ "GenSigStartValue" SG_ 405 DMB_PresetNo 31;
BA_ "NmNetworkRequest" SG_ 405 DMB_PresetNo 1;
BA_ "GenSigSendType" SG_ 405 RADIO_PresetNo 4;
BA_ "GenSigStartValue" SG_ 405 RADIO_PresetNo 31;
BA_ "NmNetworkRequest" SG_ 405 RADIO_PresetNo 1;
BA_ "GenSigSendType" SG_ 405 HU_Opstate_DIS2 3;
BA_ "GenSigStartValue" SG_ 405 HU_Opstate_DIS2 127;
BA_ "TimeoutValue" SG_ 405 HU_Opstate_DIS2 "Old Value";
BA_REL_ "GenSigTimeoutTime" BU_SG_REL_ AMP SG_ 2046 Byte0_TCP_7FE 0;
BA_REL_ "GenSigTimeoutTime" BU_SG_REL_ AMP SG_ 2046 Byte1_Data_7FE 0;
BA_REL_ "GenSigTimeoutTime" BU_SG_REL_ AMP SG_ 2046 Byte2_Data_7FE 0;
BA_REL_ "GenSigTimeoutTime" BU_SG_REL_ AMP SG_ 2046 Byte3_Data_7FE 0;
BA_REL_ "GenSigTimeoutTime" BU_SG_REL_ AMP SG_ 2046 Byte4_Data_7FE 0;
BA_REL_ "GenSigTimeoutTime" BU_SG_REL_ AMP SG_ 2046 Byte5_Data_7FE 0;
BA_REL_ "GenSigTimeoutTime" BU_SG_REL_ AMP SG_ 2046 Byte6_Data_7FE 0;
BA_REL_ "GenSigTimeoutTime" BU_SG_REL_ AMP SG_ 2046 Byte7_Data_7FE 0;
BA_REL_ "GenSigTimeoutTime" BU_SG_REL_ CUBIS SG_ 251 HU_GPS_Year 0;
BA_REL_ "GenSigTimeoutTime" BU_SG_REL_ TMU SG_ 251 HU_GPS_Year 0;
BA_REL_ "GenSigTimeoutTime" BU_SG_REL_ CUBIS SG_ 251 HU_GPS_Month 0;
BA_REL_ "GenSigTimeoutTime" BU_SG_REL_ TMU SG_ 251 HU_GPS_Month 0;
BA_REL_ "GenSigTimeoutTime" BU_SG_REL_ CUBIS SG_ 251 HU_GPS_Day 0;
BA_REL_ "GenSigTimeoutTime" BU_SG_REL_ TMU SG_ 251 HU_GPS_Day 0;
BA_REL_ "GenSigTimeoutTime" BU_SG_REL_ CUBIS SG_ 251 HU_GPS_Hour 0;
BA_REL_ "GenSigTimeoutTime" BU_SG_REL_ TMU SG_ 251 HU_GPS_Hour 0;
BA_REL_ "GenSigTimeoutTime" BU_SG_REL_ CUBIS SG_ 251 HU_GPS_Minute 0;
BA_REL_ "GenSigTimeoutTime" BU_SG_REL_ TMU SG_ 251 HU_GPS_Minute 0;
BA_REL_ "GenSigTimeoutTime" BU_SG_REL_ CUBIS SG_ 251 HU_GPS_Second 0;
BA_REL_ "GenSigTimeoutTime" BU_SG_REL_ TMU SG_ 251 HU_GPS_Second 0;
BA_REL_ "GenSigTimeoutTime" BU_SG_REL_ TMU SG_ 250 HU_VoiceRecCom 0;
BA_REL_ "GenSigTimeoutTime" BU_SG_REL_ TMU SG_ 250 HU_LangChgCom 0;
BA_REL_ "GenSigTimeoutTime" BU_SG_REL_ TMU SG_ 250 HU_CallEndCmd 0;
BA_REL_ "GenSigTimeoutTime" BU_SG_REL_ TMU SG_ 250 HU_ServiceReqtID 0;
BA_REL_ "GenSigTimeoutTime" BU_SG_REL_ TMU SG_ 250 HU_MicReqCmd 0;
BA_REL_ "GenSigTimeoutTime" BU_SG_REL_ TMU SG_ 250 HU_SeviceAction 0;
BA_REL_ "GenSigTimeoutTime" BU_SG_REL_ TMU SG_ 250 HU_eCallStatus 0;
BA_REL_ "GenSigTimeoutTime" BU_SG_REL_ H_U SG_ 1269 Byte0_TCP_4F5 0;
BA_REL_ "GenSigTimeoutTime" BU_SG_REL_ H_U SG_ 1269 Byte1_Data_4F5 0;
BA_REL_ "GenSigTimeoutTime" BU_SG_REL_ H_U SG_ 1269 Byte2_Data_4F5 0;
BA_REL_ "GenSigTimeoutTime" BU_SG_REL_ H_U SG_ 1269 Byte3_Data_4F5 0;
BA_REL_ "GenSigTimeoutTime" BU_SG_REL_ H_U SG_ 1269 Byte4_Data_4F5 0;
BA_REL_ "GenSigTimeoutTime" BU_SG_REL_ H_U SG_ 1269 Byte5_Data_4F5 0;
BA_REL_ "GenSigTimeoutTime" BU_SG_REL_ H_U SG_ 1269 Byte6_Data_4F5 0;
BA_REL_ "GenSigTimeoutTime" BU_SG_REL_ H_U SG_ 1269 Byte7_Data_4F5 0;
BA_REL_ "GenSigTimeoutTime" BU_SG_REL_ CLU SG_ 1268 Byte0_TCP_4F4 0;
BA_REL_ "GenSigTimeoutTime" BU_SG_REL_ CLU SG_ 1268 Byte1_Data_4F4 0;
BA_REL_ "GenSigTimeoutTime" BU_SG_REL_ CLU SG_ 1268 Byte2_Data_4F4 0;
BA_REL_ "GenSigTimeoutTime" BU_SG_REL_ CLU SG_ 1268 Byte3_Data_4F4 0;
BA_REL_ "GenSigTimeoutTime" BU_SG_REL_ CLU SG_ 1268 Byte4_Data_4F4 0;
BA_REL_ "GenSigTimeoutTime" BU_SG_REL_ CLU SG_ 1268 Byte5_Data_4F4 0;
BA_REL_ "GenSigTimeoutTime" BU_SG_REL_ CLU SG_ 1268 Byte6_Data_4F4 0;
BA_REL_ "GenSigTimeoutTime" BU_SG_REL_ CLU SG_ 1268 Byte7_Data_4F4 0;
BA_REL_ "GenSigTimeoutTime" BU_SG_REL_ H_U SG_ 1267 Byte0_TCP_4F3 0;
BA_REL_ "GenSigTimeoutTime" BU_SG_REL_ H_U SG_ 1267 Byte1_Data_4F3 0;
BA_REL_ "GenSigTimeoutTime" BU_SG_REL_ H_U SG_ 1267 Byte2_Data_4F3 0;
BA_REL_ "GenSigTimeoutTime" BU_SG_REL_ H_U SG_ 1267 Byte3_Data_4F3 0;
BA_REL_ "GenSigTimeoutTime" BU_SG_REL_ H_U SG_ 1267 Byte4_Data_4F3 0;
BA_REL_ "GenSigTimeoutTime" BU_SG_REL_ H_U SG_ 1267 Byte5_Data_4F3 0;
BA_REL_ "GenSigTimeoutTime" BU_SG_REL_ H_U SG_ 1267 Byte6_Data_4F3 0;
BA_REL_ "GenSigTimeoutTime" BU_SG_REL_ H_U SG_ 1267 Byte7_Data_4F3 0;
BA_REL_ "GenSigTimeoutTime" BU_SG_REL_ CLU SG_ 1266 Byte0_TCP_4F2 0;
BA_REL_ "GenSigTimeoutTime" BU_SG_REL_ CLU SG_ 1266 Byte1_Data_4F2 0;
BA_REL_ "GenSigTimeoutTime" BU_SG_REL_ CLU SG_ 1266 Byte2_Data_4F2 0;
BA_REL_ "GenSigTimeoutTime" BU_SG_REL_ CLU SG_ 1266 Byte3_Data_4F2 0;
BA_REL_ "GenSigTimeoutTime" BU_SG_REL_ CLU SG_ 1266 Byte4_Data_4F2 0;
BA_REL_ "GenSigTimeoutTime" BU_SG_REL_ CLU SG_ 1266 Byte5_Data_4F2 0;
BA_REL_ "GenSigTimeoutTime" BU_SG_REL_ CLU SG_ 1266 Byte6_Data_4F2 0;
BA_REL_ "GenSigTimeoutTime" BU_SG_REL_ CLU SG_ 1266 Byte7_Data_4F2 0;
BA_REL_ "GenSigTimeoutTime" BU_SG_REL_ H_U SG_ 1263 Byte0_TCP_4EF 0;
BA_REL_ "GenSigTimeoutTime" BU_SG_REL_ H_U SG_ 1263 Byte1_Data_4EF 0;
BA_REL_ "GenSigTimeoutTime" BU_SG_REL_ H_U SG_ 1263 Byte2_Data_4EF 0;
BA_REL_ "GenSigTimeoutTime" BU_SG_REL_ H_U SG_ 1263 Byte3_Data_4EF 0;
BA_REL_ "GenSigTimeoutTime" BU_SG_REL_ H_U SG_ 1263 Byte4_Data_4EF 0;
BA_REL_ "GenSigTimeoutTime" BU_SG_REL_ H_U SG_ 1263 Byte5_Data_4EF 0;
BA_REL_ "GenSigTimeoutTime" BU_SG_REL_ H_U SG_ 1263 Byte6_Data_4EF 0;
BA_REL_ "GenSigTimeoutTime" BU_SG_REL_ H_U SG_ 1263 Byte7_Data_4EF 0;
BA_REL_ "GenSigTimeoutTime" BU_SG_REL_ CLU SG_ 1262 Byte0_TCP_4EE 0;
BA_REL_ "GenSigTimeoutTime" BU_SG_REL_ CLU SG_ 1262 Byte1_Data_4EE 0;
BA_REL_ "GenSigTimeoutTime" BU_SG_REL_ CLU SG_ 1262 Byte2_Data_4EE 0;
BA_REL_ "GenSigTimeoutTime" BU_SG_REL_ CLU SG_ 1262 Byte3_Data_4EE 0;
BA_REL_ "GenSigTimeoutTime" BU_SG_REL_ CLU SG_ 1262 Byte4_Data_4EE 0;
BA_REL_ "GenSigTimeoutTime" BU_SG_REL_ CLU SG_ 1262 Byte5_Data_4EE 0;
BA_REL_ "GenSigTimeoutTime" BU_SG_REL_ CLU SG_ 1262 Byte6_Data_4EE 0;
BA_REL_ "GenSigTimeoutTime" BU_SG_REL_ CLU SG_ 1262 Byte7_Data_4EE 0;
BA_REL_ "GenSigTimeoutTime" BU_SG_REL_ H_U SG_ 1261 Byte0_TCP_4ED 0;
BA_REL_ "GenSigTimeoutTime" BU_SG_REL_ H_U SG_ 1261 Byte1_Data_4ED 0;
BA_REL_ "GenSigTimeoutTime" BU_SG_REL_ H_U SG_ 1261 Byte2_Data_4ED 0;
BA_REL_ "GenSigTimeoutTime" BU_SG_REL_ H_U SG_ 1261 Byte3_Data_4ED 0;
BA_REL_ "GenSigTimeoutTime" BU_SG_REL_ H_U SG_ 1261 Byte4_Data_4ED 0;
BA_REL_ "GenSigTimeoutTime" BU_SG_REL_ H_U SG_ 1261 Byte5_Data_4ED 0;
BA_REL_ "GenSigTimeoutTime" BU_SG_REL_ H_U SG_ 1261 Byte6_Data_4ED 0;
BA_REL_ "GenSigTimeoutTime" BU_SG_REL_ H_U SG_ 1261 Byte7_Data_4ED 0;
BA_REL_ "GenSigTimeoutTime" BU_SG_REL_ CLU SG_ 1260 Byte0_TCP_4EC 0;
BA_REL_ "GenSigTimeoutTime" BU_SG_REL_ CLU SG_ 1260 Byte1_Data_4EC 0;
BA_REL_ "GenSigTimeoutTime" BU_SG_REL_ CLU SG_ 1260 Byte2_Data_4EC 0;
BA_REL_ "GenSigTimeoutTime" BU_SG_REL_ CLU SG_ 1260 Byte3_Data_4EC 0;
BA_REL_ "GenSigTimeoutTime" BU_SG_REL_ CLU SG_ 1260 Byte4_Data_4EC 0;
BA_REL_ "GenSigTimeoutTime" BU_SG_REL_ CLU SG_ 1260 Byte5_Data_4EC 0;
BA_REL_ "GenSigTimeoutTime" BU_SG_REL_ CLU SG_ 1260 Byte6_Data_4EC 0;
BA_REL_ "GenSigTimeoutTime" BU_SG_REL_ CLU SG_ 1260 Byte7_Data_4EC 0;
BA_REL_ "GenSigTimeoutTime" BU_SG_REL_ H_U SG_ 1259 Byte0_TCP_4EB 0;
BA_REL_ "GenSigTimeoutTime" BU_SG_REL_ H_U SG_ 1259 Byte1_Data_4EB 0;
BA_REL_ "GenSigTimeoutTime" BU_SG_REL_ H_U SG_ 1259 Byte2_Data_4EB 0;
BA_REL_ "GenSigTimeoutTime" BU_SG_REL_ H_U SG_ 1259 Byte3_Data_4EB 0;
BA_REL_ "GenSigTimeoutTime" BU_SG_REL_ H_U SG_ 1259 Byte4_Data_4EB 0;
BA_REL_ "GenSigTimeoutTime" BU_SG_REL_ H_U SG_ 1259 Byte5_Data_4EB 0;
BA_REL_ "GenSigTimeoutTime" BU_SG_REL_ H_U SG_ 1259 Byte6_Data_4EB 0;
BA_REL_ "GenSigTimeoutTime" BU_SG_REL_ H_U SG_ 1259 Byte7_Data_4EB 0;
BA_REL_ "GenSigTimeoutTime" BU_SG_REL_ CLU SG_ 1258 Byte0_TCP_4EA 0;
BA_REL_ "GenSigTimeoutTime" BU_SG_REL_ CLU SG_ 1258 Byte1_Data_4EA 0;
BA_REL_ "GenSigTimeoutTime" BU_SG_REL_ CLU SG_ 1258 Byte2_Data_4EA 0;
BA_REL_ "GenSigTimeoutTime" BU_SG_REL_ CLU SG_ 1258 Byte3_Data_4EA 0;
BA_REL_ "GenSigTimeoutTime" BU_SG_REL_ CLU SG_ 1258 Byte4_Data_4EA 0;
BA_REL_ "GenSigTimeoutTime" BU_SG_REL_ CLU SG_ 1258 Byte5_Data_4EA 0;
BA_REL_ "GenSigTimeoutTime" BU_SG_REL_ CLU SG_ 1258 Byte6_Data_4EA 0;
BA_REL_ "GenSigTimeoutTime" BU_SG_REL_ CLU SG_ 1258 Byte7_Data_4EA 0;
BA_REL_ "GenSigTimeoutTime" BU_SG_REL_ H_U SG_ 1257 Byte0_TCP_4E9 0;
BA_REL_ "GenSigTimeoutTime" BU_SG_REL_ H_U SG_ 1257 Byte1_Data_4E9 0;
BA_REL_ "GenSigTimeoutTime" BU_SG_REL_ H_U SG_ 1257 Byte2_Data_4E9 0;
BA_REL_ "GenSigTimeoutTime" BU_SG_REL_ H_U SG_ 1257 Byte3_Data_4E9 0;
BA_REL_ "GenSigTimeoutTime" BU_SG_REL_ H_U SG_ 1257 Byte4_Data_4E9 0;
BA_REL_ "GenSigTimeoutTime" BU_SG_REL_ H_U SG_ 1257 Byte5_Data_4E9 0;
BA_REL_ "GenSigTimeoutTime" BU_SG_REL_ H_U SG_ 1257 Byte6_Data_4E9 0;
BA_REL_ "GenSigTimeoutTime" BU_SG_REL_ H_U SG_ 1257 Byte7_Data_4E9 0;
BA_REL_ "GenSigTimeoutTime" BU_SG_REL_ CLU SG_ 1256 Byte0_TCP_4E8 0;
BA_REL_ "GenSigTimeoutTime" BU_SG_REL_ CLU SG_ 1256 Byte1_Data_4E8 0;
BA_REL_ "GenSigTimeoutTime" BU_SG_REL_ CLU SG_ 1256 Byte2_Data_4E8 0;
BA_REL_ "GenSigTimeoutTime" BU_SG_REL_ CLU SG_ 1256 Byte3_Data_4E8 0;
BA_REL_ "GenSigTimeoutTime" BU_SG_REL_ CLU SG_ 1256 Byte4_Data_4E8 0;
BA_REL_ "GenSigTimeoutTime" BU_SG_REL_ CLU SG_ 1256 Byte5_Data_4E8 0;
BA_REL_ "GenSigTimeoutTime" BU_SG_REL_ CLU SG_ 1256 Byte6_Data_4E8 0;
BA_REL_ "GenSigTimeoutTime" BU_SG_REL_ CLU SG_ 1256 Byte7_Data_4E8 0;
BA_REL_ "GenSigTimeoutTime" BU_SG_REL_ H_U SG_ 1255 Byte0_TCP_4E7 0;
BA_REL_ "GenSigTimeoutTime" BU_SG_REL_ H_U SG_ 1255 Byte1_Data_4E7 0;
BA_REL_ "GenSigTimeoutTime" BU_SG_REL_ H_U SG_ 1255 Byte2_Data_4E7 0;
BA_REL_ "GenSigTimeoutTime" BU_SG_REL_ H_U SG_ 1255 Byte3_Data_4E7 0;
BA_REL_ "GenSigTimeoutTime" BU_SG_REL_ H_U SG_ 1255 Byte4_Data_4E7 0;
BA_REL_ "GenSigTimeoutTime" BU_SG_REL_ H_U SG_ 1255 Byte5_Data_4E7 0;
BA_REL_ "GenSigTimeoutTime" BU_SG_REL_ H_U SG_ 1255 Byte6_Data_4E7 0;
BA_REL_ "GenSigTimeoutTime" BU_SG_REL_ H_U SG_ 1255 Byte7_Data_4E7 0;
BA_REL_ "GenSigTimeoutTime" BU_SG_REL_ CLU SG_ 1254 Byte0_TCP_4E6 0;
BA_REL_ "GenSigTimeoutTime" BU_SG_REL_ CLU SG_ 1254 Byte1_Data_4E6 0;
BA_REL_ "GenSigTimeoutTime" BU_SG_REL_ CLU SG_ 1254 Byte2_Data_4E6 0;
BA_REL_ "GenSigTimeoutTime" BU_SG_REL_ CLU SG_ 1254 Byte3_Data_4E6 0;
BA_REL_ "GenSigTimeoutTime" BU_SG_REL_ CLU SG_ 1254 Byte4_Data_4E6 0;
BA_REL_ "GenSigTimeoutTime" BU_SG_REL_ CLU SG_ 1254 Byte5_Data_4E6 0;
BA_REL_ "GenSigTimeoutTime" BU_SG_REL_ CLU SG_ 1254 Byte6_Data_4E6 0;
BA_REL_ "GenSigTimeoutTime" BU_SG_REL_ CLU SG_ 1254 Byte7_Data_4E6 0;
BA_REL_ "GenSigTimeoutTime" BU_SG_REL_ AMP SG_ 229 SYS_SW_Ver_Req 0;
BA_REL_ "GenSigTimeoutTime" BU_SG_REL_ CCP SG_ 229 SYS_SW_Ver_Req 0;
BA_REL_ "GenSigTimeoutTime" BU_SG_REL_ CGW SG_ 229 SYS_SW_Ver_Req 0;
BA_REL_ "GenSigTimeoutTime" BU_SG_REL_ CLOCK SG_ 229 SYS_SW_Ver_Req 0;
BA_REL_ "GenSigTimeoutTime" BU_SG_REL_ CLU SG_ 229 SYS_SW_Ver_Req 0;
BA_REL_ "GenSigTimeoutTime" BU_SG_REL_ HUD SG_ 229 SYS_SW_Ver_Req 0;
BA_REL_ "GenSigTimeoutTime" BU_SG_REL_ IBOX SG_ 229 SYS_SW_Ver_Req 0;
BA_REL_ "GenSigTimeoutTime" BU_SG_REL_ RRC SG_ 229 SYS_SW_Ver_Req 0;
BA_REL_ "GenSigTimeoutTime" BU_SG_REL_ RSE_L SG_ 229 SYS_SW_Ver_Req 0;
BA_REL_ "GenSigTimeoutTime" BU_SG_REL_ AMP SG_ 229 SYS_CAN_Ver_Req 0;
BA_REL_ "GenSigTimeoutTime" BU_SG_REL_ CCP SG_ 229 SYS_CAN_Ver_Req 0;
BA_REL_ "GenSigTimeoutTime" BU_SG_REL_ CGW SG_ 229 SYS_CAN_Ver_Req 0;
BA_REL_ "GenSigTimeoutTime" BU_SG_REL_ CLOCK SG_ 229 SYS_CAN_Ver_Req 0;
BA_REL_ "GenSigTimeoutTime" BU_SG_REL_ CLU SG_ 229 SYS_CAN_Ver_Req 0;
BA_REL_ "GenSigTimeoutTime" BU_SG_REL_ HUD SG_ 229 SYS_CAN_Ver_Req 0;
BA_REL_ "GenSigTimeoutTime" BU_SG_REL_ IBOX SG_ 229 SYS_CAN_Ver_Req 0;
BA_REL_ "GenSigTimeoutTime" BU_SG_REL_ RRC SG_ 229 SYS_CAN_Ver_Req 0;
BA_REL_ "GenSigTimeoutTime" BU_SG_REL_ RSE_L SG_ 229 SYS_CAN_Ver_Req 0;
BA_REL_ "GenSigTimeoutTime" BU_SG_REL_ AMP SG_ 229 SYS_HW_Ver_Req 0;
BA_REL_ "GenSigTimeoutTime" BU_SG_REL_ CCP SG_ 229 SYS_HW_Ver_Req 0;
BA_REL_ "GenSigTimeoutTime" BU_SG_REL_ CGW SG_ 229 SYS_HW_Ver_Req 0;
BA_REL_ "GenSigTimeoutTime" BU_SG_REL_ CLOCK SG_ 229 SYS_HW_Ver_Req 0;
BA_REL_ "GenSigTimeoutTime" BU_SG_REL_ CLU SG_ 229 SYS_HW_Ver_Req 0;
BA_REL_ "GenSigTimeoutTime" BU_SG_REL_ IBOX SG_ 229 SYS_HW_Ver_Req 0;
BA_REL_ "GenSigTimeoutTime" BU_SG_REL_ RRC SG_ 229 SYS_HW_Ver_Req 0;
BA_REL_ "GenSigTimeoutTime" BU_SG_REL_ AMP SG_ 229 SYS_RBD_Req 0;
BA_REL_ "GenSigTimeoutTime" BU_SG_REL_ IBOX SG_ 229 SYS_RBD_Req 0;
BA_REL_ "GenSigTimeoutTime" BU_SG_REL_ AMP SG_ 229 SYS_MOSTErrorDiag_Req 0;
BA_REL_ "GenSigTimeoutTime" BU_SG_REL_ IBOX SG_ 229 SYS_MOSTErrorDiag_Req 0;
BA_REL_ "GenSigTimeoutTime" BU_SG_REL_ AMP SG_ 229 SYS_Reset_Req 0;
BA_REL_ "GenSigTimeoutTime" BU_SG_REL_ IBOX SG_ 229 SYS_Reset_Req 0;
BA_REL_ "GenSigTimeoutTime" BU_SG_REL_ H_U SG_ 1253 Byte0_TCP_4E5 0;
BA_REL_ "GenSigTimeoutTime" BU_SG_REL_ H_U SG_ 1253 Byte1_Data_4E5 0;
BA_REL_ "GenSigTimeoutTime" BU_SG_REL_ H_U SG_ 1253 Byte2_Data_4E5 0;
BA_REL_ "GenSigTimeoutTime" BU_SG_REL_ H_U SG_ 1253 Byte3_Data_4E5 0;
BA_REL_ "GenSigTimeoutTime" BU_SG_REL_ H_U SG_ 1253 Byte4_Data_4E5 0;
BA_REL_ "GenSigTimeoutTime" BU_SG_REL_ H_U SG_ 1253 Byte5_Data_4E5 0;
BA_REL_ "GenSigTimeoutTime" BU_SG_REL_ H_U SG_ 1253 Byte6_Data_4E5 0;
BA_REL_ "GenSigTimeoutTime" BU_SG_REL_ H_U SG_ 1253 Byte7_Data_4E5 0;
BA_REL_ "GenSigTimeoutTime" BU_SG_REL_ CLU SG_ 1252 Byte0_TCP_4E4 0;
BA_REL_ "GenSigTimeoutTime" BU_SG_REL_ CLU SG_ 1252 Byte1_Data_4E4 0;
BA_REL_ "GenSigTimeoutTime" BU_SG_REL_ CLU SG_ 1252 Byte2_Data_4E4 0;
BA_REL_ "GenSigTimeoutTime" BU_SG_REL_ CLU SG_ 1252 Byte3_Data_4E4 0;
BA_REL_ "GenSigTimeoutTime" BU_SG_REL_ CLU SG_ 1252 Byte4_Data_4E4 0;
BA_REL_ "GenSigTimeoutTime" BU_SG_REL_ CLU SG_ 1252 Byte5_Data_4E4 0;
BA_REL_ "GenSigTimeoutTime" BU_SG_REL_ CLU SG_ 1252 Byte6_Data_4E4 0;
BA_REL_ "GenSigTimeoutTime" BU_SG_REL_ CLU SG_ 1252 Byte7_Data_4E4 0;
BA_REL_ "GenSigTimeoutTime" BU_SG_REL_ H_U SG_ 1251 Byte0_TCP_4E3 0;
BA_REL_ "GenSigTimeoutTime" BU_SG_REL_ H_U SG_ 1251 Byte1_Data_4E3 0;
BA_REL_ "GenSigTimeoutTime" BU_SG_REL_ H_U SG_ 1251 Byte2_Data_4E3 0;
BA_REL_ "GenSigTimeoutTime" BU_SG_REL_ H_U SG_ 1251 Byte3_Data_4E3 0;
BA_REL_ "GenSigTimeoutTime" BU_SG_REL_ H_U SG_ 1251 Byte4_Data_4E3 0;
BA_REL_ "GenSigTimeoutTime" BU_SG_REL_ H_U SG_ 1251 Byte5_Data_4E3 0;
BA_REL_ "GenSigTimeoutTime" BU_SG_REL_ H_U SG_ 1251 Byte6_Data_4E3 0;
BA_REL_ "GenSigTimeoutTime" BU_SG_REL_ H_U SG_ 1251 Byte7_Data_4E3 0;
BA_REL_ "GenSigTimeoutTime" BU_SG_REL_ CLU SG_ 1250 Byte0_TCP_4E2 0;
BA_REL_ "GenSigTimeoutTime" BU_SG_REL_ CLU SG_ 1250 Byte1_Data_4E2 0;
BA_REL_ "GenSigTimeoutTime" BU_SG_REL_ CLU SG_ 1250 Byte2_Data_4E2 0;
BA_REL_ "GenSigTimeoutTime" BU_SG_REL_ CLU SG_ 1250 Byte3_Data_4E2 0;
BA_REL_ "GenSigTimeoutTime" BU_SG_REL_ CLU SG_ 1250 Byte4_Data_4E2 0;
BA_REL_ "GenSigTimeoutTime" BU_SG_REL_ CLU SG_ 1250 Byte5_Data_4E2 0;
BA_REL_ "GenSigTimeoutTime" BU_SG_REL_ CLU SG_ 1250 Byte6_Data_4E2 0;
BA_REL_ "GenSigTimeoutTime" BU_SG_REL_ CLU SG_ 1250 Byte7_Data_4E2 0;
BA_REL_ "GenSigTimeoutTime" BU_SG_REL_ H_U SG_ 1248 Byte0_TCP_4E0 0;
BA_REL_ "GenSigTimeoutTime" BU_SG_REL_ H_U SG_ 1248 Byte1_Data_4E0 0;
BA_REL_ "GenSigTimeoutTime" BU_SG_REL_ H_U SG_ 1248 Byte2_Data_4E0 0;
BA_REL_ "GenSigTimeoutTime" BU_SG_REL_ H_U SG_ 1248 Byte3_Data_4E0 0;
BA_REL_ "GenSigTimeoutTime" BU_SG_REL_ H_U SG_ 1248 Byte4_Data_4E0 0;
BA_REL_ "GenSigTimeoutTime" BU_SG_REL_ H_U SG_ 1248 Byte5_Data_4E0 0;
BA_REL_ "GenSigTimeoutTime" BU_SG_REL_ H_U SG_ 1248 Byte6_Data_4E0 0;
BA_REL_ "GenSigTimeoutTime" BU_SG_REL_ H_U SG_ 1248 Byte7_Data_4E0 0;
BA_REL_ "GenSigTimeoutTime" BU_SG_REL_ AMP SG_ 2015 Byte0_TCP_7DF 0;
BA_REL_ "GenSigTimeoutTime" BU_SG_REL_ ASD SG_ 2015 Byte0_TCP_7DF 0;
BA_REL_ "GenSigTimeoutTime" BU_SG_REL_ AVM SG_ 2015 Byte0_TCP_7DF 0;
BA_REL_ "GenSigTimeoutTime" BU_SG_REL_ CCP SG_ 2015 Byte0_TCP_7DF 0;
BA_REL_ "GenSigTimeoutTime" BU_SG_REL_ CGW SG_ 2015 Byte0_TCP_7DF 0;
BA_REL_ "GenSigTimeoutTime" BU_SG_REL_ CLOCK SG_ 2015 Byte0_TCP_7DF 0;
BA_REL_ "GenSigTimeoutTime" BU_SG_REL_ CLU SG_ 2015 Byte0_TCP_7DF 0;
BA_REL_ "GenSigTimeoutTime" BU_SG_REL_ CUBIS SG_ 2015 Byte0_TCP_7DF 0;
BA_REL_ "GenSigTimeoutTime" BU_SG_REL_ DATC SG_ 2015 Byte0_TCP_7DF 0;
BA_REL_ "GenSigTimeoutTime" BU_SG_REL_ FHCU SG_ 2015 Byte0_TCP_7DF 0;
BA_REL_ "GenSigTimeoutTime" BU_SG_REL_ HUD SG_ 2015 Byte0_TCP_7DF 0;
BA_REL_ "GenSigTimeoutTime" BU_SG_REL_ H_U SG_ 2015 Byte0_TCP_7DF 0;
BA_REL_ "GenSigTimeoutTime" BU_SG_REL_ IBOX SG_ 2015 Byte0_TCP_7DF 0;
BA_REL_ "GenSigTimeoutTime" BU_SG_REL_ IPM SG_ 2015 Byte0_TCP_7DF 0;
BA_REL_ "GenSigTimeoutTime" BU_SG_REL_ KBD SG_ 2015 Byte0_TCP_7DF 0;
BA_REL_ "GenSigTimeoutTime" BU_SG_REL_ KMA_TMU SG_ 2015 Byte0_TCP_7DF 0;
BA_REL_ "GenSigTimeoutTime" BU_SG_REL_ MON SG_ 2015 Byte0_TCP_7DF 0;
BA_REL_ "GenSigTimeoutTime" BU_SG_REL_ RRC SG_ 2015 Byte0_TCP_7DF 0;
BA_REL_ "GenSigTimeoutTime" BU_SG_REL_ RSE_L SG_ 2015 Byte0_TCP_7DF 0;
BA_REL_ "GenSigTimeoutTime" BU_SG_REL_ RSE_R SG_ 2015 Byte0_TCP_7DF 0;
BA_REL_ "GenSigTimeoutTime" BU_SG_REL_ TMU SG_ 2015 Byte0_TCP_7DF 0;
BA_REL_ "GenSigTimeoutTime" BU_SG_REL_ AMP SG_ 2015 Byte1_Data_7DF 0;
BA_REL_ "GenSigTimeoutTime" BU_SG_REL_ ASD SG_ 2015 Byte1_Data_7DF 0;
BA_REL_ "GenSigTimeoutTime" BU_SG_REL_ AVM SG_ 2015 Byte1_Data_7DF 0;
BA_REL_ "GenSigTimeoutTime" BU_SG_REL_ CCP SG_ 2015 Byte1_Data_7DF 0;
BA_REL_ "GenSigTimeoutTime" BU_SG_REL_ CGW SG_ 2015 Byte1_Data_7DF 0;
BA_REL_ "GenSigTimeoutTime" BU_SG_REL_ CLOCK SG_ 2015 Byte1_Data_7DF 0;
BA_REL_ "GenSigTimeoutTime" BU_SG_REL_ CLU SG_ 2015 Byte1_Data_7DF 0;
BA_REL_ "GenSigTimeoutTime" BU_SG_REL_ CUBIS SG_ 2015 Byte1_Data_7DF 0;
BA_REL_ "GenSigTimeoutTime" BU_SG_REL_ DATC SG_ 2015 Byte1_Data_7DF 0;
BA_REL_ "GenSigTimeoutTime" BU_SG_REL_ FHCU SG_ 2015 Byte1_Data_7DF 0;
BA_REL_ "GenSigTimeoutTime" BU_SG_REL_ HUD SG_ 2015 Byte1_Data_7DF 0;
BA_REL_ "GenSigTimeoutTime" BU_SG_REL_ H_U SG_ 2015 Byte1_Data_7DF 0;
BA_REL_ "GenSigTimeoutTime" BU_SG_REL_ IBOX SG_ 2015 Byte1_Data_7DF 0;
BA_REL_ "GenSigTimeoutTime" BU_SG_REL_ IPM SG_ 2015 Byte1_Data_7DF 0;
BA_REL_ "GenSigTimeoutTime" BU_SG_REL_ KBD SG_ 2015 Byte1_Data_7DF 0;
BA_REL_ "GenSigTimeoutTime" BU_SG_REL_ KMA_TMU SG_ 2015 Byte1_Data_7DF 0;
BA_REL_ "GenSigTimeoutTime" BU_SG_REL_ MON SG_ 2015 Byte1_Data_7DF 0;
BA_REL_ "GenSigTimeoutTime" BU_SG_REL_ RRC SG_ 2015 Byte1_Data_7DF 0;
BA_REL_ "GenSigTimeoutTime" BU_SG_REL_ RSE_L SG_ 2015 Byte1_Data_7DF 0;
BA_REL_ "GenSigTimeoutTime" BU_SG_REL_ RSE_R SG_ 2015 Byte1_Data_7DF 0;
BA_REL_ "GenSigTimeoutTime" BU_SG_REL_ TMU SG_ 2015 Byte1_Data_7DF 0;
BA_REL_ "GenSigTimeoutTime" BU_SG_REL_ AMP SG_ 2015 Byte2_Data_7DF 0;
BA_REL_ "GenSigTimeoutTime" BU_SG_REL_ ASD SG_ 2015 Byte2_Data_7DF 0;
BA_REL_ "GenSigTimeoutTime" BU_SG_REL_ AVM SG_ 2015 Byte2_Data_7DF 0;
BA_REL_ "GenSigTimeoutTime" BU_SG_REL_ CCP SG_ 2015 Byte2_Data_7DF 0;
BA_REL_ "GenSigTimeoutTime" BU_SG_REL_ CGW SG_ 2015 Byte2_Data_7DF 0;
BA_REL_ "GenSigTimeoutTime" BU_SG_REL_ CLOCK SG_ 2015 Byte2_Data_7DF 0;
BA_REL_ "GenSigTimeoutTime" BU_SG_REL_ CLU SG_ 2015 Byte2_Data_7DF 0;
BA_REL_ "GenSigTimeoutTime" BU_SG_REL_ CUBIS SG_ 2015 Byte2_Data_7DF 0;
BA_REL_ "GenSigTimeoutTime" BU_SG_REL_ DATC SG_ 2015 Byte2_Data_7DF 0;
BA_REL_ "GenSigTimeoutTime" BU_SG_REL_ FHCU SG_ 2015 Byte2_Data_7DF 0;
BA_REL_ "GenSigTimeoutTime" BU_SG_REL_ HUD SG_ 2015 Byte2_Data_7DF 0;
BA_REL_ "GenSigTimeoutTime" BU_SG_REL_ H_U SG_ 2015 Byte2_Data_7DF 0;
BA_REL_ "GenSigTimeoutTime" BU_SG_REL_ IBOX SG_ 2015 Byte2_Data_7DF 0;
BA_REL_ "GenSigTimeoutTime" BU_SG_REL_ IPM SG_ 2015 Byte2_Data_7DF 0;
BA_REL_ "GenSigTimeoutTime" BU_SG_REL_ KBD SG_ 2015 Byte2_Data_7DF 0;
BA_REL_ "GenSigTimeoutTime" BU_SG_REL_ KMA_TMU SG_ 2015 Byte2_Data_7DF 0;
BA_REL_ "GenSigTimeoutTime" BU_SG_REL_ MON SG_ 2015 Byte2_Data_7DF 0;
BA_REL_ "GenSigTimeoutTime" BU_SG_REL_ RRC SG_ 2015 Byte2_Data_7DF 0;
BA_REL_ "GenSigTimeoutTime" BU_SG_REL_ RSE_L SG_ 2015 Byte2_Data_7DF 0;
BA_REL_ "GenSigTimeoutTime" BU_SG_REL_ RSE_R SG_ 2015 Byte2_Data_7DF 0;
BA_REL_ "GenSigTimeoutTime" BU_SG_REL_ TMU SG_ 2015 Byte2_Data_7DF 0;
BA_REL_ "GenSigTimeoutTime" BU_SG_REL_ AMP SG_ 2015 Byte3_Data_7DF 0;
BA_REL_ "GenSigTimeoutTime" BU_SG_REL_ ASD SG_ 2015 Byte3_Data_7DF 0;
BA_REL_ "GenSigTimeoutTime" BU_SG_REL_ AVM SG_ 2015 Byte3_Data_7DF 0;
BA_REL_ "GenSigTimeoutTime" BU_SG_REL_ CCP SG_ 2015 Byte3_Data_7DF 0;
BA_REL_ "GenSigTimeoutTime" BU_SG_REL_ CGW SG_ 2015 Byte3_Data_7DF 0;
BA_REL_ "GenSigTimeoutTime" BU_SG_REL_ CLOCK SG_ 2015 Byte3_Data_7DF 0;
BA_REL_ "GenSigTimeoutTime" BU_SG_REL_ CLU SG_ 2015 Byte3_Data_7DF 0;
BA_REL_ "GenSigTimeoutTime" BU_SG_REL_ CUBIS SG_ 2015 Byte3_Data_7DF 0;
BA_REL_ "GenSigTimeoutTime" BU_SG_REL_ DATC SG_ 2015 Byte3_Data_7DF 0;
BA_REL_ "GenSigTimeoutTime" BU_SG_REL_ FHCU SG_ 2015 Byte3_Data_7DF 0;
BA_REL_ "GenSigTimeoutTime" BU_SG_REL_ HUD SG_ 2015 Byte3_Data_7DF 0;
BA_REL_ "GenSigTimeoutTime" BU_SG_REL_ H_U SG_ 2015 Byte3_Data_7DF 0;
BA_REL_ "GenSigTimeoutTime" BU_SG_REL_ IBOX SG_ 2015 Byte3_Data_7DF 0;
BA_REL_ "GenSigTimeoutTime" BU_SG_REL_ IPM SG_ 2015 Byte3_Data_7DF 0;
BA_REL_ "GenSigTimeoutTime" BU_SG_REL_ KBD SG_ 2015 Byte3_Data_7DF 0;
BA_REL_ "GenSigTimeoutTime" BU_SG_REL_ KMA_TMU SG_ 2015 Byte3_Data_7DF 0;
BA_REL_ "GenSigTimeoutTime" BU_SG_REL_ MON SG_ 2015 Byte3_Data_7DF 0;
BA_REL_ "GenSigTimeoutTime" BU_SG_REL_ RRC SG_ 2015 Byte3_Data_7DF 0;
BA_REL_ "GenSigTimeoutTime" BU_SG_REL_ RSE_L SG_ 2015 Byte3_Data_7DF 0;
BA_REL_ "GenSigTimeoutTime" BU_SG_REL_ RSE_R SG_ 2015 Byte3_Data_7DF 0;
BA_REL_ "GenSigTimeoutTime" BU_SG_REL_ TMU SG_ 2015 Byte3_Data_7DF 0;
BA_REL_ "GenSigTimeoutTime" BU_SG_REL_ AMP SG_ 2015 Byte4_Data_7DF 0;
BA_REL_ "GenSigTimeoutTime" BU_SG_REL_ ASD SG_ 2015 Byte4_Data_7DF 0;
BA_REL_ "GenSigTimeoutTime" BU_SG_REL_ AVM SG_ 2015 Byte4_Data_7DF 0;
BA_REL_ "GenSigTimeoutTime" BU_SG_REL_ CCP SG_ 2015 Byte4_Data_7DF 0;
BA_REL_ "GenSigTimeoutTime" BU_SG_REL_ CGW SG_ 2015 Byte4_Data_7DF 0;
BA_REL_ "GenSigTimeoutTime" BU_SG_REL_ CLOCK SG_ 2015 Byte4_Data_7DF 0;
BA_REL_ "GenSigTimeoutTime" BU_SG_REL_ CLU SG_ 2015 Byte4_Data_7DF 0;
BA_REL_ "GenSigTimeoutTime" BU_SG_REL_ CUBIS SG_ 2015 Byte4_Data_7DF 0;
BA_REL_ "GenSigTimeoutTime" BU_SG_REL_ DATC SG_ 2015 Byte4_Data_7DF 0;
BA_REL_ "GenSigTimeoutTime" BU_SG_REL_ FHCU SG_ 2015 Byte4_Data_7DF 0;
BA_REL_ "GenSigTimeoutTime" BU_SG_REL_ HUD SG_ 2015 Byte4_Data_7DF 0;
BA_REL_ "GenSigTimeoutTime" BU_SG_REL_ H_U SG_ 2015 Byte4_Data_7DF 0;
BA_REL_ "GenSigTimeoutTime" BU_SG_REL_ IBOX SG_ 2015 Byte4_Data_7DF 0;
BA_REL_ "GenSigTimeoutTime" BU_SG_REL_ IPM SG_ 2015 Byte4_Data_7DF 0;
BA_REL_ "GenSigTimeoutTime" BU_SG_REL_ KBD SG_ 2015 Byte4_Data_7DF 0;
BA_REL_ "GenSigTimeoutTime" BU_SG_REL_ KMA_TMU SG_ 2015 Byte4_Data_7DF 0;
BA_REL_ "GenSigTimeoutTime" BU_SG_REL_ MON SG_ 2015 Byte4_Data_7DF 0;
BA_REL_ "GenSigTimeoutTime" BU_SG_REL_ RRC SG_ 2015 Byte4_Data_7DF 0;
BA_REL_ "GenSigTimeoutTime" BU_SG_REL_ RSE_L SG_ 2015 Byte4_Data_7DF 0;
BA_REL_ "GenSigTimeoutTime" BU_SG_REL_ RSE_R SG_ 2015 Byte4_Data_7DF 0;
BA_REL_ "GenSigTimeoutTime" BU_SG_REL_ TMU SG_ 2015 Byte4_Data_7DF 0;
BA_REL_ "GenSigTimeoutTime" BU_SG_REL_ AMP SG_ 2015 Byte5_Data_7DF 0;
BA_REL_ "GenSigTimeoutTime" BU_SG_REL_ ASD SG_ 2015 Byte5_Data_7DF 0;
BA_REL_ "GenSigTimeoutTime" BU_SG_REL_ AVM SG_ 2015 Byte5_Data_7DF 0;
BA_REL_ "GenSigTimeoutTime" BU_SG_REL_ CCP SG_ 2015 Byte5_Data_7DF 0;
BA_REL_ "GenSigTimeoutTime" BU_SG_REL_ CGW SG_ 2015 Byte5_Data_7DF 0;
BA_REL_ "GenSigTimeoutTime" BU_SG_REL_ CLOCK SG_ 2015 Byte5_Data_7DF 0;
BA_REL_ "GenSigTimeoutTime" BU_SG_REL_ CLU SG_ 2015 Byte5_Data_7DF 0;
BA_REL_ "GenSigTimeoutTime" BU_SG_REL_ CUBIS SG_ 2015 Byte5_Data_7DF 0;
BA_REL_ "GenSigTimeoutTime" BU_SG_REL_ DATC SG_ 2015 Byte5_Data_7DF 0;
BA_REL_ "GenSigTimeoutTime" BU_SG_REL_ FHCU SG_ 2015 Byte5_Data_7DF 0;
BA_REL_ "GenSigTimeoutTime" BU_SG_REL_ HUD SG_ 2015 Byte5_Data_7DF 0;
BA_REL_ "GenSigTimeoutTime" BU_SG_REL_ H_U SG_ 2015 Byte5_Data_7DF 0;
BA_REL_ "GenSigTimeoutTime" BU_SG_REL_ IBOX SG_ 2015 Byte5_Data_7DF 0;
BA_REL_ "GenSigTimeoutTime" BU_SG_REL_ IPM SG_ 2015 Byte5_Data_7DF 0;
BA_REL_ "GenSigTimeoutTime" BU_SG_REL_ KBD SG_ 2015 Byte5_Data_7DF 0;
BA_REL_ "GenSigTimeoutTime" BU_SG_REL_ KMA_TMU SG_ 2015 Byte5_Data_7DF 0;
BA_REL_ "GenSigTimeoutTime" BU_SG_REL_ MON SG_ 2015 Byte5_Data_7DF 0;
BA_REL_ "GenSigTimeoutTime" BU_SG_REL_ RRC SG_ 2015 Byte5_Data_7DF 0;
BA_REL_ "GenSigTimeoutTime" BU_SG_REL_ RSE_L SG_ 2015 Byte5_Data_7DF 0;
BA_REL_ "GenSigTimeoutTime" BU_SG_REL_ RSE_R SG_ 2015 Byte5_Data_7DF 0;
BA_REL_ "GenSigTimeoutTime" BU_SG_REL_ TMU SG_ 2015 Byte5_Data_7DF 0;
BA_REL_ "GenSigTimeoutTime" BU_SG_REL_ AMP SG_ 2015 Byte6_Data_7DF 0;
BA_REL_ "GenSigTimeoutTime" BU_SG_REL_ ASD SG_ 2015 Byte6_Data_7DF 0;
BA_REL_ "GenSigTimeoutTime" BU_SG_REL_ AVM SG_ 2015 Byte6_Data_7DF 0;
BA_REL_ "GenSigTimeoutTime" BU_SG_REL_ CCP SG_ 2015 Byte6_Data_7DF 0;
BA_REL_ "GenSigTimeoutTime" BU_SG_REL_ CGW SG_ 2015 Byte6_Data_7DF 0;
BA_REL_ "GenSigTimeoutTime" BU_SG_REL_ CLOCK SG_ 2015 Byte6_Data_7DF 0;
BA_REL_ "GenSigTimeoutTime" BU_SG_REL_ CLU SG_ 2015 Byte6_Data_7DF 0;
BA_REL_ "GenSigTimeoutTime" BU_SG_REL_ CUBIS SG_ 2015 Byte6_Data_7DF 0;
BA_REL_ "GenSigTimeoutTime" BU_SG_REL_ DATC SG_ 2015 Byte6_Data_7DF 0;
BA_REL_ "GenSigTimeoutTime" BU_SG_REL_ FHCU SG_ 2015 Byte6_Data_7DF 0;
BA_REL_ "GenSigTimeoutTime" BU_SG_REL_ HUD SG_ 2015 Byte6_Data_7DF 0;
BA_REL_ "GenSigTimeoutTime" BU_SG_REL_ H_U SG_ 2015 Byte6_Data_7DF 0;
BA_REL_ "GenSigTimeoutTime" BU_SG_REL_ IBOX SG_ 2015 Byte6_Data_7DF 0;
BA_REL_ "GenSigTimeoutTime" BU_SG_REL_ IPM SG_ 2015 Byte6_Data_7DF 0;
BA_REL_ "GenSigTimeoutTime" BU_SG_REL_ KBD SG_ 2015 Byte6_Data_7DF 0;
BA_REL_ "GenSigTimeoutTime" BU_SG_REL_ KMA_TMU SG_ 2015 Byte6_Data_7DF 0;
BA_REL_ "GenSigTimeoutTime" BU_SG_REL_ MON SG_ 2015 Byte6_Data_7DF 0;
BA_REL_ "GenSigTimeoutTime" BU_SG_REL_ RRC SG_ 2015 Byte6_Data_7DF 0;
BA_REL_ "GenSigTimeoutTime" BU_SG_REL_ RSE_L SG_ 2015 Byte6_Data_7DF 0;
BA_REL_ "GenSigTimeoutTime" BU_SG_REL_ RSE_R SG_ 2015 Byte6_Data_7DF 0;
BA_REL_ "GenSigTimeoutTime" BU_SG_REL_ TMU SG_ 2015 Byte6_Data_7DF 0;
BA_REL_ "GenSigTimeoutTime" BU_SG_REL_ AMP SG_ 2015 Byte7_Data_7DF 0;
BA_REL_ "GenSigTimeoutTime" BU_SG_REL_ ASD SG_ 2015 Byte7_Data_7DF 0;
BA_REL_ "GenSigTimeoutTime" BU_SG_REL_ AVM SG_ 2015 Byte7_Data_7DF 0;
BA_REL_ "GenSigTimeoutTime" BU_SG_REL_ CCP SG_ 2015 Byte7_Data_7DF 0;
BA_REL_ "GenSigTimeoutTime" BU_SG_REL_ CGW SG_ 2015 Byte7_Data_7DF 0;
BA_REL_ "GenSigTimeoutTime" BU_SG_REL_ CLOCK SG_ 2015 Byte7_Data_7DF 0;
BA_REL_ "GenSigTimeoutTime" BU_SG_REL_ CLU SG_ 2015 Byte7_Data_7DF 0;
BA_REL_ "GenSigTimeoutTime" BU_SG_REL_ CUBIS SG_ 2015 Byte7_Data_7DF 0;
BA_REL_ "GenSigTimeoutTime" BU_SG_REL_ DATC SG_ 2015 Byte7_Data_7DF 0;
BA_REL_ "GenSigTimeoutTime" BU_SG_REL_ FHCU SG_ 2015 Byte7_Data_7DF 0;
BA_REL_ "GenSigTimeoutTime" BU_SG_REL_ HUD SG_ 2015 Byte7_Data_7DF 0;
BA_REL_ "GenSigTimeoutTime" BU_SG_REL_ H_U SG_ 2015 Byte7_Data_7DF 0;
BA_REL_ "GenSigTimeoutTime" BU_SG_REL_ IBOX SG_ 2015 Byte7_Data_7DF 0;
BA_REL_ "GenSigTimeoutTime" BU_SG_REL_ IPM SG_ 2015 Byte7_Data_7DF 0;
BA_REL_ "GenSigTimeoutTime" BU_SG_REL_ KBD SG_ 2015 Byte7_Data_7DF 0;
BA_REL_ "GenSigTimeoutTime" BU_SG_REL_ KMA_TMU SG_ 2015 Byte7_Data_7DF 0;
BA_REL_ "GenSigTimeoutTime" BU_SG_REL_ MON SG_ 2015 Byte7_Data_7DF 0;
BA_REL_ "GenSigTimeoutTime" BU_SG_REL_ RRC SG_ 2015 Byte7_Data_7DF 0;
BA_REL_ "GenSigTimeoutTime" BU_SG_REL_ RSE_L SG_ 2015 Byte7_Data_7DF 0;
BA_REL_ "GenSigTimeoutTime" BU_SG_REL_ RSE_R SG_ 2015 Byte7_Data_7DF 0;
BA_REL_ "GenSigTimeoutTime" BU_SG_REL_ TMU SG_ 2015 Byte7_Data_7DF 0;
BA_REL_ "GenSigTimeoutTime" BU_SG_REL_ H_U SG_ 1495 Clu_TripUnit 3500;
BA_REL_ "GenSigTimeoutTime" BU_SG_REL_ IBOX SG_ 1495 Clu_TripUnit 3500;
BA_REL_ "GenSigTimeoutTime" BU_SG_REL_ H_U SG_ 1495 Clu_DTEWarn 3500;
BA_REL_ "GenSigTimeoutTime" BU_SG_REL_ IBOX SG_ 1495 Clu_DTEWarn 3500;
BA_REL_ "GenSigTimeoutTime" BU_SG_REL_ H_U SG_ 1495 Clu_DTE 3500;
BA_REL_ "GenSigTimeoutTime" BU_SG_REL_ IBOX SG_ 1495 Clu_DTE 3500;
BA_REL_ "GenSigTimeoutTime" BU_SG_REL_ H_U SG_ 1495 Clu_AFC 3500;
BA_REL_ "GenSigTimeoutTime" BU_SG_REL_ IBOX SG_ 1495 Clu_AFC 3500;
BA_REL_ "GenSigTimeoutTime" BU_SG_REL_ H_U SG_ 1495 Clu_IFC 3500;
BA_REL_ "GenSigTimeoutTime" BU_SG_REL_ IBOX SG_ 1495 Clu_IFC 3500;
BA_REL_ "GenSigTimeoutTime" BU_SG_REL_ H_U SG_ 1495 Clu_Odometer 3500;
BA_REL_ "GenSigTimeoutTime" BU_SG_REL_ IBOX SG_ 1495 Clu_Odometer 3500;
BA_REL_ "GenSigTimeoutTime" BU_SG_REL_ H_U SG_ 214 AMP_SWVerMajor 0;
BA_REL_ "GenSigTimeoutTime" BU_SG_REL_ IBOX SG_ 214 AMP_SWVerMajor 0;
BA_REL_ "GenSigTimeoutTime" BU_SG_REL_ H_U SG_ 214 AMP_SWVerMinor 0;
BA_REL_ "GenSigTimeoutTime" BU_SG_REL_ IBOX SG_ 214 AMP_SWVerMinor 0;
BA_REL_ "GenSigTimeoutTime" BU_SG_REL_ H_U SG_ 214 AMP_CANVerMajor 0;
BA_REL_ "GenSigTimeoutTime" BU_SG_REL_ IBOX SG_ 214 AMP_CANVerMajor 0;
BA_REL_ "GenSigTimeoutTime" BU_SG_REL_ H_U SG_ 214 AMP_CANVerMinor 0;
BA_REL_ "GenSigTimeoutTime" BU_SG_REL_ IBOX SG_ 214 AMP_CANVerMinor 0;
BA_REL_ "GenSigTimeoutTime" BU_SG_REL_ H_U SG_ 214 AMP_RBDResult 0;
BA_REL_ "GenSigTimeoutTime" BU_SG_REL_ H_U SG_ 214 AMP_MOSTErrorDiagResult 0;
BA_REL_ "GenSigTimeoutTime" BU_SG_REL_ H_U SG_ 214 AMP_HWVerMajor 0;
BA_REL_ "GenSigTimeoutTime" BU_SG_REL_ IBOX SG_ 214 AMP_HWVerMajor 0;
BA_REL_ "GenSigTimeoutTime" BU_SG_REL_ H_U SG_ 214 AMP_HWVerMinor 0;
BA_REL_ "GenSigTimeoutTime" BU_SG_REL_ IBOX SG_ 214 AMP_HWVerMinor 0;
BA_REL_ "GenSigTimeoutTime" BU_SG_REL_ TMU SG_ 1232 Byte0_TCP_4D0 0;
BA_REL_ "GenSigTimeoutTime" BU_SG_REL_ TMU SG_ 1232 Byte1_Data_4D0 0;
BA_REL_ "GenSigTimeoutTime" BU_SG_REL_ TMU SG_ 1232 Byte2_Data_4D0 0;
BA_REL_ "GenSigTimeoutTime" BU_SG_REL_ TMU SG_ 1232 Byte3_Data_4D0 0;
BA_REL_ "GenSigTimeoutTime" BU_SG_REL_ TMU SG_ 1232 Byte4_Data_4D0 0;
BA_REL_ "GenSigTimeoutTime" BU_SG_REL_ TMU SG_ 1232 Byte5_Data_4D0 0;
BA_REL_ "GenSigTimeoutTime" BU_SG_REL_ TMU SG_ 1232 Byte6_Data_4D0 0;
BA_REL_ "GenSigTimeoutTime" BU_SG_REL_ TMU SG_ 1232 Byte7_Data_4D0 0;
BA_REL_ "GenSigTimeoutTime" BU_SG_REL_ H_U SG_ 208 CLU_SWVerMajor 0;
BA_REL_ "GenSigTimeoutTime" BU_SG_REL_ H_U SG_ 208 CLU_SWVerMinor 0;
BA_REL_ "GenSigTimeoutTime" BU_SG_REL_ H_U SG_ 208 CLU_CANVerMajor 0;
BA_REL_ "GenSigTimeoutTime" BU_SG_REL_ H_U SG_ 208 CLU_CANVerMinor 0;
BA_REL_ "GenSigTimeoutTime" BU_SG_REL_ H_U SG_ 208 CLU_HWVerMajor 0;
BA_REL_ "GenSigTimeoutTime" BU_SG_REL_ H_U SG_ 208 CLU_HWVerMinor 0;
BA_REL_ "GenSigTimeoutTime" BU_SG_REL_ CGW SG_ 448 DATC_AqsLevelChg 3500;
BA_REL_ "GenSigTimeoutTime" BU_SG_REL_ CLU SG_ 448 DATC_AqsLevelChg 3500;
BA_REL_ "GenSigTimeoutTime" BU_SG_REL_ DATC SG_ 448 DATC_AqsLevelChg 3500;
BA_REL_ "GenSigTimeoutTime" BU_SG_REL_ IPM SG_ 448 DATC_AqsLevelChg 3500;
BA_REL_ "GenSigTimeoutTime" BU_SG_REL_ CGW SG_ 448 RSELockOnOff 3500;
BA_REL_ "GenSigTimeoutTime" BU_SG_REL_ DATC SG_ 448 RSELockOnOff 3500;
BA_REL_ "GenSigTimeoutTime" BU_SG_REL_ IPM SG_ 448 RSELockOnOff 3500;
BA_REL_ "GenSigTimeoutTime" BU_SG_REL_ RRC SG_ 448 RSELockOnOff 3500;
BA_REL_ "GenSigTimeoutTime" BU_SG_REL_ CGW SG_ 448 DATC_AqsMode 3500;
BA_REL_ "GenSigTimeoutTime" BU_SG_REL_ CLU SG_ 448 DATC_AqsMode 3500;
BA_REL_ "GenSigTimeoutTime" BU_SG_REL_ DATC SG_ 448 DATC_AqsMode 3500;
BA_REL_ "GenSigTimeoutTime" BU_SG_REL_ IPM SG_ 448 DATC_AqsMode 3500;
BA_REL_ "GenSigTimeoutTime" BU_SG_REL_ CGW SG_ 448 HU_Graphreset_Info 3500;
BA_REL_ "GenSigTimeoutTime" BU_SG_REL_ CLU SG_ 448 HU_Graphreset_Info 3500;
BA_REL_ "GenSigTimeoutTime" BU_SG_REL_ DATC SG_ 448 HU_Graphreset_Info 3500;
BA_REL_ "GenSigTimeoutTime" BU_SG_REL_ IPM SG_ 448 HU_Graphreset_Info 3500;
BA_REL_ "GenSigTimeoutTime" BU_SG_REL_ CGW SG_ 448 HU_VRActivity 3500;
BA_REL_ "GenSigTimeoutTime" BU_SG_REL_ CLU SG_ 448 HU_VRActivity 3500;
BA_REL_ "GenSigTimeoutTime" BU_SG_REL_ DATC SG_ 448 HU_VRActivity 3500;
BA_REL_ "GenSigTimeoutTime" BU_SG_REL_ IPM SG_ 448 HU_VRActivity 3500;
BA_REL_ "GenSigTimeoutTime" BU_SG_REL_ CGW SG_ 448 HU_PhoneActivity 3500;
BA_REL_ "GenSigTimeoutTime" BU_SG_REL_ CLU SG_ 448 HU_PhoneActivity 3500;
BA_REL_ "GenSigTimeoutTime" BU_SG_REL_ DATC SG_ 448 HU_PhoneActivity 3500;
BA_REL_ "GenSigTimeoutTime" BU_SG_REL_ IPM SG_ 448 HU_PhoneActivity 3500;
BA_REL_ "GenSigTimeoutTime" BU_SG_REL_ CGW SG_ 448 BlowerNoiseControl 3500;
BA_REL_ "GenSigTimeoutTime" BU_SG_REL_ CLU SG_ 448 BlowerNoiseControl 3500;
BA_REL_ "GenSigTimeoutTime" BU_SG_REL_ DATC SG_ 448 BlowerNoiseControl 3500;
BA_REL_ "GenSigTimeoutTime" BU_SG_REL_ IPM SG_ 448 BlowerNoiseControl 3500;
BA_REL_ "GenSigTimeoutTime" BU_SG_REL_ CLU SG_ 1211 Byte0_TCP_4BB 0;
BA_REL_ "GenSigTimeoutTime" BU_SG_REL_ CLU SG_ 1211 Byte1_Data_4BB 0;
BA_REL_ "GenSigTimeoutTime" BU_SG_REL_ CLU SG_ 1211 Byte2_Data_4BB 0;
BA_REL_ "GenSigTimeoutTime" BU_SG_REL_ CLU SG_ 1211 Byte3_Data_4BB 0;
BA_REL_ "GenSigTimeoutTime" BU_SG_REL_ CLU SG_ 1211 Byte4_Data_4BB 0;
BA_REL_ "GenSigTimeoutTime" BU_SG_REL_ CLU SG_ 1211 Byte5_Data_4BB 0;
BA_REL_ "GenSigTimeoutTime" BU_SG_REL_ CLU SG_ 1211 Byte6_Data_4BB 0;
BA_REL_ "GenSigTimeoutTime" BU_SG_REL_ CLU SG_ 1211 Byte7_Data_4BB 0;
BA_REL_ "GenSigTimeoutTime" BU_SG_REL_ CLU SG_ 1207 Byte0_TCP_4B7 0;
BA_REL_ "GenSigTimeoutTime" BU_SG_REL_ CLU SG_ 1207 Byte1_Data_4B7 0;
BA_REL_ "GenSigTimeoutTime" BU_SG_REL_ CLU SG_ 1207 Byte2_Data_4B7 0;
BA_REL_ "GenSigTimeoutTime" BU_SG_REL_ CLU SG_ 1207 Byte3_Data_4B7 0;
BA_REL_ "GenSigTimeoutTime" BU_SG_REL_ CLU SG_ 1207 Byte4_Data_4B7 0;
BA_REL_ "GenSigTimeoutTime" BU_SG_REL_ CLU SG_ 1207 Byte5_Data_4B7 0;
BA_REL_ "GenSigTimeoutTime" BU_SG_REL_ CLU SG_ 1207 Byte6_Data_4B7 0;
BA_REL_ "GenSigTimeoutTime" BU_SG_REL_ CLU SG_ 1207 Byte7_Data_4B7 0;
BA_REL_ "GenSigTimeoutTime" BU_SG_REL_ CLU SG_ 1206 Byte0_TCP_4B6 0;
BA_REL_ "GenSigTimeoutTime" BU_SG_REL_ CLU SG_ 1206 Byte1_Data_4B6 0;
BA_REL_ "GenSigTimeoutTime" BU_SG_REL_ CLU SG_ 1206 Byte2_Data_4B6 0;
BA_REL_ "GenSigTimeoutTime" BU_SG_REL_ CLU SG_ 1206 Byte3_Data_4B6 0;
BA_REL_ "GenSigTimeoutTime" BU_SG_REL_ CLU SG_ 1206 Byte4_Data_4B6 0;
BA_REL_ "GenSigTimeoutTime" BU_SG_REL_ CLU SG_ 1206 Byte5_Data_4B6 0;
BA_REL_ "GenSigTimeoutTime" BU_SG_REL_ CLU SG_ 1206 Byte6_Data_4B6 0;
BA_REL_ "GenSigTimeoutTime" BU_SG_REL_ CLU SG_ 1206 Byte7_Data_4B6 0;
BA_REL_ "GenSigTimeoutTime" BU_SG_REL_ CLU SG_ 1204 Byte0_TCP_4B4 0;
BA_REL_ "GenSigTimeoutTime" BU_SG_REL_ CLU SG_ 1204 Byte1_Data_4B4 0;
BA_REL_ "GenSigTimeoutTime" BU_SG_REL_ CLU SG_ 1204 Byte2_Data_4B4 0;
BA_REL_ "GenSigTimeoutTime" BU_SG_REL_ CLU SG_ 1204 Byte3_Data_4B4 0;
BA_REL_ "GenSigTimeoutTime" BU_SG_REL_ CLU SG_ 1204 Byte4_Data_4B4 0;
BA_REL_ "GenSigTimeoutTime" BU_SG_REL_ CLU SG_ 1204 Byte5_Data_4B4 0;
BA_REL_ "GenSigTimeoutTime" BU_SG_REL_ CLU SG_ 1204 Byte6_Data_4B4 0;
BA_REL_ "GenSigTimeoutTime" BU_SG_REL_ CLU SG_ 1204 Byte7_Data_4B4 0;
BA_REL_ "GenSigTimeoutTime" BU_SG_REL_ CGW SG_ 432 C_DATCOnOffReq 3500;
BA_REL_ "GenSigTimeoutTime" BU_SG_REL_ CLU SG_ 432 C_DATCOnOffReq 3500;
BA_REL_ "GenSigTimeoutTime" BU_SG_REL_ DATC SG_ 432 C_DATCOnOffReq 3500;
BA_REL_ "GenSigTimeoutTime" BU_SG_REL_ H_U SG_ 432 C_DATCOnOffReq 3500;
BA_REL_ "GenSigTimeoutTime" BU_SG_REL_ IPM SG_ 432 C_DATCOnOffReq 3500;
BA_REL_ "GenSigTimeoutTime" BU_SG_REL_ CGW SG_ 432 C_DATCTempUnit 3500;
BA_REL_ "GenSigTimeoutTime" BU_SG_REL_ CLU SG_ 432 C_DATCTempUnit 3500;
BA_REL_ "GenSigTimeoutTime" BU_SG_REL_ DATC SG_ 432 C_DATCTempUnit 3500;
BA_REL_ "GenSigTimeoutTime" BU_SG_REL_ H_U SG_ 432 C_DATCTempUnit 3500;
BA_REL_ "GenSigTimeoutTime" BU_SG_REL_ IPM SG_ 432 C_DATCTempUnit 3500;
BA_REL_ "GenSigTimeoutTime" BU_SG_REL_ CGW SG_ 432 C_DATCTempSet 3500;
BA_REL_ "GenSigTimeoutTime" BU_SG_REL_ CLU SG_ 432 C_DATCTempSet 3500;
BA_REL_ "GenSigTimeoutTime" BU_SG_REL_ DATC SG_ 432 C_DATCTempSet 3500;
BA_REL_ "GenSigTimeoutTime" BU_SG_REL_ H_U SG_ 432 C_DATCTempSet 3500;
BA_REL_ "GenSigTimeoutTime" BU_SG_REL_ IPM SG_ 432 C_DATCTempSet 3500;
BA_REL_ "GenSigTimeoutTime" BU_SG_REL_ CGW SG_ 432 TMU_IVRActivity 3500;
BA_REL_ "GenSigTimeoutTime" BU_SG_REL_ CLU SG_ 432 TMU_IVRActivity 3500;
BA_REL_ "GenSigTimeoutTime" BU_SG_REL_ DATC SG_ 432 TMU_IVRActivity 3500;
BA_REL_ "GenSigTimeoutTime" BU_SG_REL_ H_U SG_ 432 TMU_IVRActivity 3500;
BA_REL_ "GenSigTimeoutTime" BU_SG_REL_ IPM SG_ 432 TMU_IVRActivity 3500;
BA_REL_ "GenSigTimeoutTime" BU_SG_REL_ CGW SG_ 432 TMU_PhoneActivity 3500;
BA_REL_ "GenSigTimeoutTime" BU_SG_REL_ CLU SG_ 432 TMU_PhoneActivity 3500;
BA_REL_ "GenSigTimeoutTime" BU_SG_REL_ DATC SG_ 432 TMU_PhoneActivity 3500;
BA_REL_ "GenSigTimeoutTime" BU_SG_REL_ H_U SG_ 432 TMU_PhoneActivity 3500;
BA_REL_ "GenSigTimeoutTime" BU_SG_REL_ IPM SG_ 432 TMU_PhoneActivity 3500;
BA_REL_ "GenSigTimeoutTime" BU_SG_REL_ H_U SG_ 1195 Byte0_TCP_4AB 0;
BA_REL_ "GenSigTimeoutTime" BU_SG_REL_ H_U SG_ 1195 Byte1_Data_4AB 0;
BA_REL_ "GenSigTimeoutTime" BU_SG_REL_ H_U SG_ 1195 Byte2_Data_4AB 0;
BA_REL_ "GenSigTimeoutTime" BU_SG_REL_ H_U SG_ 1195 Byte3_Data_4AB 0;
BA_REL_ "GenSigTimeoutTime" BU_SG_REL_ H_U SG_ 1195 Byte4_Data_4AB 0;
BA_REL_ "GenSigTimeoutTime" BU_SG_REL_ H_U SG_ 1195 Byte5_Data_4AB 0;
BA_REL_ "GenSigTimeoutTime" BU_SG_REL_ H_U SG_ 1195 Byte6_Data_4AB 0;
BA_REL_ "GenSigTimeoutTime" BU_SG_REL_ H_U SG_ 1195 Byte7_Data_4AB 0;
BA_REL_ "GenSigTimeoutTime" BU_SG_REL_ H_U SG_ 1191 Byte0_TCP_4A7 0;
BA_REL_ "GenSigTimeoutTime" BU_SG_REL_ H_U SG_ 1191 Byte1_Data_4A7 0;
BA_REL_ "GenSigTimeoutTime" BU_SG_REL_ H_U SG_ 1191 Byte2_Data_4A7 0;
BA_REL_ "GenSigTimeoutTime" BU_SG_REL_ H_U SG_ 1191 Byte3_Data_4A7 0;
BA_REL_ "GenSigTimeoutTime" BU_SG_REL_ H_U SG_ 1191 Byte4_Data_4A7 0;
BA_REL_ "GenSigTimeoutTime" BU_SG_REL_ H_U SG_ 1191 Byte5_Data_4A7 0;
BA_REL_ "GenSigTimeoutTime" BU_SG_REL_ H_U SG_ 1191 Byte6_Data_4A7 0;
BA_REL_ "GenSigTimeoutTime" BU_SG_REL_ H_U SG_ 1191 Byte7_Data_4A7 0;
BA_REL_ "GenSigTimeoutTime" BU_SG_REL_ H_U SG_ 1190 Byte0_TCP_4A6 0;
BA_REL_ "GenSigTimeoutTime" BU_SG_REL_ H_U SG_ 1190 Byte1_Data_4A6 0;
BA_REL_ "GenSigTimeoutTime" BU_SG_REL_ H_U SG_ 1190 Byte2_Data_4A6 0;
BA_REL_ "GenSigTimeoutTime" BU_SG_REL_ H_U SG_ 1190 Byte3_Data_4A6 0;
BA_REL_ "GenSigTimeoutTime" BU_SG_REL_ H_U SG_ 1190 Byte4_Data_4A6 0;
BA_REL_ "GenSigTimeoutTime" BU_SG_REL_ H_U SG_ 1190 Byte5_Data_4A6 0;
BA_REL_ "GenSigTimeoutTime" BU_SG_REL_ H_U SG_ 1190 Byte6_Data_4A6 0;
BA_REL_ "GenSigTimeoutTime" BU_SG_REL_ H_U SG_ 1190 Byte7_Data_4A6 0;
BA_REL_ "GenSigTimeoutTime" BU_SG_REL_ H_U SG_ 1188 Byte0_TCP_4A4 0;
BA_REL_ "GenSigTimeoutTime" BU_SG_REL_ H_U SG_ 1188 Byte1_Data_4A4 0;
BA_REL_ "GenSigTimeoutTime" BU_SG_REL_ H_U SG_ 1188 Byte2_Data_4A4 0;
BA_REL_ "GenSigTimeoutTime" BU_SG_REL_ H_U SG_ 1188 Byte3_Data_4A4 0;
BA_REL_ "GenSigTimeoutTime" BU_SG_REL_ H_U SG_ 1188 Byte4_Data_4A4 0;
BA_REL_ "GenSigTimeoutTime" BU_SG_REL_ H_U SG_ 1188 Byte5_Data_4A4 0;
BA_REL_ "GenSigTimeoutTime" BU_SG_REL_ H_U SG_ 1188 Byte6_Data_4A4 0;
BA_REL_ "GenSigTimeoutTime" BU_SG_REL_ H_U SG_ 1188 Byte7_Data_4A4 0;
BA_REL_ "GenSigTimeoutTime" BU_SG_REL_ CLU SG_ 1179 Byte0_TCP_49B 0;
BA_REL_ "GenSigTimeoutTime" BU_SG_REL_ CLU SG_ 1179 Byte1_Data_49B 0;
BA_REL_ "GenSigTimeoutTime" BU_SG_REL_ CLU SG_ 1179 Byte2_Data_49B 0;
BA_REL_ "GenSigTimeoutTime" BU_SG_REL_ CLU SG_ 1179 Byte3_Data_49B 0;
BA_REL_ "GenSigTimeoutTime" BU_SG_REL_ CLU SG_ 1179 Byte4_Data_49B 0;
BA_REL_ "GenSigTimeoutTime" BU_SG_REL_ CLU SG_ 1179 Byte5_Data_49B 0;
BA_REL_ "GenSigTimeoutTime" BU_SG_REL_ CLU SG_ 1179 Byte6_Data_49B 0;
BA_REL_ "GenSigTimeoutTime" BU_SG_REL_ CLU SG_ 1179 Byte7_Data_49B 0;
BA_REL_ "GenSigTimeoutTime" BU_SG_REL_ H_U SG_ 1178 Byte0_TCP_49A 0;
BA_REL_ "GenSigTimeoutTime" BU_SG_REL_ H_U SG_ 1178 Byte1_Data_49A 0;
BA_REL_ "GenSigTimeoutTime" BU_SG_REL_ H_U SG_ 1178 Byte2_Data_49A 0;
BA_REL_ "GenSigTimeoutTime" BU_SG_REL_ H_U SG_ 1178 Byte3_Data_49A 0;
BA_REL_ "GenSigTimeoutTime" BU_SG_REL_ H_U SG_ 1178 Byte4_Data_49A 0;
BA_REL_ "GenSigTimeoutTime" BU_SG_REL_ H_U SG_ 1178 Byte5_Data_49A 0;
BA_REL_ "GenSigTimeoutTime" BU_SG_REL_ H_U SG_ 1178 Byte6_Data_49A 0;
BA_REL_ "GenSigTimeoutTime" BU_SG_REL_ H_U SG_ 1178 Byte7_Data_49A 0;
BA_REL_ "GenSigTimeoutTime" BU_SG_REL_ H_U SG_ 1176 Byte0_TCP_498 0;
BA_REL_ "GenSigTimeoutTime" BU_SG_REL_ H_U SG_ 1176 Byte1_Data_498 0;
BA_REL_ "GenSigTimeoutTime" BU_SG_REL_ H_U SG_ 1176 Byte2_Data_498 0;
BA_REL_ "GenSigTimeoutTime" BU_SG_REL_ H_U SG_ 1176 Byte3_Data_498 0;
BA_REL_ "GenSigTimeoutTime" BU_SG_REL_ H_U SG_ 1176 Byte4_Data_498 0;
BA_REL_ "GenSigTimeoutTime" BU_SG_REL_ H_U SG_ 1176 Byte5_Data_498 0;
BA_REL_ "GenSigTimeoutTime" BU_SG_REL_ H_U SG_ 1176 Byte6_Data_498 0;
BA_REL_ "GenSigTimeoutTime" BU_SG_REL_ H_U SG_ 1176 Byte7_Data_498 0;
BA_REL_ "GenSigTimeoutTime" BU_SG_REL_ H_U SG_ 1175 Byte0_TCP_497 0;
BA_REL_ "GenSigTimeoutTime" BU_SG_REL_ H_U SG_ 1175 Byte1_Data_497 0;
BA_REL_ "GenSigTimeoutTime" BU_SG_REL_ H_U SG_ 1175 Byte2_Data_497 0;
BA_REL_ "GenSigTimeoutTime" BU_SG_REL_ H_U SG_ 1175 Byte3_Data_497 0;
BA_REL_ "GenSigTimeoutTime" BU_SG_REL_ H_U SG_ 1175 Byte4_Data_497 0;
BA_REL_ "GenSigTimeoutTime" BU_SG_REL_ H_U SG_ 1175 Byte5_Data_497 0;
BA_REL_ "GenSigTimeoutTime" BU_SG_REL_ H_U SG_ 1175 Byte6_Data_497 0;
BA_REL_ "GenSigTimeoutTime" BU_SG_REL_ H_U SG_ 1175 Byte7_Data_497 0;
BA_REL_ "GenSigTimeoutTime" BU_SG_REL_ CLU SG_ 407 HU_LanguageInfo 3500;
BA_REL_ "GenSigTimeoutTime" BU_SG_REL_ HUD SG_ 407 HU_LanguageInfo 3500;
BA_REL_ "GenSigTimeoutTime" BU_SG_REL_ CLU SG_ 407 HU_MuteStatus 3500;
BA_REL_ "GenSigTimeoutTime" BU_SG_REL_ HUD SG_ 407 HU_MuteStatus 3500;
BA_REL_ "GenSigTimeoutTime" BU_SG_REL_ CLU SG_ 407 HU_VolumeStatus 3500;
BA_REL_ "GenSigTimeoutTime" BU_SG_REL_ HUD SG_ 407 HU_VolumeStatus 3500;
BA_REL_ "GenSigTimeoutTime" BU_SG_REL_ CLU SG_ 407 HU_NaviDisp 3500;
BA_REL_ "GenSigTimeoutTime" BU_SG_REL_ HUD SG_ 407 HU_NaviDisp 3500;
BA_REL_ "GenSigTimeoutTime" BU_SG_REL_ CGW SG_ 407 HU_NaviStatus 3500;
BA_REL_ "GenSigTimeoutTime" BU_SG_REL_ CLU SG_ 407 HU_NaviStatus 3500;
BA_REL_ "GenSigTimeoutTime" BU_SG_REL_ HUD SG_ 407 HU_NaviStatus 3500;
BA_REL_ "GenSigTimeoutTime" BU_SG_REL_ IPM SG_ 407 HU_NaviStatus 3500;
BA_REL_ "GenSigTimeoutTime" BU_SG_REL_ CLU SG_ 407 HU_DistanceUnit 3500;
BA_REL_ "GenSigTimeoutTime" BU_SG_REL_ HUD SG_ 407 HU_DistanceUnit 3500;
BA_REL_ "GenSigTimeoutTime" BU_SG_REL_ AVM SG_ 407 HU_Navigation_On_Off 3500;
BA_REL_ "GenSigTimeoutTime" BU_SG_REL_ CGW SG_ 407 HU_Navigation_On_Off 3500;
BA_REL_ "GenSigTimeoutTime" BU_SG_REL_ CLU SG_ 407 HU_Navigation_On_Off 3500;
BA_REL_ "GenSigTimeoutTime" BU_SG_REL_ DATC SG_ 407 HU_Navigation_On_Off 3500;
BA_REL_ "GenSigTimeoutTime" BU_SG_REL_ HUD SG_ 407 HU_Navigation_On_Off 3500;
BA_REL_ "GenSigTimeoutTime" BU_SG_REL_ IPM SG_ 407 HU_Navigation_On_Off 3500;
BA_REL_ "GenSigTimeoutTime" BU_SG_REL_ H_U SG_ 1942 Byte0_TCP_796 0;
BA_REL_ "GenSigTimeoutTime" BU_SG_REL_ H_U SG_ 1942 Byte1_Data_796 0;
BA_REL_ "GenSigTimeoutTime" BU_SG_REL_ H_U SG_ 1942 Byte2_Data_796 0;
BA_REL_ "GenSigTimeoutTime" BU_SG_REL_ H_U SG_ 1942 Byte3_Data_796 0;
BA_REL_ "GenSigTimeoutTime" BU_SG_REL_ H_U SG_ 1942 Byte4_Data_796 0;
BA_REL_ "GenSigTimeoutTime" BU_SG_REL_ H_U SG_ 1942 Byte5_Data_796 0;
BA_REL_ "GenSigTimeoutTime" BU_SG_REL_ H_U SG_ 1942 Byte6_Data_796 0;
BA_REL_ "GenSigTimeoutTime" BU_SG_REL_ H_U SG_ 1942 Byte7_Data_796 0;
BA_REL_ "GenSigTimeoutTime" BU_SG_REL_ AMP SG_ 1941 Byte0_TCP_795 0;
BA_REL_ "GenSigTimeoutTime" BU_SG_REL_ AMP SG_ 1941 Byte1_Data_795 0;
BA_REL_ "GenSigTimeoutTime" BU_SG_REL_ AMP SG_ 1941 Byte2_Data_795 0;
BA_REL_ "GenSigTimeoutTime" BU_SG_REL_ AMP SG_ 1941 Byte3_Data_795 0;
BA_REL_ "GenSigTimeoutTime" BU_SG_REL_ AMP SG_ 1941 Byte4_Data_795 0;
BA_REL_ "GenSigTimeoutTime" BU_SG_REL_ AMP SG_ 1941 Byte5_Data_795 0;
BA_REL_ "GenSigTimeoutTime" BU_SG_REL_ AMP SG_ 1941 Byte6_Data_795 0;
BA_REL_ "GenSigTimeoutTime" BU_SG_REL_ AMP SG_ 1941 Byte7_Data_795 0;
BA_REL_ "GenSigTimeoutTime" BU_SG_REL_ H_U SG_ 1173 Byte0_TCP_495 0;
BA_REL_ "GenSigTimeoutTime" BU_SG_REL_ H_U SG_ 1173 Byte1_Data_495 0;
BA_REL_ "GenSigTimeoutTime" BU_SG_REL_ H_U SG_ 1173 Byte2_Data_495 0;
BA_REL_ "GenSigTimeoutTime" BU_SG_REL_ H_U SG_ 1173 Byte3_Data_495 0;
BA_REL_ "GenSigTimeoutTime" BU_SG_REL_ H_U SG_ 1173 Byte4_Data_495 0;
BA_REL_ "GenSigTimeoutTime" BU_SG_REL_ H_U SG_ 1173 Byte5_Data_495 0;
BA_REL_ "GenSigTimeoutTime" BU_SG_REL_ H_U SG_ 1173 Byte6_Data_495 0;
BA_REL_ "GenSigTimeoutTime" BU_SG_REL_ H_U SG_ 1173 Byte7_Data_495 0;
BA_REL_ "GenSigTimeoutTime" BU_SG_REL_ CLU SG_ 1168 Byte0_TCP_490 0;
BA_REL_ "GenSigTimeoutTime" BU_SG_REL_ CLU SG_ 1168 Byte1_Data_490 0;
BA_REL_ "GenSigTimeoutTime" BU_SG_REL_ CLU SG_ 1168 Byte2_Data_490 0;
BA_REL_ "GenSigTimeoutTime" BU_SG_REL_ CLU SG_ 1168 Byte3_Data_490 0;
BA_REL_ "GenSigTimeoutTime" BU_SG_REL_ CLU SG_ 1168 Byte4_Data_490 0;
BA_REL_ "GenSigTimeoutTime" BU_SG_REL_ CLU SG_ 1168 Byte5_Data_490 0;
BA_REL_ "GenSigTimeoutTime" BU_SG_REL_ CLU SG_ 1168 Byte6_Data_490 0;
BA_REL_ "GenSigTimeoutTime" BU_SG_REL_ CLU SG_ 1168 Byte7_Data_490 0;
BA_REL_ "GenSigTimeoutTime" BU_SG_REL_ AMP SG_ 1936 Byte0_TCP_790 0;
BA_REL_ "GenSigTimeoutTime" BU_SG_REL_ ASD SG_ 1936 Byte0_TCP_790 0;
BA_REL_ "GenSigTimeoutTime" BU_SG_REL_ AVM SG_ 1936 Byte0_TCP_790 0;
BA_REL_ "GenSigTimeoutTime" BU_SG_REL_ CCP SG_ 1936 Byte0_TCP_790 0;
BA_REL_ "GenSigTimeoutTime" BU_SG_REL_ CGW SG_ 1936 Byte0_TCP_790 0;
BA_REL_ "GenSigTimeoutTime" BU_SG_REL_ CLOCK SG_ 1936 Byte0_TCP_790 0;
BA_REL_ "GenSigTimeoutTime" BU_SG_REL_ CLU SG_ 1936 Byte0_TCP_790 0;
BA_REL_ "GenSigTimeoutTime" BU_SG_REL_ CUBIS SG_ 1936 Byte0_TCP_790 0;
BA_REL_ "GenSigTimeoutTime" BU_SG_REL_ DATC SG_ 1936 Byte0_TCP_790 0;
BA_REL_ "GenSigTimeoutTime" BU_SG_REL_ EDT SG_ 1936 Byte0_TCP_790 0;
BA_REL_ "GenSigTimeoutTime" BU_SG_REL_ FHCU SG_ 1936 Byte0_TCP_790 0;
BA_REL_ "GenSigTimeoutTime" BU_SG_REL_ HUD SG_ 1936 Byte0_TCP_790 0;
BA_REL_ "GenSigTimeoutTime" BU_SG_REL_ IBOX SG_ 1936 Byte0_TCP_790 0;
BA_REL_ "GenSigTimeoutTime" BU_SG_REL_ IPM SG_ 1936 Byte0_TCP_790 0;
BA_REL_ "GenSigTimeoutTime" BU_SG_REL_ KBD SG_ 1936 Byte0_TCP_790 0;
BA_REL_ "GenSigTimeoutTime" BU_SG_REL_ KMA_TMU SG_ 1936 Byte0_TCP_790 0;
BA_REL_ "GenSigTimeoutTime" BU_SG_REL_ MON SG_ 1936 Byte0_TCP_790 0;
BA_REL_ "GenSigTimeoutTime" BU_SG_REL_ RRC SG_ 1936 Byte0_TCP_790 0;
BA_REL_ "GenSigTimeoutTime" BU_SG_REL_ RSE_L SG_ 1936 Byte0_TCP_790 0;
BA_REL_ "GenSigTimeoutTime" BU_SG_REL_ RSE_R SG_ 1936 Byte0_TCP_790 0;
BA_REL_ "GenSigTimeoutTime" BU_SG_REL_ SWRC SG_ 1936 Byte0_TCP_790 0;
BA_REL_ "GenSigTimeoutTime" BU_SG_REL_ TMU SG_ 1936 Byte0_TCP_790 0;
BA_REL_ "GenSigTimeoutTime" BU_SG_REL_ AMP SG_ 1936 Byte1_Data_790 0;
BA_REL_ "GenSigTimeoutTime" BU_SG_REL_ ASD SG_ 1936 Byte1_Data_790 0;
BA_REL_ "GenSigTimeoutTime" BU_SG_REL_ AVM SG_ 1936 Byte1_Data_790 0;
BA_REL_ "GenSigTimeoutTime" BU_SG_REL_ CCP SG_ 1936 Byte1_Data_790 0;
BA_REL_ "GenSigTimeoutTime" BU_SG_REL_ CGW SG_ 1936 Byte1_Data_790 0;
BA_REL_ "GenSigTimeoutTime" BU_SG_REL_ CLOCK SG_ 1936 Byte1_Data_790 0;
BA_REL_ "GenSigTimeoutTime" BU_SG_REL_ CLU SG_ 1936 Byte1_Data_790 0;
BA_REL_ "GenSigTimeoutTime" BU_SG_REL_ CUBIS SG_ 1936 Byte1_Data_790 0;
BA_REL_ "GenSigTimeoutTime" BU_SG_REL_ DATC SG_ 1936 Byte1_Data_790 0;
BA_REL_ "GenSigTimeoutTime" BU_SG_REL_ EDT SG_ 1936 Byte1_Data_790 0;
BA_REL_ "GenSigTimeoutTime" BU_SG_REL_ FHCU SG_ 1936 Byte1_Data_790 0;
BA_REL_ "GenSigTimeoutTime" BU_SG_REL_ HUD SG_ 1936 Byte1_Data_790 0;
BA_REL_ "GenSigTimeoutTime" BU_SG_REL_ IBOX SG_ 1936 Byte1_Data_790 0;
BA_REL_ "GenSigTimeoutTime" BU_SG_REL_ IPM SG_ 1936 Byte1_Data_790 0;
BA_REL_ "GenSigTimeoutTime" BU_SG_REL_ KBD SG_ 1936 Byte1_Data_790 0;
BA_REL_ "GenSigTimeoutTime" BU_SG_REL_ KMA_TMU SG_ 1936 Byte1_Data_790 0;
BA_REL_ "GenSigTimeoutTime" BU_SG_REL_ MON SG_ 1936 Byte1_Data_790 0;
BA_REL_ "GenSigTimeoutTime" BU_SG_REL_ RRC SG_ 1936 Byte1_Data_790 0;
BA_REL_ "GenSigTimeoutTime" BU_SG_REL_ RSE_L SG_ 1936 Byte1_Data_790 0;
BA_REL_ "GenSigTimeoutTime" BU_SG_REL_ RSE_R SG_ 1936 Byte1_Data_790 0;
BA_REL_ "GenSigTimeoutTime" BU_SG_REL_ SWRC SG_ 1936 Byte1_Data_790 0;
BA_REL_ "GenSigTimeoutTime" BU_SG_REL_ TMU SG_ 1936 Byte1_Data_790 0;
BA_REL_ "GenSigTimeoutTime" BU_SG_REL_ AMP SG_ 1936 Byte2_Data_790 0;
BA_REL_ "GenSigTimeoutTime" BU_SG_REL_ ASD SG_ 1936 Byte2_Data_790 0;
BA_REL_ "GenSigTimeoutTime" BU_SG_REL_ AVM SG_ 1936 Byte2_Data_790 0;
BA_REL_ "GenSigTimeoutTime" BU_SG_REL_ CCP SG_ 1936 Byte2_Data_790 0;
BA_REL_ "GenSigTimeoutTime" BU_SG_REL_ CGW SG_ 1936 Byte2_Data_790 0;
BA_REL_ "GenSigTimeoutTime" BU_SG_REL_ CLOCK SG_ 1936 Byte2_Data_790 0;
BA_REL_ "GenSigTimeoutTime" BU_SG_REL_ CLU SG_ 1936 Byte2_Data_790 0;
BA_REL_ "GenSigTimeoutTime" BU_SG_REL_ CUBIS SG_ 1936 Byte2_Data_790 0;
BA_REL_ "GenSigTimeoutTime" BU_SG_REL_ DATC SG_ 1936 Byte2_Data_790 0;
BA_REL_ "GenSigTimeoutTime" BU_SG_REL_ EDT SG_ 1936 Byte2_Data_790 0;
BA_REL_ "GenSigTimeoutTime" BU_SG_REL_ FHCU SG_ 1936 Byte2_Data_790 0;
BA_REL_ "GenSigTimeoutTime" BU_SG_REL_ HUD SG_ 1936 Byte2_Data_790 0;
BA_REL_ "GenSigTimeoutTime" BU_SG_REL_ IBOX SG_ 1936 Byte2_Data_790 0;
BA_REL_ "GenSigTimeoutTime" BU_SG_REL_ IPM SG_ 1936 Byte2_Data_790 0;
BA_REL_ "GenSigTimeoutTime" BU_SG_REL_ KBD SG_ 1936 Byte2_Data_790 0;
BA_REL_ "GenSigTimeoutTime" BU_SG_REL_ KMA_TMU SG_ 1936 Byte2_Data_790 0;
BA_REL_ "GenSigTimeoutTime" BU_SG_REL_ MON SG_ 1936 Byte2_Data_790 0;
BA_REL_ "GenSigTimeoutTime" BU_SG_REL_ RRC SG_ 1936 Byte2_Data_790 0;
BA_REL_ "GenSigTimeoutTime" BU_SG_REL_ RSE_L SG_ 1936 Byte2_Data_790 0;
BA_REL_ "GenSigTimeoutTime" BU_SG_REL_ RSE_R SG_ 1936 Byte2_Data_790 0;
BA_REL_ "GenSigTimeoutTime" BU_SG_REL_ SWRC SG_ 1936 Byte2_Data_790 0;
BA_REL_ "GenSigTimeoutTime" BU_SG_REL_ TMU SG_ 1936 Byte2_Data_790 0;
BA_REL_ "GenSigTimeoutTime" BU_SG_REL_ AMP SG_ 1936 Byte3_Data_790 0;
BA_REL_ "GenSigTimeoutTime" BU_SG_REL_ ASD SG_ 1936 Byte3_Data_790 0;
BA_REL_ "GenSigTimeoutTime" BU_SG_REL_ AVM SG_ 1936 Byte3_Data_790 0;
BA_REL_ "GenSigTimeoutTime" BU_SG_REL_ CCP SG_ 1936 Byte3_Data_790 0;
BA_REL_ "GenSigTimeoutTime" BU_SG_REL_ CGW SG_ 1936 Byte3_Data_790 0;
BA_REL_ "GenSigTimeoutTime" BU_SG_REL_ CLOCK SG_ 1936 Byte3_Data_790 0;
BA_REL_ "GenSigTimeoutTime" BU_SG_REL_ CLU SG_ 1936 Byte3_Data_790 0;
BA_REL_ "GenSigTimeoutTime" BU_SG_REL_ CUBIS SG_ 1936 Byte3_Data_790 0;
BA_REL_ "GenSigTimeoutTime" BU_SG_REL_ DATC SG_ 1936 Byte3_Data_790 0;
BA_REL_ "GenSigTimeoutTime" BU_SG_REL_ EDT SG_ 1936 Byte3_Data_790 0;
BA_REL_ "GenSigTimeoutTime" BU_SG_REL_ FHCU SG_ 1936 Byte3_Data_790 0;
BA_REL_ "GenSigTimeoutTime" BU_SG_REL_ HUD SG_ 1936 Byte3_Data_790 0;
BA_REL_ "GenSigTimeoutTime" BU_SG_REL_ IBOX SG_ 1936 Byte3_Data_790 0;
BA_REL_ "GenSigTimeoutTime" BU_SG_REL_ IPM SG_ 1936 Byte3_Data_790 0;
BA_REL_ "GenSigTimeoutTime" BU_SG_REL_ KBD SG_ 1936 Byte3_Data_790 0;
BA_REL_ "GenSigTimeoutTime" BU_SG_REL_ KMA_TMU SG_ 1936 Byte3_Data_790 0;
BA_REL_ "GenSigTimeoutTime" BU_SG_REL_ MON SG_ 1936 Byte3_Data_790 0;
BA_REL_ "GenSigTimeoutTime" BU_SG_REL_ RRC SG_ 1936 Byte3_Data_790 0;
BA_REL_ "GenSigTimeoutTime" BU_SG_REL_ RSE_L SG_ 1936 Byte3_Data_790 0;
BA_REL_ "GenSigTimeoutTime" BU_SG_REL_ RSE_R SG_ 1936 Byte3_Data_790 0;
BA_REL_ "GenSigTimeoutTime" BU_SG_REL_ SWRC SG_ 1936 Byte3_Data_790 0;
BA_REL_ "GenSigTimeoutTime" BU_SG_REL_ TMU SG_ 1936 Byte3_Data_790 0;
BA_REL_ "GenSigTimeoutTime" BU_SG_REL_ AMP SG_ 1936 Byte4_Data_790 0;
BA_REL_ "GenSigTimeoutTime" BU_SG_REL_ ASD SG_ 1936 Byte4_Data_790 0;
BA_REL_ "GenSigTimeoutTime" BU_SG_REL_ AVM SG_ 1936 Byte4_Data_790 0;
BA_REL_ "GenSigTimeoutTime" BU_SG_REL_ CCP SG_ 1936 Byte4_Data_790 0;
BA_REL_ "GenSigTimeoutTime" BU_SG_REL_ CGW SG_ 1936 Byte4_Data_790 0;
BA_REL_ "GenSigTimeoutTime" BU_SG_REL_ CLOCK SG_ 1936 Byte4_Data_790 0;
BA_REL_ "GenSigTimeoutTime" BU_SG_REL_ CLU SG_ 1936 Byte4_Data_790 0;
BA_REL_ "GenSigTimeoutTime" BU_SG_REL_ CUBIS SG_ 1936 Byte4_Data_790 0;
BA_REL_ "GenSigTimeoutTime" BU_SG_REL_ DATC SG_ 1936 Byte4_Data_790 0;
BA_REL_ "GenSigTimeoutTime" BU_SG_REL_ EDT SG_ 1936 Byte4_Data_790 0;
BA_REL_ "GenSigTimeoutTime" BU_SG_REL_ FHCU SG_ 1936 Byte4_Data_790 0;
BA_REL_ "GenSigTimeoutTime" BU_SG_REL_ HUD SG_ 1936 Byte4_Data_790 0;
BA_REL_ "GenSigTimeoutTime" BU_SG_REL_ IBOX SG_ 1936 Byte4_Data_790 0;
BA_REL_ "GenSigTimeoutTime" BU_SG_REL_ IPM SG_ 1936 Byte4_Data_790 0;
BA_REL_ "GenSigTimeoutTime" BU_SG_REL_ KBD SG_ 1936 Byte4_Data_790 0;
BA_REL_ "GenSigTimeoutTime" BU_SG_REL_ KMA_TMU SG_ 1936 Byte4_Data_790 0;
BA_REL_ "GenSigTimeoutTime" BU_SG_REL_ MON SG_ 1936 Byte4_Data_790 0;
BA_REL_ "GenSigTimeoutTime" BU_SG_REL_ RRC SG_ 1936 Byte4_Data_790 0;
BA_REL_ "GenSigTimeoutTime" BU_SG_REL_ RSE_L SG_ 1936 Byte4_Data_790 0;
BA_REL_ "GenSigTimeoutTime" BU_SG_REL_ RSE_R SG_ 1936 Byte4_Data_790 0;
BA_REL_ "GenSigTimeoutTime" BU_SG_REL_ SWRC SG_ 1936 Byte4_Data_790 0;
BA_REL_ "GenSigTimeoutTime" BU_SG_REL_ TMU SG_ 1936 Byte4_Data_790 0;
BA_REL_ "GenSigTimeoutTime" BU_SG_REL_ AMP SG_ 1936 Byte5_Data_790 0;
BA_REL_ "GenSigTimeoutTime" BU_SG_REL_ ASD SG_ 1936 Byte5_Data_790 0;
BA_REL_ "GenSigTimeoutTime" BU_SG_REL_ AVM SG_ 1936 Byte5_Data_790 0;
BA_REL_ "GenSigTimeoutTime" BU_SG_REL_ CCP SG_ 1936 Byte5_Data_790 0;
BA_REL_ "GenSigTimeoutTime" BU_SG_REL_ CGW SG_ 1936 Byte5_Data_790 0;
BA_REL_ "GenSigTimeoutTime" BU_SG_REL_ CLOCK SG_ 1936 Byte5_Data_790 0;
BA_REL_ "GenSigTimeoutTime" BU_SG_REL_ CLU SG_ 1936 Byte5_Data_790 0;
BA_REL_ "GenSigTimeoutTime" BU_SG_REL_ CUBIS SG_ 1936 Byte5_Data_790 0;
BA_REL_ "GenSigTimeoutTime" BU_SG_REL_ DATC SG_ 1936 Byte5_Data_790 0;
BA_REL_ "GenSigTimeoutTime" BU_SG_REL_ EDT SG_ 1936 Byte5_Data_790 0;
BA_REL_ "GenSigTimeoutTime" BU_SG_REL_ FHCU SG_ 1936 Byte5_Data_790 0;
BA_REL_ "GenSigTimeoutTime" BU_SG_REL_ HUD SG_ 1936 Byte5_Data_790 0;
BA_REL_ "GenSigTimeoutTime" BU_SG_REL_ IBOX SG_ 1936 Byte5_Data_790 0;
BA_REL_ "GenSigTimeoutTime" BU_SG_REL_ IPM SG_ 1936 Byte5_Data_790 0;
BA_REL_ "GenSigTimeoutTime" BU_SG_REL_ KBD SG_ 1936 Byte5_Data_790 0;
BA_REL_ "GenSigTimeoutTime" BU_SG_REL_ KMA_TMU SG_ 1936 Byte5_Data_790 0;
BA_REL_ "GenSigTimeoutTime" BU_SG_REL_ MON SG_ 1936 Byte5_Data_790 0;
BA_REL_ "GenSigTimeoutTime" BU_SG_REL_ RRC SG_ 1936 Byte5_Data_790 0;
BA_REL_ "GenSigTimeoutTime" BU_SG_REL_ RSE_L SG_ 1936 Byte5_Data_790 0;
BA_REL_ "GenSigTimeoutTime" BU_SG_REL_ RSE_R SG_ 1936 Byte5_Data_790 0;
BA_REL_ "GenSigTimeoutTime" BU_SG_REL_ SWRC SG_ 1936 Byte5_Data_790 0;
BA_REL_ "GenSigTimeoutTime" BU_SG_REL_ TMU SG_ 1936 Byte5_Data_790 0;
BA_REL_ "GenSigTimeoutTime" BU_SG_REL_ AMP SG_ 1936 Byte6_Data_790 0;
BA_REL_ "GenSigTimeoutTime" BU_SG_REL_ ASD SG_ 1936 Byte6_Data_790 0;
BA_REL_ "GenSigTimeoutTime" BU_SG_REL_ AVM SG_ 1936 Byte6_Data_790 0;
BA_REL_ "GenSigTimeoutTime" BU_SG_REL_ CCP SG_ 1936 Byte6_Data_790 0;
BA_REL_ "GenSigTimeoutTime" BU_SG_REL_ CGW SG_ 1936 Byte6_Data_790 0;
BA_REL_ "GenSigTimeoutTime" BU_SG_REL_ CLOCK SG_ 1936 Byte6_Data_790 0;
BA_REL_ "GenSigTimeoutTime" BU_SG_REL_ CLU SG_ 1936 Byte6_Data_790 0;
BA_REL_ "GenSigTimeoutTime" BU_SG_REL_ CUBIS SG_ 1936 Byte6_Data_790 0;
BA_REL_ "GenSigTimeoutTime" BU_SG_REL_ DATC SG_ 1936 Byte6_Data_790 0;
BA_REL_ "GenSigTimeoutTime" BU_SG_REL_ EDT SG_ 1936 Byte6_Data_790 0;
BA_REL_ "GenSigTimeoutTime" BU_SG_REL_ FHCU SG_ 1936 Byte6_Data_790 0;
BA_REL_ "GenSigTimeoutTime" BU_SG_REL_ HUD SG_ 1936 Byte6_Data_790 0;
BA_REL_ "GenSigTimeoutTime" BU_SG_REL_ IBOX SG_ 1936 Byte6_Data_790 0;
BA_REL_ "GenSigTimeoutTime" BU_SG_REL_ IPM SG_ 1936 Byte6_Data_790 0;
BA_REL_ "GenSigTimeoutTime" BU_SG_REL_ KBD SG_ 1936 Byte6_Data_790 0;
BA_REL_ "GenSigTimeoutTime" BU_SG_REL_ KMA_TMU SG_ 1936 Byte6_Data_790 0;
BA_REL_ "GenSigTimeoutTime" BU_SG_REL_ MON SG_ 1936 Byte6_Data_790 0;
BA_REL_ "GenSigTimeoutTime" BU_SG_REL_ RRC SG_ 1936 Byte6_Data_790 0;
BA_REL_ "GenSigTimeoutTime" BU_SG_REL_ RSE_L SG_ 1936 Byte6_Data_790 0;
BA_REL_ "GenSigTimeoutTime" BU_SG_REL_ RSE_R SG_ 1936 Byte6_Data_790 0;
BA_REL_ "GenSigTimeoutTime" BU_SG_REL_ SWRC SG_ 1936 Byte6_Data_790 0;
BA_REL_ "GenSigTimeoutTime" BU_SG_REL_ TMU SG_ 1936 Byte6_Data_790 0;
BA_REL_ "GenSigTimeoutTime" BU_SG_REL_ AMP SG_ 1936 Byte7_Data_790 0;
BA_REL_ "GenSigTimeoutTime" BU_SG_REL_ ASD SG_ 1936 Byte7_Data_790 0;
BA_REL_ "GenSigTimeoutTime" BU_SG_REL_ AVM SG_ 1936 Byte7_Data_790 0;
BA_REL_ "GenSigTimeoutTime" BU_SG_REL_ CCP SG_ 1936 Byte7_Data_790 0;
BA_REL_ "GenSigTimeoutTime" BU_SG_REL_ CGW SG_ 1936 Byte7_Data_790 0;
BA_REL_ "GenSigTimeoutTime" BU_SG_REL_ CLOCK SG_ 1936 Byte7_Data_790 0;
BA_REL_ "GenSigTimeoutTime" BU_SG_REL_ CLU SG_ 1936 Byte7_Data_790 0;
BA_REL_ "GenSigTimeoutTime" BU_SG_REL_ CUBIS SG_ 1936 Byte7_Data_790 0;
BA_REL_ "GenSigTimeoutTime" BU_SG_REL_ DATC SG_ 1936 Byte7_Data_790 0;
BA_REL_ "GenSigTimeoutTime" BU_SG_REL_ EDT SG_ 1936 Byte7_Data_790 0;
BA_REL_ "GenSigTimeoutTime" BU_SG_REL_ FHCU SG_ 1936 Byte7_Data_790 0;
BA_REL_ "GenSigTimeoutTime" BU_SG_REL_ HUD SG_ 1936 Byte7_Data_790 0;
BA_REL_ "GenSigTimeoutTime" BU_SG_REL_ IBOX SG_ 1936 Byte7_Data_790 0;
BA_REL_ "GenSigTimeoutTime" BU_SG_REL_ IPM SG_ 1936 Byte7_Data_790 0;
BA_REL_ "GenSigTimeoutTime" BU_SG_REL_ KBD SG_ 1936 Byte7_Data_790 0;
BA_REL_ "GenSigTimeoutTime" BU_SG_REL_ KMA_TMU SG_ 1936 Byte7_Data_790 0;
BA_REL_ "GenSigTimeoutTime" BU_SG_REL_ MON SG_ 1936 Byte7_Data_790 0;
BA_REL_ "GenSigTimeoutTime" BU_SG_REL_ RRC SG_ 1936 Byte7_Data_790 0;
BA_REL_ "GenSigTimeoutTime" BU_SG_REL_ RSE_L SG_ 1936 Byte7_Data_790 0;
BA_REL_ "GenSigTimeoutTime" BU_SG_REL_ RSE_R SG_ 1936 Byte7_Data_790 0;
BA_REL_ "GenSigTimeoutTime" BU_SG_REL_ SWRC SG_ 1936 Byte7_Data_790 0;
BA_REL_ "GenSigTimeoutTime" BU_SG_REL_ TMU SG_ 1936 Byte7_Data_790 0;
BA_REL_ "GenSigTimeoutTime" BU_SG_REL_ CLU SG_ 1167 Byte0_TCP_48F 0;
BA_REL_ "GenSigTimeoutTime" BU_SG_REL_ CLU SG_ 1167 Byte1_Data_48F 0;
BA_REL_ "GenSigTimeoutTime" BU_SG_REL_ CLU SG_ 1167 Byte2_Data_48F 0;
BA_REL_ "GenSigTimeoutTime" BU_SG_REL_ CLU SG_ 1167 Byte3_Data_48F 0;
BA_REL_ "GenSigTimeoutTime" BU_SG_REL_ CLU SG_ 1167 Byte4_Data_48F 0;
BA_REL_ "GenSigTimeoutTime" BU_SG_REL_ CLU SG_ 1167 Byte5_Data_48F 0;
BA_REL_ "GenSigTimeoutTime" BU_SG_REL_ CLU SG_ 1167 Byte6_Data_48F 0;
BA_REL_ "GenSigTimeoutTime" BU_SG_REL_ CLU SG_ 1167 Byte7_Data_48F 0;
BA_REL_ "GenSigTimeoutTime" BU_SG_REL_ CLU SG_ 1166 Byte0_TCP_48E 0;
BA_REL_ "GenSigTimeoutTime" BU_SG_REL_ CLU SG_ 1166 Byte1_Data_48E 0;
BA_REL_ "GenSigTimeoutTime" BU_SG_REL_ CLU SG_ 1166 Byte2_Data_48E 0;
BA_REL_ "GenSigTimeoutTime" BU_SG_REL_ CLU SG_ 1166 Byte3_Data_48E 0;
BA_REL_ "GenSigTimeoutTime" BU_SG_REL_ CLU SG_ 1166 Byte4_Data_48E 0;
BA_REL_ "GenSigTimeoutTime" BU_SG_REL_ CLU SG_ 1166 Byte5_Data_48E 0;
BA_REL_ "GenSigTimeoutTime" BU_SG_REL_ CLU SG_ 1166 Byte6_Data_48E 0;
BA_REL_ "GenSigTimeoutTime" BU_SG_REL_ CLU SG_ 1166 Byte7_Data_48E 0;
BA_REL_ "GenSigTimeoutTime" BU_SG_REL_ CLU SG_ 1165 Byte0_TCP_48D 0;
BA_REL_ "GenSigTimeoutTime" BU_SG_REL_ CLU SG_ 1165 Byte1_Data_48D 0;
BA_REL_ "GenSigTimeoutTime" BU_SG_REL_ CLU SG_ 1165 Byte2_Data_48D 0;
BA_REL_ "GenSigTimeoutTime" BU_SG_REL_ CLU SG_ 1165 Byte3_Data_48D 0;
BA_REL_ "GenSigTimeoutTime" BU_SG_REL_ CLU SG_ 1165 Byte4_Data_48D 0;
BA_REL_ "GenSigTimeoutTime" BU_SG_REL_ CLU SG_ 1165 Byte5_Data_48D 0;
BA_REL_ "GenSigTimeoutTime" BU_SG_REL_ CLU SG_ 1165 Byte6_Data_48D 0;
BA_REL_ "GenSigTimeoutTime" BU_SG_REL_ CLU SG_ 1165 Byte7_Data_48D 0;
BA_REL_ "GenSigTimeoutTime" BU_SG_REL_ H_U SG_ 1164 Byte0_TCP_48C 0;
BA_REL_ "GenSigTimeoutTime" BU_SG_REL_ H_U SG_ 1164 Byte1_Data_48C 0;
BA_REL_ "GenSigTimeoutTime" BU_SG_REL_ H_U SG_ 1164 Byte2_Data_48C 0;
BA_REL_ "GenSigTimeoutTime" BU_SG_REL_ H_U SG_ 1164 Byte3_Data_48C 0;
BA_REL_ "GenSigTimeoutTime" BU_SG_REL_ H_U SG_ 1164 Byte4_Data_48C 0;
BA_REL_ "GenSigTimeoutTime" BU_SG_REL_ H_U SG_ 1164 Byte5_Data_48C 0;
BA_REL_ "GenSigTimeoutTime" BU_SG_REL_ H_U SG_ 1164 Byte6_Data_48C 0;
BA_REL_ "GenSigTimeoutTime" BU_SG_REL_ H_U SG_ 1164 Byte7_Data_48C 0;
VAL_ 3221225472 C_WHEEL_FL 4095 "Error" ;
VAL_ 3221225472 C_WHEEL_FR 4095 "Error" ;
VAL_ 3221225472 C_WHEEL_RL 4095 "Error" ;
VAL_ 3221225472 C_WHEEL_RR 4095 "Error" ;
VAL_ 251 HU_GPS_Year 0 "2000~2099 year" 1 "2000~2099 year" 2 "2000~2099 year" 3 "2000~2099 year" 4 "2000~2099 year" 5 "2000~2099 year" 6 "2000~2099 year" 7 "2000~2099 year" 8 "2000~2099 year" 9 "2000~2099 year" 10 "2000~2099 year" 11 "2000~2099 year" 12 "2000~2099 year" 13 "2000~2099 year" 14 "2000~2099 year" 15 "2000~2099 year" 16 "2000~2099 year" 17 "2000~2099 year" 18 "2000~2099 year" 19 "2000~2099 year" 20 "2000~2099 year" 21 "2000~2099 year" 22 "2000~2099 year" 23 "2000~2099 year" 24 "2000~2099 year" 25 "2000~2099 year" 26 "2000~2099 year" 27 "2000~2099 year" 28 "2000~2099 year" 29 "2000~2099 year" 30 "2000~2099 year" 31 "2000~2099 year" 32 "2000~2099 year" 33 "2000~2099 year" 34 "2000~2099 year" 35 "2000~2099 year" 36 "2000~2099 year" 37 "2000~2099 year" 38 "2000~2099 year" 39 "2000~2099 year" 40 "2000~2099 year" 41 "2000~2099 year" 42 "2000~2099 year" 43 "2000~2099 year" 44 "2000~2099 year" 45 "2000~2099 year" 46 "2000~2099 year" 47 "2000~2099 year" 48 "2000~2099 year" 49 "2000~2099 year" 50 "2000~2099 year" 51 "2000~2099 year" 52 "2000~2099 year" 53 "2000~2099 year" 54 "2000~2099 year" 55 "2000~2099 year" 56 "2000~2099 year" 57 "2000~2099 year" 58 "2000~2099 year" 59 "2000~2099 year" 60 "2000~2099 year" 61 "2000~2099 year" 62 "2000~2099 year" 63 "2000~2099 year" 64 "2000~2099 year" 65 "2000~2099 year" 66 "2000~2099 year" 67 "2000~2099 year" 68 "2000~2099 year" 69 "2000~2099 year" 70 "2000~2099 year" 71 "2000~2099 year" 72 "2000~2099 year" 73 "2000~2099 year" 74 "2000~2099 year" 75 "2000~2099 year" 76 "2000~2099 year" 77 "2000~2099 year" 78 "2000~2099 year" 79 "2000~2099 year" 80 "2000~2099 year" 81 "2000~2099 year" 82 "2000~2099 year" 83 "2000~2099 year" 84 "2000~2099 year" 85 "2000~2099 year" 86 "2000~2099 year" 87 "2000~2099 year" 88 "2000~2099 year" 89 "2000~2099 year" 90 "2000~2099 year" 91 "2000~2099 year" 92 "2000~2099 year" 93 "2000~2099 year" 94 "2000~2099 year" 95 "2000~2099 year" 96 "2000~2099 year" 97 "2000~2099 year" 98 "2000~2099 year" 99 "2000~2099 year" 255 "Invalid" ;
VAL_ 251 HU_GPS_Month 1 "1~12 month" 2 "1~12 month" 3 "1~12 month" 4 "1~12 month" 5 "1~12 month" 6 "1~12 month" 7 "1~12 month" 8 "1~12 month" 9 "1~12 month" 10 "1~12 month" 11 "1~12 month" 12 "1~12 month" 255 "Invalid" ;
VAL_ 251 HU_GPS_Day 1 "1~31 day" 2 "1~31 day" 3 "1~31 day" 4 "1~31 day" 5 "1~31 day" 6 "1~31 day" 7 "1~31 day" 8 "1~31 day" 9 "1~31 day" 10 "1~31 day" 11 "1~31 day" 12 "1~31 day" 13 "1~31 day" 14 "1~31 day" 15 "1~31 day" 16 "1~31 day" 17 "1~31 day" 18 "1~31 day" 19 "1~31 day" 20 "1~31 day" 21 "1~31 day" 22 "1~31 day" 23 "1~31 day" 24 "1~31 day" 25 "1~31 day" 26 "1~31 day" 27 "1~31 day" 28 "1~31 day" 29 "1~31 day" 30 "1~31 day" 31 "1~31 day" 255 "Invalid" ;
VAL_ 251 HU_GPS_Hour 0 "0~23 hour" 1 "0~23 hour" 2 "0~23 hour" 3 "0~23 hour" 4 "0~23 hour" 5 "0~23 hour" 6 "0~23 hour" 7 "0~23 hour" 8 "0~23 hour" 9 "0~23 hour" 10 "0~23 hour" 11 "0~23 hour" 12 "0~23 hour" 13 "0~23 hour" 14 "0~23 hour" 15 "0~23 hour" 16 "0~23 hour" 17 "0~23 hour" 18 "0~23 hour" 19 "0~23 hour" 20 "0~23 hour" 21 "0~23 hour" 22 "0~23 hour" 23 "0~23 hour" 255 "Invalid" ;
VAL_ 251 HU_GPS_Minute 0 "0~59 minute" 1 "0~59 minute" 2 "0~59 minute" 3 "0~59 minute" 4 "0~59 minute" 5 "0~59 minute" 6 "0~59 minute" 7 "0~59 minute" 8 "0~59 minute" 9 "0~59 minute" 10 "0~59 minute" 11 "0~59 minute" 12 "0~59 minute" 13 "0~59 minute" 14 "0~59 minute" 15 "0~59 minute" 16 "0~59 minute" 17 "0~59 minute" 18 "0~59 minute" 19 "0~59 minute" 20 "0~59 minute" 21 "0~59 minute" 22 "0~59 minute" 23 "0~59 minute" 24 "0~59 minute" 25 "0~59 minute" 26 "0~59 minute" 27 "0~59 minute" 28 "0~59 minute" 29 "0~59 minute" 30 "0~59 minute" 31 "0~59 minute" 32 "0~59 minute" 33 "0~59 minute" 34 "0~59 minute" 35 "0~59 minute" 36 "0~59 minute" 37 "0~59 minute" 38 "0~59 minute" 39 "0~59 minute" 40 "0~59 minute" 41 "0~59 minute" 42 "0~59 minute" 43 "0~59 minute" 44 "0~59 minute" 45 "0~59 minute" 46 "0~59 minute" 47 "0~59 minute" 48 "0~59 minute" 49 "0~59 minute" 50 "0~59 minute" 51 "0~59 minute" 52 "0~59 minute" 53 "0~59 minute" 54 "0~59 minute" 55 "0~59 minute" 56 "0~59 minute" 57 "0~59 minute" 58 "0~59 minute" 59 "0~59 minute" 255 "Invalid" ;
VAL_ 251 HU_GPS_Second 0 "0~59 second" 1 "0~59 second" 2 "0~59 second" 3 "0~59 second" 4 "0~59 second" 5 "0~59 second" 6 "0~59 second" 7 "0~59 second" 8 "0~59 second" 9 "0~59 second" 10 "0~59 second" 11 "0~59 second" 12 "0~59 second" 13 "0~59 second" 14 "0~59 second" 15 "0~59 second" 16 "0~59 second" 17 "0~59 second" 18 "0~59 second" 19 "0~59 second" 20 "0~59 second" 21 "0~59 second" 22 "0~59 second" 23 "0~59 second" 24 "0~59 second" 25 "0~59 second" 26 "0~59 second" 27 "0~59 second" 28 "0~59 second" 29 "0~59 second" 30 "0~59 second" 31 "0~59 second" 32 "0~59 second" 33 "0~59 second" 34 "0~59 second" 35 "0~59 second" 36 "0~59 second" 37 "0~59 second" 38 "0~59 second" 39 "0~59 second" 40 "0~59 second" 41 "0~59 second" 42 "0~59 second" 43 "0~59 second" 44 "0~59 second" 45 "0~59 second" 46 "0~59 second" 47 "0~59 second" 48 "0~59 second" 49 "0~59 second" 50 "0~59 second" 51 "0~59 second" 52 "0~59 second" 53 "0~59 second" 54 "0~59 second" 55 "0~59 second" 56 "0~59 second" 57 "0~59 second" 58 "0~59 second" 59 "0~59 second" 255 "Invalid" ;
VAL_ 250 HU_VoiceRecCom 0 "No Command" 1 "Center CallVR Cmd(TBD)" 2 "Song Tag VR Comand(Not TBD)" 3 "EcoCoach VR Command" 4 "Help VR Command(Not TBD)" 5 "TMUs VR Cancel (Audio, AV Only)" 6 "Reserved" 7 "Invalid" ;
VAL_ 250 HU_LangChgCom 0 "No Action" 1 "English" 2 "French" 3 "Spanish" 4 "Chinese" 5 "Korean" 6 "Reserved" 7 "Invalid" ;
VAL_ 250 HU_CallEndCmd 0 "No Request" 1 "Call End" 2 "Reserved" 3 "Invalid" ;
VAL_ 250 HU_ServiceReqtID 0 "No Service" 1 "Automated DTC Service" 2 "Eco-Coach Service(Audio Only)" 3 "Song Tag Service" 4 "Reserved" 5 "Reserved" 6 "Reserved" 7 "Voice Text Request" 8 "Reserved" 9 "Reserved" 10 "Reserved" 11 "Reserved" 12 "Reserved" 13 "Reserved" 14 "Reserved" 15 "Invalid" ;
VAL_ 250 HU_MicReqCmd 0 "Mic No Request" 1 "Mic Request" 2 "Reserved" 3 "Invalid" ;
VAL_ 250 HU_SeviceAction 0 "No Request" 1 "Request Service" 2 "Cancel Service" 3 "Confirmation" 4 "Reserved" 5 "Reserved" 6 "Reserved" 7 "Invalid" ;
VAL_ 250 HU_eCallStatus 0 "HU normal mode" 1 "HU eCall mode" 2 "HU eCall Test mode" 3 "invalid" ;
VAL_ 491 C_DRVDoorStatus 0 "Close" 1 "Open" 2 "reserved" 3 "Invalid" ;
VAL_ 491 C_ASTDoorStatus 0 "Close" 1 "Open" 2 "reserved" 3 "Invalid" ;
VAL_ 491 C_RLDoorStatus 0 "Close" 1 "Open" 2 "reserved" 3 "Invalid" ;
VAL_ 491 C_RRDoorStatus 0 "Close" 1 "Open" 2 "reserved" 3 "Invalid" ;
VAL_ 491 C_TrunkStatus 0 "Closed" 1 "Opened" 2 "reserved" 3 "Invalid" ;
VAL_ 491 C_OSMirrorStatus 0 "Stop" 1 "Fold" 2 "Unfold" 3 "Invalid" ;
VAL_ 487 Navi_DistToPoint1_F 0 "0~9" 1 "0~9" 2 "0~9" 3 "0~9" 4 "0~9" 5 "0~9" 6 "0~9" 7 "0~9" 8 "0~9" 9 "0~9" 15 "Invalid" ;
VAL_ 487 Navi_DistToPoint1_I 4095 "Invalid" ;
VAL_ 487 Navi_DistToPoint1_U 0 "None" 1 "m" 2 "km" 3 "mi" 4 "ft" 15 "Invalid" ;
VAL_ 487 Navi_DistToPoint2_I 4095 "Invalid" ;
VAL_ 487 Navi_DistToPoint2_F 0 "0~9" 1 "0~9" 2 "0~9" 3 "0~9" 4 "0~9" 5 "0~9" 6 "0~9" 7 "0~9" 8 "0~9" 9 "0~9" 15 "Invalid" ;
VAL_ 487 Navi_DistToPoint2_U 0 "None" 1 "m" 2 "km" 3 "mi" 4 "ft" 15 "Invalid" ;
VAL_ 487 Navi_DistToPoint3_F 0 "0~9" 1 "0~9" 2 "0~9" 3 "0~9" 4 "0~9" 5 "0~9" 6 "0~9" 7 "0~9" 8 "0~9" 9 "0~9" 15 "Invalid" ;
VAL_ 487 Navi_DistToPoint3_I 4095 "Invalid" ;
VAL_ 487 Navi_DistToPoint3_U 0 "None" 1 "m" 2 "km" 3 "mi" 4 "ft" 15 "Invalid" ;
VAL_ 486 Navi_DistToDest_I 65535 "Invalid" ;
VAL_ 486 Navi_DistToDest_F 0 "0~9" 1 "0~9" 2 "0~9" 3 "0~9" 4 "0~9" 5 "0~9" 6 "0~9" 7 "0~9" 8 "0~9" 9 "0~9" 10 "Reserved" 11 "Reserved" 12 "Reserved" 13 "Reserved" 14 "Reserved" 15 "Invalid" ;
VAL_ 486 Navi_DistToDest_U 0 "None" 1 "m" 2 "km" 3 "mi" 4 "ft" 15 "Invalid" ;
VAL_ 486 Navi_EstimHour 255 "Invalid" ;
VAL_ 486 Navi_EstimMin 63 "Invalid" ;
VAL_ 486 Navi_EstimTimeType 0 "None" 1 "Estimate Time of Arrival" 2 "Necessary Time" 3 "Invalid" ;
VAL_ 486 Navi_Compass 0 "Off" 63 "Invalid" ;
VAL_ 229 SYS_SW_Ver_Req 0 "Off" 1 "Version Req" 2 "reserved" 3 "Invalid" ;
VAL_ 229 SYS_CAN_Ver_Req 0 "Off" 1 "Version Req" 2 "reserved" 3 "Invalid" ;
VAL_ 229 SYS_HW_Ver_Req 0 "Off" 1 "Version Req" 2 "reserved" 3 "Invalid" ;
VAL_ 229 SYS_RBD_Req 0 "Off" 1 "RBD Req" 2 "reserved" 3 "Invalid" ;
VAL_ 229 SYS_MOSTErrorDiag_Req 0 "Off" 1 "MOSTErrorDiag Req" 2 "reserved" 3 "Invalid" ;
VAL_ 229 SYS_Reset_Req 0 "Off" 1 "Reset Req" 2 "reserved" 3 "Invalid" ;
VAL_ 485 Navi_FixedSpdTrap 0 "None" 1 "10~110" 2 "10~110" 3 "10~110" 4 "10~110" 5 "10~110" 6 "10~110" 7 "10~110" 8 "10~110" 9 "10~110" 10 "10~110" 11 "10~110" 12 "reserved" 13 "reserved" 14 "reserved" 15 "Invalid" ;
VAL_ 485 Navi_MobileSpdTrap 0 "None" 1 "10~110" 2 "10~110" 3 "10~110" 4 "10~110" 5 "10~110" 6 "10~110" 7 "10~110" 8 "10~110" 9 "10~110" 10 "10~110" 11 "10~110" 12 "reserved" 13 "reserved" 14 "reserved" 15 "Invalid" ;
VAL_ 485 Navi_OverSpdAlarm 0 "None" 1 "Alarm" 2 "reserved" 3 "Invalid" ;
VAL_ 485 Navi_SpdRedlightTrap 0 "None" 1 "10~110" 2 "10~110" 3 "10~110" 4 "10~110" 5 "10~110" 6 "10~110" 7 "10~110" 8 "10~110" 9 "10~110" 10 "10~110" 11 "10~110" 12 "reserved" 13 "reserved" 14 "reserved" 15 "Invalid" ;
VAL_ 485 Navi_NonSpdTrap 0 "None" 1 "Red Light Trap" 2 "Bus Only Trap" 3 "Cut In Trap" 4 "Parking_Stopping Trap" 5 "Overloaded Trap" 6 "Badloaded Trap" 7 "Shoulder Trap" 8 "Plate Recogn. Camera" 9 "Traffic Camera" 10 "Intersection Block Trap" 11 "Ramp Metering Trap" 12 "User Registered Camera" 13 "Others" 31 "Invalid" ;
VAL_ 485 Navi_WarningZone 0 "None" 1 "Black Spot" 2 "School Zone" 3 "Falling Rocks" 4 "Railway Crossing" 5 "Foggy Area" 6 "Downhill" 7 "Roadkill" 8 "Speed Bump" 9 "Bottleneck" 10 "Under Construction" 15 "Invalid" ;
VAL_ 485 Navi_MergeWarning 0 "None" 1 "Right Merge" 2 "Left Merge" 3 "Invalid" ;
VAL_ 485 Navi_CurveWarning 0 "None" 1 "Right" 2 "Left" 3 "Right Curve Continuously" 4 "Left Curve Continuously" 5 "Curve Continuously" 6 "Reserved" 7 "Reserved" 8 "Reserved" 9 "Reserved" 10 "Reserved" 11 "Reserved" 12 "Reserved" 13 "Reserved" 14 "Reserved" 15 "Invalid" ;
VAL_ 485 Navi_BusSpdTrap 0 "None" 1 "10~110" 2 "10~110" 3 "10~110" 4 "10~110" 5 "10~110" 6 "10~110" 7 "10~110" 8 "10~110" 9 "10~110" 10 "10~110" 11 "10~110" 12 "reserved" 13 "reserved" 14 "reserved" 15 "Invalid" ;
VAL_ 485 Navi_SpdLimit_Type 0 "None" 1 "US" 2 "Canada" 3 "Invalid" ;
VAL_ 485 Navi_SpdLimit_Unit 0 "None" 1 "Kilometer" 2 "Mile" 3 "Invalid" ;
VAL_ 485 Navi_SpdInfo_Type 0 "Off" 1 "FixedSpeedTrap" 2 "FixedSpeedTrapNoInfo" 3 "MobileSpeedTrap" 4 "MobileSpeedTrapNoInfo" 5 "SpeedRedlightTrap" 6 "SpeedRedlightTrapNoInfo" 7 "BusSpeedTrap" 8 "BusSpeedTrapNoInfo" 9 "SpeedLimitType1" 10 "SpeedLimitSchoolzoneType1" 11 "SpeedLimitType2" 12 "SpeedLimitSchoolzoneType2" 15 "Invalid" ;
VAL_ 485 Navi_SpdLimit 0 "None" 255 "Invalid" ;
VAL_ 479 CLU_Type 3 "Invalid" ;
VAL_ 479 CLU_Region 3 "Invalid" ;
VAL_ 479 CLU_VersionMinor 3 "Invalid" ;
VAL_ 479 CLU_VersionMajor 3 "Invalid" ;
VAL_ 479 CLU_CurrentDispState 3 "Invalid" ;
VAL_ 479 C_DRVDRSW 0 "Close" 1 "Open" 2 "Reserved" 3 "Invalid" ;
VAL_ 479 CF_Clu_LowfuelWarning 0 "Off" 1 "LowFuelWarning" 2 "Not used" 3 "Invaild" ;
VAL_ 479 CLU_PowerInfo 0 "Off" 1 "IGN" 2 "reserved" 3 "Invalid" ;
VAL_ 479 C_DrivingModeState 0 "Default" 1 "Normal" 2 "Sport" 3 "ECO" 4 "Snow" 5 "Comfort" 6 "Reserved" 7 "Invalid" ;
VAL_ 479 Clu_RheostatLvl 0 "reserved" 1 "Step 1" 2 "Step 2" 3 "Step 3" 4 "Step 4" 5 "Step 5" 6 "Step 6" 7 "Step 7" 8 "Step 8" 9 "Step 9" 10 "Step 10" 11 "Step 11" 12 "Step 12" 13 "Step 13" 14 "Step 14" 15 "Step 15" 16 "Step 16" 17 "Step 17" 18 "Step 18" 19 "Step 19" 20 "Step 20(Reset Value)" 21 "Step 21 (Detent)" 31 "Invalid" ;
VAL_ 479 C_Clu_ActiveEcoSW 0 "Default" 1 "Off" 2 "On" 3 "Invalid" ;
VAL_ 479 C_Detent 0 "Off" 1 "Detent" 2 "reserved" 3 "Invalid" ;
VAL_ 479 C_DrivingModeOn 0 "Off" 1 "Dsiplay On" 2 "Reserved" 3 "Invalid" ;
VAL_ 474 CF_Clu_AvgFCU 0 "km_l" 1 "L_100km" 2 "MPG(US)" 3 "MPG(UK)" ;
VAL_ 474 CF_Clu_AvgFCL 1023 "Error (&apos;-.-&apos; Display)" ;
VAL_ 474 CF_Clu_TermAvgSync 0 "During the first 2.5 minutes" 1 "During another 2.5 minutes" 2 "During another 2.5 minutes" 3 "During another 2.5 minutes" ;
VAL_ 474 CF_Clu_EcoDriveInf 0 "Not Activated" 1 "Green Lamp" 2 "Yellow Lamp On" 3 "Red Lamp On" 4 "Reserved" 5 "Reserved" 6 "Reserved" 7 "Error" ;
VAL_ 474 CR_Clu_TermAvgFCI 1023 "Error (&apos;-.-&apos; Display)" ;
VAL_ 474 CF_CLU_EcoScore 65535 "Invalid" ;
VAL_ 1495 Clu_TripUnit 0 "km" 1 "mile" 2 "reserved" 3 "Invalid" ;
VAL_ 1495 Clu_DTEWarn 0 "Off" 1 "DTE Warning" 2 "reserved" 3 "Invalid" ;
VAL_ 1495 Clu_DTE 4095 "Error" ;
VAL_ 1495 Clu_AFC 1023 "Error" ;
VAL_ 1495 Clu_IFC 1023 "Error" ;
VAL_ 1495 Clu_Odometer 16777215 "Error" ;
VAL_ 1494 CF_TripUnit 0 "Not Used" 1 "km" 2 "mile" 3 "invalid" ;
VAL_ 1494 CF_DTE 0 "invalid" 1 "not account" ;
VAL_ 214 AMP_SWVerMajor 255 "Invalid" ;
VAL_ 214 AMP_SWVerMinor 255 "Invalid" ;
VAL_ 214 AMP_CANVerMajor 255 "Invalid" ;
VAL_ 214 AMP_CANVerMinor 255 "Invalid" ;
VAL_ 214 AMP_RBDResult 0 "No Break" 1 "Ring Break" 2 "Weak Signal" 3 "Diagnosis Fail" 7 "Invalid" ;
VAL_ 214 AMP_MOSTErrorDiagResult 0 "No Error" 1 "Sudden Signal Off" 2 "Critical Unlock" 3 "Diagnosis Fail" 7 "Invalid" ;
VAL_ 214 AMP_HWVerMajor 255 "Invalid" ;
VAL_ 214 AMP_HWVerMinor 255 "Invalid" ;
VAL_ 1492 MM_CR_Fatc_AcnComCst_W 1022 "invalid0x3FF" ;
VAL_ 1492 MM_CR_Fatc_PTCPwrCon_W 1001 "Invalid" 1002 "Invalid" 1003 "Invalid" 1004 "Invalid" 1005 "Invalid" 1006 "Invalid" 1007 "Invalid" 1008 "Invalid" 1009 "Invalid" 1010 "Invalid" 1011 "Invalid" 1012 "Invalid" 1013 "Invalid" 1014 "Invalid" 1015 "Invalid" 1016 "Invalid" 1017 "Invalid" 1018 "Invalid" 1019 "Invalid" 1020 "Invalid" 1021 "Invalid" 1022 "Invalid" 1023 "error" ;
VAL_ 1491 MM_CF_Vcu_EvMod 0 "initial" 1 "Vehicle Stop" 2 "EV Propulsion" 3 "Not Used" 4 "Not Used" 5 "Not Used" 6 "Regeneration" 7 "Not Used" 8 "Not Used" 9 "Not Used" 10 "Not Used" 11 "reserved" 12 "reserved" 13 "reserved" 14 "reserved" 15 "invalid" ;
VAL_ 1491 MM_CF_Vcu_GarSelDisp 0 "P" 1 "L" 2 "Eco" 3 "not used" 4 "not used" 5 "D" 6 "N" 7 "R" 8 "not used" 9 "not used" 10 "sub-rom comm" 11 "sub-rom comm error" 12 "reserved" 13 "reserved" 14 "Intermediate Position" 15 "fault" ;
VAL_ 1491 MM_CF_Vcu_ThiBatTir 0 "Thin Tire" 1 "Thick Tire" ;
VAL_ 1491 CR_Mcu_MotEstTqPc 1000 "Reserved" 1001 "Reserved" 1002 "Reserved" 1003 "Reserved" 1004 "Reserved" 1005 "Reserved" 1006 "Reserved" 1007 "Reserved" 1008 "Reserved" 1009 "Reserved" 1010 "Reserved" 1011 "Reserved" 1012 "Reserved" 1013 "Reserved" 1014 "Reserved" 1015 "Reserved" 1016 "Reserved" 1017 "Reserved" 1018 "Reserved" 1019 "Reserved" 1020 "Reserved" 1021 "Reserved" 1022 "Reserved" 1023 "invalid" ;
VAL_ 1490 MM_CR_Vcu_EcoSco 0 "Level 1" 1 "Level 2" 2 "Level 3" 3 "Level 4" 4 "Level 5" 5 "Level 6" 6 "Level 7" 14 "Level 8" ;
VAL_ 1490 MM_CF_Vcu_PgmRun5 0 "(PH) = (HEX)" 1 "(PH) = (HEX)" 2 "(PH) = (HEX)" ;
VAL_ 1490 MM_CR_Clu_Odometer_kph 16777214 "invalid" 16777215 "error" ;
VAL_ 465 CF_Clu_EVDTEDisp 0 "Valid DTE 0" 511 "Invalid" ;
VAL_ 465 CF_Clu_GasDTEDisp 0 "Valid DTE 0" 1023 "Invalid" ;
VAL_ 465 MM_CR_Clu_TotalDTEDisp 0 "Valid DTE 0" 1279 "Invalid" ;
VAL_ 465 CF_Clu_TripUnit 0 "Not Used" 1 "km" 2 "mile" 3 "Invalid" ;
VAL_ 1488 MM_CR_Mcu_VehSpd_Kph 255 "Invalid" ;
VAL_ 1488 MM_CR_Vcu_TqMotClu_Pc 255 "invalid" ;
VAL_ 1488 MM_CR_Bms_DrvEnaDist 255 "invalid" ;
VAL_ 1488 MM_CR_Clu_Soc_Seg 0 "Seg 0" 1 "Seg 1" 2 "Seg 2" 3 "Seg 3" 4 "Seg 4" 5 "Seg 5" 6 "Seg 6" 7 "Seg 7" 8 "Seg 8" 9 "Reserved" 10 "Reserved" 11 "Reserved" 12 "Reserved" 13 "Reserved" 14 "Reserved" 15 "Reserved" 16 "Reserved" 17 "Reserved" 18 "Reserved" 19 "Reserved" 20 "Reserved" 21 "Reserved" 22 "Reserved" 23 "Reserved" 24 "Reserved" 25 "Reserved" 26 "Reserved" 27 "Reserved" 28 "Reserved" 29 "Reserved" 30 "Reserved" 31 "Invalid" ;
VAL_ 208 CLU_SWVerMajor 255 "Invalid" ;
VAL_ 208 CLU_SWVerMinor 255 "Invalid" ;
VAL_ 208 CLU_CANVerMajor 255 "Invalid" ;
VAL_ 208 CLU_CANVerMinor 255 "Invalid" ;
VAL_ 208 CLU_HWVerMajor 255 "Invalid" ;
VAL_ 208 CLU_HWVerMinor 255 "Invalid" ;
VAL_ 448 DATC_AqsLevelChg 0 "Off" 1 "0 level" 2 "1 level" 3 "2 level" 4 "3 level" 5 "4 level" 6 "5 level" 7 "not used" 8 "not used" 9 "not used" 10 "not used" 11 "not used" 12 "not used" 13 "not used" 14 "not used" 15 "invalid" ;
VAL_ 448 RSELockOnOff 0 "0ff" 1 "LockOn" 2 "Reserved" 3 "Invalid" ;
VAL_ 448 DATC_AqsMode 0 "not Active Aqs Mode" 1 "Active Aqs Mode" 2 "not used" 3 "invalid" ;
VAL_ 448 HU_Graphreset_Info 0 "No Action" 1 "Clear Request" 2 "Reserved" 3 "Invalid" ;
VAL_ 448 HU_VRActivity 0 "Deactivated" 1 "Activated" 2 "reserved" 3 "Invalid" ;
VAL_ 448 HU_PhoneActivity 0 "Deactivated" 1 "Activated" 2 "reserved" 3 "Invalid" ;
VAL_ 448 BlowerNoiseControl 0 "Off" 1 "Blower Noise Control On" 2 "reserved" 3 "Invalid" ;
VAL_ 432 C_DATCOnOffReq 0 "Off" 1 "On" 2 "reseved" 3 "invalid" ;
VAL_ 432 C_DATCTempUnit 0 "Centigrade (C)" 1 "Fahrenheit (F)" 2 "reseved" 3 "invalid" ;
VAL_ 432 C_DATCTempSet 0 "Blank" 1 "Display" 2 "Centi=(HEX)*0.5+16Fahr=(HEX)+60" 3 "Centi=(HEX)*0.5+16Fahr=(HEX)+60" 4 "Centi=(HEX)*0.5+16Fahr=(HEX)+60" 5 "Centi=(HEX)*0.5+16Fahr=(HEX)+60" 6 "Centi=(HEX)*0.5+16Fahr=(HEX)+60" 7 "Centi=(HEX)*0.5+16Fahr=(HEX)+60" 8 "Centi=(HEX)*0.5+16Fahr=(HEX)+60" 9 "Centi=(HEX)*0.5+16Fahr=(HEX)+60" 10 "Centi=(HEX)*0.5+16Fahr=(HEX)+60" 11 "Centi=(HEX)*0.5+16Fahr=(HEX)+60" 12 "Centi=(HEX)*0.5+16Fahr=(HEX)+60" 13 "Centi=(HEX)*0.5+16Fahr=(HEX)+60" 14 "Centi=(HEX)*0.5+16Fahr=(HEX)+60" 15 "Centi=(HEX)*0.5+16Fahr=(HEX)+60" 16 "Centi=(HEX)*0.5+16Fahr=(HEX)+60" 17 "Centi=(HEX)*0.5+16Fahr=(HEX)+60" 18 "Centi=(HEX)*0.5+16Fahr=(HEX)+60" 19 "Centi=(HEX)*0.5+16Fahr=(HEX)+60" 20 "Centi=(HEX)*0.5+16Fahr=(HEX)+60" 21 "Centi=(HEX)*0.5+16Fahr=(HEX)+60" 22 "Centi=(HEX)*0.5+16Fahr=(HEX)+60" 23 "Centi=(HEX)*0.5+16Fahr=(HEX)+60" 24 "Centi=(HEX)*0.5+16Fahr=(HEX)+60" 25 "Centi=(HEX)*0.5+16Fahr=(HEX)+60" 26 "Centi=(HEX)*0.5+16Fahr=(HEX)+60" 27 "Centi=(HEX)*0.5+16Fahr=(HEX)+60" 28 "Centi=(HEX)*0.5+16Fahr=(HEX)+60" 29 "Centi=(HEX)*0.5+16Fahr=(HEX)+60" 30 "Centi=(HEX)*0.5+16Fahr=(HEX)+60" 31 "Centi=(HEX)*0.5+16Fahr=(HEX)+60" 32 "Centi=(HEX)*0.5+16Fahr=(HEX)+60" 255 "Invalid" ;
VAL_ 432 TMU_IVRActivity 0 "Deactivated" 1 "Activated" 2 "reserved" 3 "Invalid" ;
VAL_ 432 TMU_PhoneActivity 0 "Deactivated" 1 "Activated" 2 "reserved" 3 "Invalid" ;
VAL_ 410 VCDC_SelDiscNo 0 "Off" 1 "Disc1" 2 "Disc2" 3 "Disc3" 4 "Disc4" 5 "Disc5" 6 "DISC6" 7 "reserved" 8 "reserved" 9 "reserved" 10 "reserved" 11 "reserved" 12 "reserved" 13 "reserved" 14 "reserved" 15 "Invalid" ;
VAL_ 410 VCDC_TrackChapterNo 1023 "Invalid(other value" ;
VAL_ 410 VCDC_PlayTime 0 "Off" 16777215 "Invalid" ;
VAL_ 410 MLT_PlayTime 0 "Off" 16777215 "Invalid" ;
VAL_ 407 HU_LanguageInfo 0 "Off" 1 "Korea" 2 "English(US)" 3 "English(UK)" 4 "Chiness(Mandarin)" 5 "Chiness(Cantonese)" 6 "French(EU)" 7 "Spanish(EU)" 8 "Arabic" 9 "Czech" 10 "Danish" 11 "German" 12 "Italian" 13 "Dutch" 14 "Polish" 15 "Portuguese" 16 "Russain" 17 "Slovak" 18 "Swedish" 19 "Turkish" 255 "Invalid" 20 "French(US)" 21 "Spanish(US)" 22 "English(India)" 23 "Norwegian" 24 "Finnish" 25 "Indonesian" 26 "Arabic" 27 "Malay" 28 "simplified chinese(Mandarin)" ;
VAL_ 407 HU_MuteStatus 0 "Off" 1 "Mute On" 2 "reserved" 3 "Invalid" ;
VAL_ 407 HU_VolumeStatus 63 "Invalid" ;
VAL_ 407 HU_NaviDisp 0 "Non_Navi" 1 "Navi" 2 "reserved" 3 "Invalid" ;
VAL_ 407 HU_NaviStatus 0 "Booting" 1 "Normal Operation" 2 "No SD Card(Map)" 3 "Invalid" ;
VAL_ 407 HU_DistanceUnit 0 "reserved" 1 "Kilometer" 2 "Mile" 3 "Invalid" ;
VAL_ 407 HU_Navigation_On_Off 0 "Off" 1 "On" 2 "Reserved" 3 "Invalid" ;
VAL_ 406 C_SDARS_ChannelNo 0 "Off" 255 "Invalid" ;
VAL_ 406 C_NaviRouteGuidance 0 "off" 1 "Route on" 2 "reserved" 3 "invalid" ;
VAL_ 406 HD_SPS_ChannelNo 0 "Off" 1 "HD" 2 "HD1" 3 "HD2" 4 "HD3" 5 "HD4" 6 "HD5" 7 "HD6" 8 "HD7" 9 "HD8" 10 "reserved" 11 "reserved" 12 "reserved" 13 "reserved" 14 "reserved" 15 "Invalid" ;
VAL_ 406 C_SDARS_PresetNo 0 "off" 1 "preset1" 2 "preset2" 3 "preset3" 4 "preset4" 5 "preset5" 6 "preset6" 7 "preset7" 8 "preset8" 9 "Reserved" 10 "Reserved" 11 "Reserved" 12 "Reserved" 13 "Reserved" 14 "Reserved" 15 "invalid" ;
VAL_ 406 DAB_ServiceFollowing 0 "OFF" 1 "FM" 2 "DAB" 3 "Invalid" ;
VAL_ 406 SXM_ChannelNo 1023 "Invalid" ;
VAL_ 405 HU_IntegPresetNum 0 "Off" 255 "Invalid" ;
VAL_ 405 Radio_Area 0 "OFF" 1 "Korea" 2 "USA" 3 "Europe" 4 "Japan" 5 "China" 6 "Reserved" 7 "invalid" ;
VAL_ 405 DMB_PresetNo 0 "off" 1 "preset1" 16 "preset16" 31 "invalid" 2 "preset2" 3 "preset3" 4 "preset4" 5 "preset5" 6 "preset6" 7 "preset7" 8 "preset8" 9 "preset9" 10 "preset10" 11 "preset11" 12 "preset12" 13 "preset13" 14 "preset14" 15 "preset15" ;
VAL_ 405 RADIO_PresetNo 0 "off" 1 "preset1" 16 "preset16" 31 "invalid" 2 "preset2" 3 "preset3" 4 "preset4" 5 "preset5" 6 "preset6" 7 "preset7" 8 "preset8" 9 "preset9" 10 "preset10" 11 "preset11" 12 "preset12" 13 "preset13" 14 "preset14" 15 "preset15" ;
VAL_ 405 HU_Opstate_DIS2 0 "Initial" 1 "Apps" 2 "Not Used" 3 "Not Used" 4 "Internet" 5 "Not Used" 6 "Not Used" 7 "Juke Box" 8 "Bluetooth Audio" 9 "NAVI TBT" 10 "AV Off" 11 "AV PWR Off" 12 "Not Used" 13 "Pandora" 14 "Display Navi" 17 "FM" 18 "Not Used" 19 "Not Used" 20 "AM" 21 "Not Used" 22 "Not USed" 23 "BSMing" 24 "Not Used" 25 "Not Used" 26 "Emergency Call" 27 "ACN" 28 "Center Call" 29 "BluelinkAssistant" 30 "Reserved" 31 "Reserved" 32 "Reserved" 33 "FM(HD)" 34 "Not Used" 35 "Not Used" 36 "AM(HD)" 37 "Reserved" 38 "Reserved" 39 "Reserved" 40 "Reserved" 41 "Reserved" 42 "Mozen Incomming Call" 43 "Mozen Active Call" 44 "Mozen HangUp" 45 "Mozen Outgoinng Call" 46 "Reserved" 47 "Reserved" 49 "XM" 50 "Not Used" 51 "Not Used" 52 "Not Used" 53 "Reserved" 54 "DAB" 55 "Not Used" 56 "Not Used" 57 "Not Used" 58 "Not Used" 59 "D-radio Receiving" 60 "D-radio Singal Weak" 61 "D-radio SIgnal Lost" 62 "DAB Receiving" 63 "DAT Signal Weak" 64 "Reserved" 65 "Not Used" 66 "Not Used" 67 "Not Used" 68 "Not Used" 69 "DMB TV" 70 "DMB Radio" 71 "DMB Searching" 72 "Reserved" 73 "Reserved" 74 "D-TV No Channel" 75 "D-TV Receiving" 76 "D-TV SIgnal Weak" 77 "D-TV SIngal Lost" 78 "Not Used" 79 "Not Used" 80 "CD" 81 "CD Audio" 82 "CD MP3" 83 "Not Used" 84 "DVD-V" 85 "VCD" 86 "Not Used" 87 "Not Used" 88 "Not Used" 89 "DISC Reading" 90 "Not Used" 91 "Not Used" 92 "Not Used" 93 "Not Used" 94 "Not Used" 95 "DISC Error" 96 "Not Used" 97 "iPod" 98 "Rear USB Video" 99 "Rear USE Audio" 100 "USB Video" 101 "USB Music" 102 "Not Used" 103 "Not Used" 104 "IPOD Reading" 105 "USB Reading" 106 "Not Used" 107 "AUX_Audio" 108 "AUX-Video" 109 "Not Used" 110 "iOS in the Car" 111 "iOS in the Loading" 113 "Incomming Call" 114 "Acrive Call" 115 "Hang Up" 116 "Last Call" 117 "Not Used" 118 "Not Used" 119 "Not Used" 120 "Not Used" 121 "Not Used" 122 "Not Used" 123 "Not Used" 124 "Reserved" 125 "Reserved" 126 "Reserved" 127 "Invalid" ;
